VERSION ""

NS_ :

BS_:
BU_: MRR

BO_ 298 MRR_Detection_011: 64 MRR
   SG_ CAN_DET_CONFID_AZIMUTH_11_01 : 33|2@0+ (1,0) [0|3] "" IFV_VFP
   SG_ CAN_DET_SUPER_RES_TARGET_11_01 : 56|1@0+ (1,0) [0|1] "" IFV_VFP
   SG_ CAN_DET_NEW_SIGNAL_11_01 : 62|6@0+ (1,0) [0|64] "" IFV_VFP
   SG_ CAN_DET_ND_TARGET_11_01 : 48|1@0+ (1,0) [0|1] "" IFV_VFP
   SG_ CAN_DET_HOST_VEH_CLUTTER_11_01 : 49|1@0+ (1,0) [0|1] "" IFV_VFP
   SG_ CAN_DET_VALID_LEVEL_11_01 : 0|1@0+ (1,0) [0|1] "" IFV_VFP
   SG_ CAN_DET_AZIMUTH_11_01 : 47|14@0+ (0.0003834,-3.1416) [-3.1416|3.13964] "rad" IFV_VFP
   SG_ CAN_DET_RANGE_11_01 : 31|14@0+ (0.015625,0) [0|255.984] "m" IFV_VFP
   SG_ CAN_DET_RANGE_RATE_11_01 : 15|14@0+ (0.015625,-128) [-128|127.984] "m/s" IFV_VFP
   SG_ CAN_DET_AMPLITUDE_11_01 : 7|7@0+ (1,-64) [-64|63] "dBsm" IFV_VFP
   SG_ CAN_SCAN_INDEX_2LSB_11_01 : 17|2@0+ (1,0) [0|3] "" IFV_VFP
   SG_ CAN_DET_CONFID_AZIMUTH_11_02 : 105|2@0+ (1,0) [0|3] "" IFV_VFP
   SG_ CAN_DET_SUPER_RES_TARGET_11_02 : 128|1@0+ (1,0) [0|1] "" IFV_VFP
   SG_ CAN_DET_NEW_SIGNAL_11_02 : 134|6@0+ (1,0) [0|64] "" IFV_VFP
   SG_ CAN_DET_ND_TARGET_11_02 : 120|1@0+ (1,0) [0|1] "" IFV_VFP
   SG_ CAN_DET_HOST_VEH_CLUTTER_11_02 : 121|1@0+ (1,0) [0|1] "" IFV_VFP
   SG_ CAN_DET_VALID_LEVEL_11_02 : 72|1@0+ (1,0) [0|1] "" IFV_VFP
   SG_ CAN_DET_AZIMUTH_11_02 : 119|14@0+ (0.0003834,-3.1416) [-3.1416|3.13964] "rad" IFV_VFP
   SG_ CAN_DET_RANGE_11_02 : 103|14@0+ (0.015625,0) [0|255.984] "m" IFV_VFP
   SG_ CAN_DET_RANGE_RATE_11_02 : 87|14@0+ (0.015625,-128) [-128|127.984] "m/s" IFV_VFP
   SG_ CAN_DET_AMPLITUDE_11_02 : 79|7@0+ (1,-64) [-64|63] "dBsm" IFV_VFP
   SG_ CAN_SCAN_INDEX_2LSB_11_02 : 89|2@0+ (1,0) [0|3] "" IFV_VFP
   SG_ CAN_DET_CONFID_AZIMUTH_11_03 : 177|2@0+ (1,0) [0|3] "" IFV_VFP
   SG_ CAN_DET_SUPER_RES_TARGET_11_03 : 200|1@0+ (1,0) [0|1] "" IFV_VFP
   SG_ CAN_DET_NEW_SIGNAL_11_03 : 206|6@0+ (1,0) [0|64] "" IFV_VFP
   SG_ CAN_DET_ND_TARGET_11_03 : 192|1@0+ (1,0) [0|1] "" IFV_VFP
   SG_ CAN_DET_HOST_VEH_CLUTTER_11_03 : 193|1@0+ (1,0) [0|1] "" IFV_VFP
   SG_ CAN_DET_VALID_LEVEL_11_03 : 144|1@0+ (1,0) [0|1] "" IFV_VFP
   SG_ CAN_DET_AZIMUTH_11_03 : 191|14@0+ (0.0003834,-3.1416) [-3.1416|3.13964] "rad" IFV_VFP
   SG_ CAN_DET_RANGE_11_03 : 175|14@0+ (0.015625,0) [0|255.984] "m" IFV_VFP
   SG_ CAN_DET_RANGE_RATE_11_03 : 159|14@0+ (0.015625,-128) [-128|127.984] "m/s" IFV_VFP
   SG_ CAN_DET_AMPLITUDE_11_03 : 151|7@0+ (1,-64) [-64|63] "dBsm" IFV_VFP
   SG_ CAN_SCAN_INDEX_2LSB_11_03 : 161|2@0+ (1,0) [0|3] "" IFV_VFP
   SG_ CAN_DET_CONFID_AZIMUTH_11_04 : 249|2@0+ (1,0) [0|3] "" IFV_VFP
   SG_ CAN_DET_SUPER_RES_TARGET_11_04 : 272|1@0+ (1,0) [0|1] "" IFV_VFP
   SG_ CAN_DET_NEW_SIGNAL_11_04 : 278|6@0+ (1,0) [0|64] "" IFV_VFP
   SG_ CAN_DET_ND_TARGET_11_04 : 264|1@0+ (1,0) [0|1] "" IFV_VFP
   SG_ CAN_DET_HOST_VEH_CLUTTER_11_04 : 265|1@0+ (1,0) [0|1] "" IFV_VFP
   SG_ CAN_DET_VALID_LEVEL_11_04 : 216|1@0+ (1,0) [0|1] "" IFV_VFP
   SG_ CAN_DET_AZIMUTH_11_04 : 263|14@0+ (0.0003834,-3.1416) [-3.1416|3.13964] "rad" IFV_VFP
   SG_ CAN_DET_RANGE_11_04 : 247|14@0+ (0.015625,0) [0|255.984] "m" IFV_VFP
   SG_ CAN_DET_RANGE_RATE_11_04 : 231|14@0+ (0.015625,-128) [-128|127.984] "m/s" IFV_VFP
   SG_ CAN_DET_AMPLITUDE_11_04 : 223|7@0+ (1,-64) [-64|63] "dBsm" IFV_VFP
   SG_ CAN_SCAN_INDEX_2LSB_11_04 : 233|2@0+ (1,0) [0|3] "" IFV_VFP
   SG_ CAN_DET_CONFID_AZIMUTH_11_05 : 321|2@0+ (1,0) [0|3] "" IFV_VFP
   SG_ CAN_DET_SUPER_RES_TARGET_11_05 : 344|1@0+ (1,0) [0|1] "" IFV_VFP
   SG_ CAN_DET_NEW_SIGNAL_11_05 : 350|6@0+ (1,0) [0|64] "" IFV_VFP
   SG_ CAN_DET_ND_TARGET_11_05 : 336|1@0+ (1,0) [0|1] "" IFV_VFP
   SG_ CAN_DET_HOST_VEH_CLUTTER_11_05 : 337|1@0+ (1,0) [0|1] "" IFV_VFP
   SG_ CAN_DET_VALID_LEVEL_11_05 : 288|1@0+ (1,0) [0|1] "" IFV_VFP
   SG_ CAN_DET_AZIMUTH_11_05 : 335|14@0+ (0.0003834,-3.1416) [-3.1416|3.13964] "rad" IFV_VFP
   SG_ CAN_DET_RANGE_11_05 : 319|14@0+ (0.015625,0) [0|255.984] "m" IFV_VFP
   SG_ CAN_DET_RANGE_RATE_11_05 : 303|14@0+ (0.015625,-128) [-128|127.984] "m/s" IFV_VFP
   SG_ CAN_DET_AMPLITUDE_11_05 : 295|7@0+ (1,-64) [-64|63] "dBsm" IFV_VFP
   SG_ CAN_SCAN_INDEX_2LSB_11_05 : 305|2@0+ (1,0) [0|3] "" IFV_VFP
   SG_ CAN_DET_CONFID_AZIMUTH_11_06 : 393|2@0+ (1,0) [0|3] "" IFV_VFP
   SG_ CAN_DET_SUPER_RES_TARGET_11_06 : 416|1@0+ (1,0) [0|1] "" IFV_VFP
   SG_ CAN_DET_NEW_SIGNAL_11_06 : 422|6@0+ (1,0) [0|64] "" IFV_VFP
   SG_ CAN_DET_ND_TARGET_11_06 : 408|1@0+ (1,0) [0|1] "" IFV_VFP
   SG_ CAN_DET_HOST_VEH_CLUTTER_11_06 : 409|1@0+ (1,0) [0|1] "" IFV_VFP
   SG_ CAN_DET_VALID_LEVEL_11_06 : 360|1@0+ (1,0) [0|1] "" IFV_VFP
   SG_ CAN_DET_AZIMUTH_11_06 : 407|14@0+ (0.0003834,-3.1416) [-3.1416|3.13964] "rad" IFV_VFP
   SG_ CAN_DET_RANGE_11_06 : 391|14@0+ (0.015625,0) [0|255.984] "m" IFV_VFP
   SG_ CAN_DET_RANGE_RATE_11_06 : 375|14@0+ (0.015625,-128) [-128|127.984] "m/s" IFV_VFP
   SG_ CAN_DET_AMPLITUDE_11_06 : 367|7@0+ (1,-64) [-64|63] "dBsm" IFV_VFP
   SG_ CAN_SCAN_INDEX_2LSB_11_06 : 377|2@0+ (1,0) [0|3] "" IFV_VFP

BO_ 297 MRR_Detection_010: 64 MRR
   SG_ CAN_DET_CONFID_AZIMUTH_10_01 : 33|2@0+ (1,0) [0|3] "" IFV_VFP
   SG_ CAN_DET_SUPER_RES_TARGET_10_01 : 56|1@0+ (1,0) [0|1] "" IFV_VFP
   SG_ CAN_DET_NEW_SIGNAL_10_01 : 62|6@0+ (1,0) [0|64] "" IFV_VFP
   SG_ CAN_DET_ND_TARGET_10_01 : 48|1@0+ (1,0) [0|1] "" IFV_VFP
   SG_ CAN_DET_HOST_VEH_CLUTTER_10_01 : 49|1@0+ (1,0) [0|1] "" IFV_VFP
   SG_ CAN_DET_VALID_LEVEL_10_01 : 0|1@0+ (1,0) [0|1] "" IFV_VFP
   SG_ CAN_DET_AZIMUTH_10_01 : 47|14@0+ (0.0003834,-3.1416) [-3.1416|3.13964] "rad" IFV_VFP
   SG_ CAN_DET_RANGE_10_01 : 31|14@0+ (0.015625,0) [0|255.984] "m" IFV_VFP
   SG_ CAN_DET_RANGE_RATE_10_01 : 15|14@0+ (0.015625,-128) [-128|127.984] "m/s" IFV_VFP
   SG_ CAN_DET_AMPLITUDE_10_01 : 7|7@0+ (1,-64) [-64|63] "dBsm" IFV_VFP
   SG_ CAN_SCAN_INDEX_2LSB_10_01 : 17|2@0+ (1,0) [0|3] "" IFV_VFP
   SG_ CAN_DET_CONFID_AZIMUTH_10_02 : 105|2@0+ (1,0) [0|3] "" IFV_VFP
   SG_ CAN_DET_SUPER_RES_TARGET_10_02 : 128|1@0+ (1,0) [0|1] "" IFV_VFP
   SG_ CAN_DET_NEW_SIGNAL_10_02 : 134|6@0+ (1,0) [0|64] "" IFV_VFP
   SG_ CAN_DET_ND_TARGET_10_02 : 120|1@0+ (1,0) [0|1] "" IFV_VFP
   SG_ CAN_DET_HOST_VEH_CLUTTER_10_02 : 121|1@0+ (1,0) [0|1] "" IFV_VFP
   SG_ CAN_DET_VALID_LEVEL_10_02 : 72|1@0+ (1,0) [0|1] "" IFV_VFP
   SG_ CAN_DET_AZIMUTH_10_02 : 119|14@0+ (0.0003834,-3.1416) [-3.1416|3.13964] "rad" IFV_VFP
   SG_ CAN_DET_RANGE_10_02 : 103|14@0+ (0.015625,0) [0|255.984] "m" IFV_VFP
   SG_ CAN_DET_RANGE_RATE_10_02 : 87|14@0+ (0.015625,-128) [-128|127.984] "m/s" IFV_VFP
   SG_ CAN_DET_AMPLITUDE_10_02 : 79|7@0+ (1,-64) [-64|63] "dBsm" IFV_VFP
   SG_ CAN_SCAN_INDEX_2LSB_10_02 : 89|2@0+ (1,0) [0|3] "" IFV_VFP
   SG_ CAN_DET_CONFID_AZIMUTH_10_03 : 177|2@0+ (1,0) [0|3] "" IFV_VFP
   SG_ CAN_DET_SUPER_RES_TARGET_10_03 : 200|1@0+ (1,0) [0|1] "" IFV_VFP
   SG_ CAN_DET_NEW_SIGNAL_10_03 : 206|6@0+ (1,0) [0|64] "" IFV_VFP
   SG_ CAN_DET_ND_TARGET_10_03 : 192|1@0+ (1,0) [0|1] "" IFV_VFP
   SG_ CAN_DET_HOST_VEH_CLUTTER_10_03 : 193|1@0+ (1,0) [0|1] "" IFV_VFP
   SG_ CAN_DET_VALID_LEVEL_10_03 : 144|1@0+ (1,0) [0|1] "" IFV_VFP
   SG_ CAN_DET_AZIMUTH_10_03 : 191|14@0+ (0.0003834,-3.1416) [-3.1416|3.13964] "rad" IFV_VFP
   SG_ CAN_DET_RANGE_10_03 : 175|14@0+ (0.015625,0) [0|255.984] "m" IFV_VFP
   SG_ CAN_DET_RANGE_RATE_10_03 : 159|14@0+ (0.015625,-128) [-128|127.984] "m/s" IFV_VFP
   SG_ CAN_DET_AMPLITUDE_10_03 : 151|7@0+ (1,-64) [-64|63] "dBsm" IFV_VFP
   SG_ CAN_SCAN_INDEX_2LSB_10_03 : 161|2@0+ (1,0) [0|3] "" IFV_VFP
   SG_ CAN_DET_CONFID_AZIMUTH_10_04 : 249|2@0+ (1,0) [0|3] "" IFV_VFP
   SG_ CAN_DET_SUPER_RES_TARGET_10_04 : 272|1@0+ (1,0) [0|1] "" IFV_VFP
   SG_ CAN_DET_NEW_SIGNAL_10_04 : 278|6@0+ (1,0) [0|64] "" IFV_VFP
   SG_ CAN_DET_ND_TARGET_10_04 : 264|1@0+ (1,0) [0|1] "" IFV_VFP
   SG_ CAN_DET_HOST_VEH_CLUTTER_10_04 : 265|1@0+ (1,0) [0|1] "" IFV_VFP
   SG_ CAN_DET_VALID_LEVEL_10_04 : 216|1@0+ (1,0) [0|1] "" IFV_VFP
   SG_ CAN_DET_AZIMUTH_10_04 : 263|14@0+ (0.0003834,-3.1416) [-3.1416|3.13964] "rad" IFV_VFP
   SG_ CAN_DET_RANGE_10_04 : 247|14@0+ (0.015625,0) [0|255.984] "m" IFV_VFP
   SG_ CAN_DET_RANGE_RATE_10_04 : 231|14@0+ (0.015625,-128) [-128|127.984] "m/s" IFV_VFP
   SG_ CAN_DET_AMPLITUDE_10_04 : 223|7@0+ (1,-64) [-64|63] "dBsm" IFV_VFP
   SG_ CAN_SCAN_INDEX_2LSB_10_04 : 233|2@0+ (1,0) [0|3] "" IFV_VFP
   SG_ CAN_DET_CONFID_AZIMUTH_10_05 : 321|2@0+ (1,0) [0|3] "" IFV_VFP
   SG_ CAN_DET_SUPER_RES_TARGET_10_05 : 344|1@0+ (1,0) [0|1] "" IFV_VFP
   SG_ CAN_DET_NEW_SIGNAL_10_05 : 350|6@0+ (1,0) [0|64] "" IFV_VFP
   SG_ CAN_DET_ND_TARGET_10_05 : 336|1@0+ (1,0) [0|1] "" IFV_VFP
   SG_ CAN_DET_HOST_VEH_CLUTTER_10_05 : 337|1@0+ (1,0) [0|1] "" IFV_VFP
   SG_ CAN_DET_VALID_LEVEL_10_05 : 288|1@0+ (1,0) [0|1] "" IFV_VFP
   SG_ CAN_DET_AZIMUTH_10_05 : 335|14@0+ (0.0003834,-3.1416) [-3.1416|3.13964] "rad" IFV_VFP
   SG_ CAN_DET_RANGE_10_05 : 319|14@0+ (0.015625,0) [0|255.984] "m" IFV_VFP
   SG_ CAN_DET_RANGE_RATE_10_05 : 303|14@0+ (0.015625,-128) [-128|127.984] "m/s" IFV_VFP
   SG_ CAN_DET_AMPLITUDE_10_05 : 295|7@0+ (1,-64) [-64|63] "dBsm" IFV_VFP
   SG_ CAN_SCAN_INDEX_2LSB_10_05 : 305|2@0+ (1,0) [0|3] "" IFV_VFP
   SG_ CAN_DET_CONFID_AZIMUTH_10_06 : 393|2@0+ (1,0) [0|3] "" IFV_VFP
   SG_ CAN_DET_SUPER_RES_TARGET_10_06 : 416|1@0+ (1,0) [0|1] "" IFV_VFP
   SG_ CAN_DET_NEW_SIGNAL_10_06 : 422|6@0+ (1,0) [0|64] "" IFV_VFP
   SG_ CAN_DET_ND_TARGET_10_06 : 408|1@0+ (1,0) [0|1] "" IFV_VFP
   SG_ CAN_DET_HOST_VEH_CLUTTER_10_06 : 409|1@0+ (1,0) [0|1] "" IFV_VFP
   SG_ CAN_DET_VALID_LEVEL_10_06 : 360|1@0+ (1,0) [0|1] "" IFV_VFP
   SG_ CAN_DET_AZIMUTH_10_06 : 407|14@0+ (0.0003834,-3.1416) [-3.1416|3.13964] "rad" IFV_VFP
   SG_ CAN_DET_RANGE_10_06 : 391|14@0+ (0.015625,0) [0|255.984] "m" IFV_VFP
   SG_ CAN_DET_RANGE_RATE_10_06 : 375|14@0+ (0.015625,-128) [-128|127.984] "m/s" IFV_VFP
   SG_ CAN_DET_AMPLITUDE_10_06 : 367|7@0+ (1,-64) [-64|63] "dBsm" IFV_VFP
   SG_ CAN_SCAN_INDEX_2LSB_10_06 : 377|2@0+ (1,0) [0|3] "" IFV_VFP

BO_ 296 MRR_Detection_009: 64 MRR
   SG_ CAN_DET_CONFID_AZIMUTH_09_01 : 33|2@0+ (1,0) [0|3] "" IFV_VFP
   SG_ CAN_DET_SUPER_RES_TARGET_09_01 : 56|1@0+ (1,0) [0|1] "" IFV_VFP
   SG_ CAN_DET_NEW_SIGNAL_09_01 : 62|6@0+ (1,0) [0|64] "" IFV_VFP
   SG_ CAN_DET_ND_TARGET_09_01 : 48|1@0+ (1,0) [0|1] "" IFV_VFP
   SG_ CAN_DET_HOST_VEH_CLUTTER_09_01 : 49|1@0+ (1,0) [0|1] "" IFV_VFP
   SG_ CAN_DET_VALID_LEVEL_09_01 : 0|1@0+ (1,0) [0|1] "" IFV_VFP
   SG_ CAN_DET_AZIMUTH_09_01 : 47|14@0+ (0.0003834,-3.1416) [-3.1416|3.13964] "rad" IFV_VFP
   SG_ CAN_DET_RANGE_09_01 : 31|14@0+ (0.015625,0) [0|255.984] "m" IFV_VFP
   SG_ CAN_DET_RANGE_RATE_09_01 : 15|14@0+ (0.015625,-128) [-128|127.984] "m/s" IFV_VFP
   SG_ CAN_DET_AMPLITUDE_09_01 : 7|7@0+ (1,-64) [-64|63] "dBsm" IFV_VFP
   SG_ CAN_SCAN_INDEX_2LSB_09_01 : 17|2@0+ (1,0) [0|3] "" IFV_VFP
   SG_ CAN_DET_CONFID_AZIMUTH_09_02 : 105|2@0+ (1,0) [0|3] "" IFV_VFP
   SG_ CAN_DET_SUPER_RES_TARGET_09_02 : 128|1@0+ (1,0) [0|1] "" IFV_VFP
   SG_ CAN_DET_NEW_SIGNAL_09_02 : 134|6@0+ (1,0) [0|64] "" IFV_VFP
   SG_ CAN_DET_ND_TARGET_09_02 : 120|1@0+ (1,0) [0|1] "" IFV_VFP
   SG_ CAN_DET_HOST_VEH_CLUTTER_09_02 : 121|1@0+ (1,0) [0|1] "" IFV_VFP
   SG_ CAN_DET_VALID_LEVEL_09_02 : 72|1@0+ (1,0) [0|1] "" IFV_VFP
   SG_ CAN_DET_AZIMUTH_09_02 : 119|14@0+ (0.0003834,-3.1416) [-3.1416|3.13964] "rad" IFV_VFP
   SG_ CAN_DET_RANGE_09_02 : 103|14@0+ (0.015625,0) [0|255.984] "m" IFV_VFP
   SG_ CAN_DET_RANGE_RATE_09_02 : 87|14@0+ (0.015625,-128) [-128|127.984] "m/s" IFV_VFP
   SG_ CAN_DET_AMPLITUDE_09_02 : 79|7@0+ (1,-64) [-64|63] "dBsm" IFV_VFP
   SG_ CAN_SCAN_INDEX_2LSB_09_02 : 89|2@0+ (1,0) [0|3] "" IFV_VFP
   SG_ CAN_DET_CONFID_AZIMUTH_09_03 : 177|2@0+ (1,0) [0|3] "" IFV_VFP
   SG_ CAN_DET_SUPER_RES_TARGET_09_03 : 200|1@0+ (1,0) [0|1] "" IFV_VFP
   SG_ CAN_DET_NEW_SIGNAL_09_03 : 206|6@0+ (1,0) [0|64] "" IFV_VFP
   SG_ CAN_DET_ND_TARGET_09_03 : 192|1@0+ (1,0) [0|1] "" IFV_VFP
   SG_ CAN_DET_HOST_VEH_CLUTTER_09_03 : 193|1@0+ (1,0) [0|1] "" IFV_VFP
   SG_ CAN_DET_VALID_LEVEL_09_03 : 144|1@0+ (1,0) [0|1] "" IFV_VFP
   SG_ CAN_DET_AZIMUTH_09_03 : 191|14@0+ (0.0003834,-3.1416) [-3.1416|3.13964] "rad" IFV_VFP
   SG_ CAN_DET_RANGE_09_03 : 175|14@0+ (0.015625,0) [0|255.984] "m" IFV_VFP
   SG_ CAN_DET_RANGE_RATE_09_03 : 159|14@0+ (0.015625,-128) [-128|127.984] "m/s" IFV_VFP
   SG_ CAN_DET_AMPLITUDE_09_03 : 151|7@0+ (1,-64) [-64|63] "dBsm" IFV_VFP
   SG_ CAN_SCAN_INDEX_2LSB_09_03 : 161|2@0+ (1,0) [0|3] "" IFV_VFP
   SG_ CAN_DET_CONFID_AZIMUTH_09_04 : 249|2@0+ (1,0) [0|3] "" IFV_VFP
   SG_ CAN_DET_SUPER_RES_TARGET_09_04 : 272|1@0+ (1,0) [0|1] "" IFV_VFP
   SG_ CAN_DET_NEW_SIGNAL_09_04 : 278|6@0+ (1,0) [0|64] "" IFV_VFP
   SG_ CAN_DET_ND_TARGET_09_04 : 264|1@0+ (1,0) [0|1] "" IFV_VFP
   SG_ CAN_DET_HOST_VEH_CLUTTER_09_04 : 265|1@0+ (1,0) [0|1] "" IFV_VFP
   SG_ CAN_DET_VALID_LEVEL_09_04 : 216|1@0+ (1,0) [0|1] "" IFV_VFP
   SG_ CAN_DET_AZIMUTH_09_04 : 263|14@0+ (0.0003834,-3.1416) [-3.1416|3.13964] "rad" IFV_VFP
   SG_ CAN_DET_RANGE_09_04 : 247|14@0+ (0.015625,0) [0|255.984] "m" IFV_VFP
   SG_ CAN_DET_RANGE_RATE_09_04 : 231|14@0+ (0.015625,-128) [-128|127.984] "m/s" IFV_VFP
   SG_ CAN_DET_AMPLITUDE_09_04 : 223|7@0+ (1,-64) [-64|63] "dBsm" IFV_VFP
   SG_ CAN_SCAN_INDEX_2LSB_09_04 : 233|2@0+ (1,0) [0|3] "" IFV_VFP
   SG_ CAN_DET_CONFID_AZIMUTH_09_05 : 321|2@0+ (1,0) [0|3] "" IFV_VFP
   SG_ CAN_DET_SUPER_RES_TARGET_09_05 : 344|1@0+ (1,0) [0|1] "" IFV_VFP
   SG_ CAN_DET_NEW_SIGNAL_09_05 : 350|6@0+ (1,0) [0|64] "" IFV_VFP
   SG_ CAN_DET_ND_TARGET_09_05 : 336|1@0+ (1,0) [0|1] "" IFV_VFP
   SG_ CAN_DET_HOST_VEH_CLUTTER_09_05 : 337|1@0+ (1,0) [0|1] "" IFV_VFP
   SG_ CAN_DET_VALID_LEVEL_09_05 : 288|1@0+ (1,0) [0|1] "" IFV_VFP
   SG_ CAN_DET_AZIMUTH_09_05 : 335|14@0+ (0.0003834,-3.1416) [-3.1416|3.13964] "rad" IFV_VFP
   SG_ CAN_DET_RANGE_09_05 : 319|14@0+ (0.015625,0) [0|255.984] "m" IFV_VFP
   SG_ CAN_DET_RANGE_RATE_09_05 : 303|14@0+ (0.015625,-128) [-128|127.984] "m/s" IFV_VFP
   SG_ CAN_DET_AMPLITUDE_09_05 : 295|7@0+ (1,-64) [-64|63] "dBsm" IFV_VFP
   SG_ CAN_SCAN_INDEX_2LSB_09_05 : 305|2@0+ (1,0) [0|3] "" IFV_VFP
   SG_ CAN_DET_CONFID_AZIMUTH_09_06 : 393|2@0+ (1,0) [0|3] "" IFV_VFP
   SG_ CAN_DET_SUPER_RES_TARGET_09_06 : 416|1@0+ (1,0) [0|1] "" IFV_VFP
   SG_ CAN_DET_NEW_SIGNAL_09_06 : 422|6@0+ (1,0) [0|64] "" IFV_VFP
   SG_ CAN_DET_ND_TARGET_09_06 : 408|1@0+ (1,0) [0|1] "" IFV_VFP
   SG_ CAN_DET_HOST_VEH_CLUTTER_09_06 : 409|1@0+ (1,0) [0|1] "" IFV_VFP
   SG_ CAN_DET_VALID_LEVEL_09_06 : 360|1@0+ (1,0) [0|1] "" IFV_VFP
   SG_ CAN_DET_AZIMUTH_09_06 : 407|14@0+ (0.0003834,-3.1416) [-3.1416|3.13964] "rad" IFV_VFP
   SG_ CAN_DET_RANGE_09_06 : 391|14@0+ (0.015625,0) [0|255.984] "m" IFV_VFP
   SG_ CAN_DET_RANGE_RATE_09_06 : 375|14@0+ (0.015625,-128) [-128|127.984] "m/s" IFV_VFP
   SG_ CAN_DET_AMPLITUDE_09_06 : 367|7@0+ (1,-64) [-64|63] "dBsm" IFV_VFP
   SG_ CAN_SCAN_INDEX_2LSB_09_06 : 377|2@0+ (1,0) [0|3] "" IFV_VFP

BO_ 295 MRR_Detection_008: 64 MRR
   SG_ CAN_DET_CONFID_AZIMUTH_08_01 : 33|2@0+ (1,0) [0|3] "" IFV_VFP
   SG_ CAN_DET_SUPER_RES_TARGET_08_01 : 56|1@0+ (1,0) [0|1] "" IFV_VFP
   SG_ CAN_DET_NEW_SIGNAL_08_01 : 62|6@0+ (1,0) [0|64] "" IFV_VFP
   SG_ CAN_DET_ND_TARGET_08_01 : 48|1@0+ (1,0) [0|1] "" IFV_VFP
   SG_ CAN_DET_HOST_VEH_CLUTTER_08_01 : 49|1@0+ (1,0) [0|1] "" IFV_VFP
   SG_ CAN_DET_VALID_LEVEL_08_01 : 0|1@0+ (1,0) [0|1] "" IFV_VFP
   SG_ CAN_DET_AZIMUTH_08_01 : 47|14@0+ (0.0003834,-3.1416) [-3.1416|3.13964] "rad" IFV_VFP
   SG_ CAN_DET_RANGE_08_01 : 31|14@0+ (0.015625,0) [0|255.984] "m" IFV_VFP
   SG_ CAN_DET_RANGE_RATE_08_01 : 15|14@0+ (0.015625,-128) [-128|127.984] "m/s" IFV_VFP
   SG_ CAN_DET_AMPLITUDE_08_01 : 7|7@0+ (1,-64) [-64|63] "dBsm" IFV_VFP
   SG_ CAN_SCAN_INDEX_2LSB_08_01 : 17|2@0+ (1,0) [0|3] "" IFV_VFP
   SG_ CAN_DET_CONFID_AZIMUTH_08_02 : 105|2@0+ (1,0) [0|3] "" IFV_VFP
   SG_ CAN_DET_SUPER_RES_TARGET_08_02 : 128|1@0+ (1,0) [0|1] "" IFV_VFP
   SG_ CAN_DET_NEW_SIGNAL_08_02 : 134|6@0+ (1,0) [0|64] "" IFV_VFP
   SG_ CAN_DET_ND_TARGET_08_02 : 120|1@0+ (1,0) [0|1] "" IFV_VFP
   SG_ CAN_DET_HOST_VEH_CLUTTER_08_02 : 121|1@0+ (1,0) [0|1] "" IFV_VFP
   SG_ CAN_DET_VALID_LEVEL_08_02 : 72|1@0+ (1,0) [0|1] "" IFV_VFP
   SG_ CAN_DET_AZIMUTH_08_02 : 119|14@0+ (0.0003834,-3.1416) [-3.1416|3.13964] "rad" IFV_VFP
   SG_ CAN_DET_RANGE_08_02 : 103|14@0+ (0.015625,0) [0|255.984] "m" IFV_VFP
   SG_ CAN_DET_RANGE_RATE_08_02 : 87|14@0+ (0.015625,-128) [-128|127.984] "m/s" IFV_VFP
   SG_ CAN_DET_AMPLITUDE_08_02 : 79|7@0+ (1,-64) [-64|63] "dBsm" IFV_VFP
   SG_ CAN_SCAN_INDEX_2LSB_08_02 : 89|2@0+ (1,0) [0|3] "" IFV_VFP
   SG_ CAN_DET_CONFID_AZIMUTH_08_03 : 177|2@0+ (1,0) [0|3] "" IFV_VFP
   SG_ CAN_DET_SUPER_RES_TARGET_08_03 : 200|1@0+ (1,0) [0|1] "" IFV_VFP
   SG_ CAN_DET_NEW_SIGNAL_08_03 : 206|6@0+ (1,0) [0|64] "" IFV_VFP
   SG_ CAN_DET_ND_TARGET_08_03 : 192|1@0+ (1,0) [0|1] "" IFV_VFP
   SG_ CAN_DET_HOST_VEH_CLUTTER_08_03 : 193|1@0+ (1,0) [0|1] "" IFV_VFP
   SG_ CAN_DET_VALID_LEVEL_08_03 : 144|1@0+ (1,0) [0|1] "" IFV_VFP
   SG_ CAN_DET_AZIMUTH_08_03 : 191|14@0+ (0.0003834,-3.1416) [-3.1416|3.13964] "rad" IFV_VFP
   SG_ CAN_DET_RANGE_08_03 : 175|14@0+ (0.015625,0) [0|255.984] "m" IFV_VFP
   SG_ CAN_DET_RANGE_RATE_08_03 : 159|14@0+ (0.015625,-128) [-128|127.984] "m/s" IFV_VFP
   SG_ CAN_DET_AMPLITUDE_08_03 : 151|7@0+ (1,-64) [-64|63] "dBsm" IFV_VFP
   SG_ CAN_SCAN_INDEX_2LSB_08_03 : 161|2@0+ (1,0) [0|3] "" IFV_VFP
   SG_ CAN_DET_CONFID_AZIMUTH_08_04 : 249|2@0+ (1,0) [0|3] "" IFV_VFP
   SG_ CAN_DET_SUPER_RES_TARGET_08_04 : 272|1@0+ (1,0) [0|1] "" IFV_VFP
   SG_ CAN_DET_NEW_SIGNAL_08_04 : 278|6@0+ (1,0) [0|64] "" IFV_VFP
   SG_ CAN_DET_ND_TARGET_08_04 : 264|1@0+ (1,0) [0|1] "" IFV_VFP
   SG_ CAN_DET_HOST_VEH_CLUTTER_08_04 : 265|1@0+ (1,0) [0|1] "" IFV_VFP
   SG_ CAN_DET_VALID_LEVEL_08_04 : 216|1@0+ (1,0) [0|1] "" IFV_VFP
   SG_ CAN_DET_AZIMUTH_08_04 : 263|14@0+ (0.0003834,-3.1416) [-3.1416|3.13964] "rad" IFV_VFP
   SG_ CAN_DET_RANGE_08_04 : 247|14@0+ (0.015625,0) [0|255.984] "m" IFV_VFP
   SG_ CAN_DET_RANGE_RATE_08_04 : 231|14@0+ (0.015625,-128) [-128|127.984] "m/s" IFV_VFP
   SG_ CAN_DET_AMPLITUDE_08_04 : 223|7@0+ (1,-64) [-64|63] "dBsm" IFV_VFP
   SG_ CAN_SCAN_INDEX_2LSB_08_04 : 233|2@0+ (1,0) [0|3] "" IFV_VFP
   SG_ CAN_DET_CONFID_AZIMUTH_08_05 : 321|2@0+ (1,0) [0|3] "" IFV_VFP
   SG_ CAN_DET_SUPER_RES_TARGET_08_05 : 344|1@0+ (1,0) [0|1] "" IFV_VFP
   SG_ CAN_DET_NEW_SIGNAL_08_05 : 350|6@0+ (1,0) [0|64] "" IFV_VFP
   SG_ CAN_DET_ND_TARGET_08_05 : 336|1@0+ (1,0) [0|1] "" IFV_VFP
   SG_ CAN_DET_HOST_VEH_CLUTTER_08_05 : 337|1@0+ (1,0) [0|1] "" IFV_VFP
   SG_ CAN_DET_VALID_LEVEL_08_05 : 288|1@0+ (1,0) [0|1] "" IFV_VFP
   SG_ CAN_DET_AZIMUTH_08_05 : 335|14@0+ (0.0003834,-3.1416) [-3.1416|3.13964] "rad" IFV_VFP
   SG_ CAN_DET_RANGE_08_05 : 319|14@0+ (0.015625,0) [0|255.984] "m" IFV_VFP
   SG_ CAN_DET_RANGE_RATE_08_05 : 303|14@0+ (0.015625,-128) [-128|127.984] "m/s" IFV_VFP
   SG_ CAN_DET_AMPLITUDE_08_05 : 295|7@0+ (1,-64) [-64|63] "dBsm" IFV_VFP
   SG_ CAN_SCAN_INDEX_2LSB_08_05 : 305|2@0+ (1,0) [0|3] "" IFV_VFP
   SG_ CAN_DET_CONFID_AZIMUTH_08_06 : 393|2@0+ (1,0) [0|3] "" IFV_VFP
   SG_ CAN_DET_SUPER_RES_TARGET_08_06 : 416|1@0+ (1,0) [0|1] "" IFV_VFP
   SG_ CAN_DET_NEW_SIGNAL_08_06 : 422|6@0+ (1,0) [0|64] "" IFV_VFP
   SG_ CAN_DET_ND_TARGET_08_06 : 408|1@0+ (1,0) [0|1] "" IFV_VFP
   SG_ CAN_DET_HOST_VEH_CLUTTER_08_06 : 409|1@0+ (1,0) [0|1] "" IFV_VFP
   SG_ CAN_DET_VALID_LEVEL_08_06 : 360|1@0+ (1,0) [0|1] "" IFV_VFP
   SG_ CAN_DET_AZIMUTH_08_06 : 407|14@0+ (0.0003834,-3.1416) [-3.1416|3.13964] "rad" IFV_VFP
   SG_ CAN_DET_RANGE_08_06 : 391|14@0+ (0.015625,0) [0|255.984] "m" IFV_VFP
   SG_ CAN_DET_RANGE_RATE_08_06 : 375|14@0+ (0.015625,-128) [-128|127.984] "m/s" IFV_VFP
   SG_ CAN_DET_AMPLITUDE_08_06 : 367|7@0+ (1,-64) [-64|63] "dBsm" IFV_VFP
   SG_ CAN_SCAN_INDEX_2LSB_08_06 : 377|2@0+ (1,0) [0|3] "" IFV_VFP

BO_ 294 MRR_Detection_007: 64 MRR
   SG_ CAN_DET_CONFID_AZIMUTH_07_01 : 33|2@0+ (1,0) [0|3] "" IFV_VFP
   SG_ CAN_DET_SUPER_RES_TARGET_07_01 : 56|1@0+ (1,0) [0|1] "" IFV_VFP
   SG_ CAN_DET_NEW_SIGNAL_07_01 : 62|6@0+ (1,0) [0|64] "" IFV_VFP
   SG_ CAN_DET_ND_TARGET_07_01 : 48|1@0+ (1,0) [0|1] "" IFV_VFP
   SG_ CAN_DET_HOST_VEH_CLUTTER_07_01 : 49|1@0+ (1,0) [0|1] "" IFV_VFP
   SG_ CAN_DET_VALID_LEVEL_07_01 : 0|1@0+ (1,0) [0|1] "" IFV_VFP
   SG_ CAN_DET_AZIMUTH_07_01 : 47|14@0+ (0.0003834,-3.1416) [-3.1416|3.13964] "rad" IFV_VFP
   SG_ CAN_DET_RANGE_07_01 : 31|14@0+ (0.015625,0) [0|255.984] "m" IFV_VFP
   SG_ CAN_DET_RANGE_RATE_07_01 : 15|14@0+ (0.015625,-128) [-128|127.984] "m/s" IFV_VFP
   SG_ CAN_DET_AMPLITUDE_07_01 : 7|7@0+ (1,-64) [-64|63] "dBsm" IFV_VFP
   SG_ CAN_SCAN_INDEX_2LSB_07_01 : 17|2@0+ (1,0) [0|3] "" IFV_VFP
   SG_ CAN_DET_CONFID_AZIMUTH_07_02 : 105|2@0+ (1,0) [0|3] "" IFV_VFP
   SG_ CAN_DET_SUPER_RES_TARGET_07_02 : 128|1@0+ (1,0) [0|1] "" IFV_VFP
   SG_ CAN_DET_NEW_SIGNAL_07_02 : 134|6@0+ (1,0) [0|64] "" IFV_VFP
   SG_ CAN_DET_ND_TARGET_07_02 : 120|1@0+ (1,0) [0|1] "" IFV_VFP
   SG_ CAN_DET_HOST_VEH_CLUTTER_07_02 : 121|1@0+ (1,0) [0|1] "" IFV_VFP
   SG_ CAN_DET_VALID_LEVEL_07_02 : 72|1@0+ (1,0) [0|1] "" IFV_VFP
   SG_ CAN_DET_AZIMUTH_07_02 : 119|14@0+ (0.0003834,-3.1416) [-3.1416|3.13964] "rad" IFV_VFP
   SG_ CAN_DET_RANGE_07_02 : 103|14@0+ (0.015625,0) [0|255.984] "m" IFV_VFP
   SG_ CAN_DET_RANGE_RATE_07_02 : 87|14@0+ (0.015625,-128) [-128|127.984] "m/s" IFV_VFP
   SG_ CAN_DET_AMPLITUDE_07_02 : 79|7@0+ (1,-64) [-64|63] "dBsm" IFV_VFP
   SG_ CAN_SCAN_INDEX_2LSB_07_02 : 89|2@0+ (1,0) [0|3] "" IFV_VFP
   SG_ CAN_DET_CONFID_AZIMUTH_07_03 : 177|2@0+ (1,0) [0|3] "" IFV_VFP
   SG_ CAN_DET_SUPER_RES_TARGET_07_03 : 200|1@0+ (1,0) [0|1] "" IFV_VFP
   SG_ CAN_DET_NEW_SIGNAL_07_03 : 206|6@0+ (1,0) [0|64] "" IFV_VFP
   SG_ CAN_DET_ND_TARGET_07_03 : 192|1@0+ (1,0) [0|1] "" IFV_VFP
   SG_ CAN_DET_HOST_VEH_CLUTTER_07_03 : 193|1@0+ (1,0) [0|1] "" IFV_VFP
   SG_ CAN_DET_VALID_LEVEL_07_03 : 144|1@0+ (1,0) [0|1] "" IFV_VFP
   SG_ CAN_DET_AZIMUTH_07_03 : 191|14@0+ (0.0003834,-3.1416) [-3.1416|3.13964] "rad" IFV_VFP
   SG_ CAN_DET_RANGE_07_03 : 175|14@0+ (0.015625,0) [0|255.984] "m" IFV_VFP
   SG_ CAN_DET_RANGE_RATE_07_03 : 159|14@0+ (0.015625,-128) [-128|127.984] "m/s" IFV_VFP
   SG_ CAN_DET_AMPLITUDE_07_03 : 151|7@0+ (1,-64) [-64|63] "dBsm" IFV_VFP
   SG_ CAN_SCAN_INDEX_2LSB_07_03 : 161|2@0+ (1,0) [0|3] "" IFV_VFP
   SG_ CAN_DET_CONFID_AZIMUTH_07_04 : 249|2@0+ (1,0) [0|3] "" IFV_VFP
   SG_ CAN_DET_SUPER_RES_TARGET_07_04 : 272|1@0+ (1,0) [0|1] "" IFV_VFP
   SG_ CAN_DET_NEW_SIGNAL_07_04 : 278|6@0+ (1,0) [0|64] "" IFV_VFP
   SG_ CAN_DET_ND_TARGET_07_04 : 264|1@0+ (1,0) [0|1] "" IFV_VFP
   SG_ CAN_DET_HOST_VEH_CLUTTER_07_04 : 265|1@0+ (1,0) [0|1] "" IFV_VFP
   SG_ CAN_DET_VALID_LEVEL_07_04 : 216|1@0+ (1,0) [0|1] "" IFV_VFP
   SG_ CAN_DET_AZIMUTH_07_04 : 263|14@0+ (0.0003834,-3.1416) [-3.1416|3.13964] "rad" IFV_VFP
   SG_ CAN_DET_RANGE_07_04 : 247|14@0+ (0.015625,0) [0|255.984] "m" IFV_VFP
   SG_ CAN_DET_RANGE_RATE_07_04 : 231|14@0+ (0.015625,-128) [-128|127.984] "m/s" IFV_VFP
   SG_ CAN_DET_AMPLITUDE_07_04 : 223|7@0+ (1,-64) [-64|63] "dBsm" IFV_VFP
   SG_ CAN_SCAN_INDEX_2LSB_07_04 : 233|2@0+ (1,0) [0|3] "" IFV_VFP
   SG_ CAN_DET_CONFID_AZIMUTH_07_05 : 321|2@0+ (1,0) [0|3] "" IFV_VFP
   SG_ CAN_DET_SUPER_RES_TARGET_07_05 : 344|1@0+ (1,0) [0|1] "" IFV_VFP
   SG_ CAN_DET_NEW_SIGNAL_07_05 : 350|6@0+ (1,0) [0|64] "" IFV_VFP
   SG_ CAN_DET_ND_TARGET_07_05 : 336|1@0+ (1,0) [0|1] "" IFV_VFP
   SG_ CAN_DET_HOST_VEH_CLUTTER_07_05 : 337|1@0+ (1,0) [0|1] "" IFV_VFP
   SG_ CAN_DET_VALID_LEVEL_07_05 : 288|1@0+ (1,0) [0|1] "" IFV_VFP
   SG_ CAN_DET_AZIMUTH_07_05 : 335|14@0+ (0.0003834,-3.1416) [-3.1416|3.13964] "rad" IFV_VFP
   SG_ CAN_DET_RANGE_07_05 : 319|14@0+ (0.015625,0) [0|255.984] "m" IFV_VFP
   SG_ CAN_DET_RANGE_RATE_07_05 : 303|14@0+ (0.015625,-128) [-128|127.984] "m/s" IFV_VFP
   SG_ CAN_DET_AMPLITUDE_07_05 : 295|7@0+ (1,-64) [-64|63] "dBsm" IFV_VFP
   SG_ CAN_SCAN_INDEX_2LSB_07_05 : 305|2@0+ (1,0) [0|3] "" IFV_VFP
   SG_ CAN_DET_CONFID_AZIMUTH_07_06 : 393|2@0+ (1,0) [0|3] "" IFV_VFP
   SG_ CAN_DET_SUPER_RES_TARGET_07_06 : 416|1@0+ (1,0) [0|1] "" IFV_VFP
   SG_ CAN_DET_NEW_SIGNAL_07_06 : 422|6@0+ (1,0) [0|64] "" IFV_VFP
   SG_ CAN_DET_ND_TARGET_07_06 : 408|1@0+ (1,0) [0|1] "" IFV_VFP
   SG_ CAN_DET_HOST_VEH_CLUTTER_07_06 : 409|1@0+ (1,0) [0|1] "" IFV_VFP
   SG_ CAN_DET_VALID_LEVEL_07_06 : 360|1@0+ (1,0) [0|1] "" IFV_VFP
   SG_ CAN_DET_AZIMUTH_07_06 : 407|14@0+ (0.0003834,-3.1416) [-3.1416|3.13964] "rad" IFV_VFP
   SG_ CAN_DET_RANGE_07_06 : 391|14@0+ (0.015625,0) [0|255.984] "m" IFV_VFP
   SG_ CAN_DET_RANGE_RATE_07_06 : 375|14@0+ (0.015625,-128) [-128|127.984] "m/s" IFV_VFP
   SG_ CAN_DET_AMPLITUDE_07_06 : 367|7@0+ (1,-64) [-64|63] "dBsm" IFV_VFP
   SG_ CAN_SCAN_INDEX_2LSB_07_06 : 377|2@0+ (1,0) [0|3] "" IFV_VFP

BO_ 293 MRR_Detection_006: 64 MRR
   SG_ CAN_DET_CONFID_AZIMUTH_06_01 : 33|2@0+ (1,0) [0|3] "" IFV_VFP
   SG_ CAN_DET_SUPER_RES_TARGET_06_01 : 56|1@0+ (1,0) [0|1] "" IFV_VFP
   SG_ CAN_DET_NEW_SIGNAL_06_01 : 62|6@0+ (1,0) [0|64] "" IFV_VFP
   SG_ CAN_DET_ND_TARGET_06_01 : 48|1@0+ (1,0) [0|1] "" IFV_VFP
   SG_ CAN_DET_HOST_VEH_CLUTTER_06_01 : 49|1@0+ (1,0) [0|1] "" IFV_VFP
   SG_ CAN_DET_VALID_LEVEL_06_01 : 0|1@0+ (1,0) [0|1] "" IFV_VFP
   SG_ CAN_DET_AZIMUTH_06_01 : 47|14@0+ (0.0003834,-3.1416) [-3.1416|3.13964] "rad" IFV_VFP
   SG_ CAN_DET_RANGE_06_01 : 31|14@0+ (0.015625,0) [0|255.984] "m" IFV_VFP
   SG_ CAN_DET_RANGE_RATE_06_01 : 15|14@0+ (0.015625,-128) [-128|127.984] "m/s" IFV_VFP
   SG_ CAN_DET_AMPLITUDE_06_01 : 7|7@0+ (1,-64) [-64|63] "dBsm" IFV_VFP
   SG_ CAN_SCAN_INDEX_2LSB_06_01 : 17|2@0+ (1,0) [0|3] "" IFV_VFP
   SG_ CAN_DET_CONFID_AZIMUTH_06_02 : 105|2@0+ (1,0) [0|3] "" IFV_VFP
   SG_ CAN_DET_SUPER_RES_TARGET_06_02 : 128|1@0+ (1,0) [0|1] "" IFV_VFP
   SG_ CAN_DET_NEW_SIGNAL_06_02 : 134|6@0+ (1,0) [0|64] "" IFV_VFP
   SG_ CAN_DET_ND_TARGET_06_02 : 120|1@0+ (1,0) [0|1] "" IFV_VFP
   SG_ CAN_DET_HOST_VEH_CLUTTER_06_02 : 121|1@0+ (1,0) [0|1] "" IFV_VFP
   SG_ CAN_DET_VALID_LEVEL_06_02 : 72|1@0+ (1,0) [0|1] "" IFV_VFP
   SG_ CAN_DET_AZIMUTH_06_02 : 119|14@0+ (0.0003834,-3.1416) [-3.1416|3.13964] "rad" IFV_VFP
   SG_ CAN_DET_RANGE_06_02 : 103|14@0+ (0.015625,0) [0|255.984] "m" IFV_VFP
   SG_ CAN_DET_RANGE_RATE_06_02 : 87|14@0+ (0.015625,-128) [-128|127.984] "m/s" IFV_VFP
   SG_ CAN_DET_AMPLITUDE_06_02 : 79|7@0+ (1,-64) [-64|63] "dBsm" IFV_VFP
   SG_ CAN_SCAN_INDEX_2LSB_06_02 : 89|2@0+ (1,0) [0|3] "" IFV_VFP
   SG_ CAN_DET_CONFID_AZIMUTH_06_03 : 177|2@0+ (1,0) [0|3] "" IFV_VFP
   SG_ CAN_DET_SUPER_RES_TARGET_06_03 : 200|1@0+ (1,0) [0|1] "" IFV_VFP
   SG_ CAN_DET_NEW_SIGNAL_06_03 : 206|6@0+ (1,0) [0|64] "" IFV_VFP
   SG_ CAN_DET_ND_TARGET_06_03 : 192|1@0+ (1,0) [0|1] "" IFV_VFP
   SG_ CAN_DET_HOST_VEH_CLUTTER_06_03 : 193|1@0+ (1,0) [0|1] "" IFV_VFP
   SG_ CAN_DET_VALID_LEVEL_06_03 : 144|1@0+ (1,0) [0|1] "" IFV_VFP
   SG_ CAN_DET_AZIMUTH_06_03 : 191|14@0+ (0.0003834,-3.1416) [-3.1416|3.13964] "rad" IFV_VFP
   SG_ CAN_DET_RANGE_06_03 : 175|14@0+ (0.015625,0) [0|255.984] "m" IFV_VFP
   SG_ CAN_DET_RANGE_RATE_06_03 : 159|14@0+ (0.015625,-128) [-128|127.984] "m/s" IFV_VFP
   SG_ CAN_DET_AMPLITUDE_06_03 : 151|7@0+ (1,-64) [-64|63] "dBsm" IFV_VFP
   SG_ CAN_SCAN_INDEX_2LSB_06_03 : 161|2@0+ (1,0) [0|3] "" IFV_VFP
   SG_ CAN_DET_CONFID_AZIMUTH_06_04 : 249|2@0+ (1,0) [0|3] "" IFV_VFP
   SG_ CAN_DET_SUPER_RES_TARGET_06_04 : 272|1@0+ (1,0) [0|1] "" IFV_VFP
   SG_ CAN_DET_NEW_SIGNAL_06_04 : 278|6@0+ (1,0) [0|64] "" IFV_VFP
   SG_ CAN_DET_ND_TARGET_06_04 : 264|1@0+ (1,0) [0|1] "" IFV_VFP
   SG_ CAN_DET_HOST_VEH_CLUTTER_06_04 : 265|1@0+ (1,0) [0|1] "" IFV_VFP
   SG_ CAN_DET_VALID_LEVEL_06_04 : 216|1@0+ (1,0) [0|1] "" IFV_VFP
   SG_ CAN_DET_AZIMUTH_06_04 : 263|14@0+ (0.0003834,-3.1416) [-3.1416|3.13964] "rad" IFV_VFP
   SG_ CAN_DET_RANGE_06_04 : 247|14@0+ (0.015625,0) [0|255.984] "m" IFV_VFP
   SG_ CAN_DET_RANGE_RATE_06_04 : 231|14@0+ (0.015625,-128) [-128|127.984] "m/s" IFV_VFP
   SG_ CAN_DET_AMPLITUDE_06_04 : 223|7@0+ (1,-64) [-64|63] "dBsm" IFV_VFP
   SG_ CAN_SCAN_INDEX_2LSB_06_04 : 233|2@0+ (1,0) [0|3] "" IFV_VFP
   SG_ CAN_DET_CONFID_AZIMUTH_06_05 : 321|2@0+ (1,0) [0|3] "" IFV_VFP
   SG_ CAN_DET_SUPER_RES_TARGET_06_05 : 344|1@0+ (1,0) [0|1] "" IFV_VFP
   SG_ CAN_DET_NEW_SIGNAL_06_05 : 350|6@0+ (1,0) [0|64] "" IFV_VFP
   SG_ CAN_DET_ND_TARGET_06_05 : 336|1@0+ (1,0) [0|1] "" IFV_VFP
   SG_ CAN_DET_HOST_VEH_CLUTTER_06_05 : 337|1@0+ (1,0) [0|1] "" IFV_VFP
   SG_ CAN_DET_VALID_LEVEL_06_05 : 288|1@0+ (1,0) [0|1] "" IFV_VFP
   SG_ CAN_DET_AZIMUTH_06_05 : 335|14@0+ (0.0003834,-3.1416) [-3.1416|3.13964] "rad" IFV_VFP
   SG_ CAN_DET_RANGE_06_05 : 319|14@0+ (0.015625,0) [0|255.984] "m" IFV_VFP
   SG_ CAN_DET_RANGE_RATE_06_05 : 303|14@0+ (0.015625,-128) [-128|127.984] "m/s" IFV_VFP
   SG_ CAN_DET_AMPLITUDE_06_05 : 295|7@0+ (1,-64) [-64|63] "dBsm" IFV_VFP
   SG_ CAN_SCAN_INDEX_2LSB_06_05 : 305|2@0+ (1,0) [0|3] "" IFV_VFP
   SG_ CAN_DET_CONFID_AZIMUTH_06_06 : 393|2@0+ (1,0) [0|3] "" IFV_VFP
   SG_ CAN_DET_SUPER_RES_TARGET_06_06 : 416|1@0+ (1,0) [0|1] "" IFV_VFP
   SG_ CAN_DET_NEW_SIGNAL_06_06 : 422|6@0+ (1,0) [0|64] "" IFV_VFP
   SG_ CAN_DET_ND_TARGET_06_06 : 408|1@0+ (1,0) [0|1] "" IFV_VFP
   SG_ CAN_DET_HOST_VEH_CLUTTER_06_06 : 409|1@0+ (1,0) [0|1] "" IFV_VFP
   SG_ CAN_DET_VALID_LEVEL_06_06 : 360|1@0+ (1,0) [0|1] "" IFV_VFP
   SG_ CAN_DET_AZIMUTH_06_06 : 407|14@0+ (0.0003834,-3.1416) [-3.1416|3.13964] "rad" IFV_VFP
   SG_ CAN_DET_RANGE_06_06 : 391|14@0+ (0.015625,0) [0|255.984] "m" IFV_VFP
   SG_ CAN_DET_RANGE_RATE_06_06 : 375|14@0+ (0.015625,-128) [-128|127.984] "m/s" IFV_VFP
   SG_ CAN_DET_AMPLITUDE_06_06 : 367|7@0+ (1,-64) [-64|63] "dBsm" IFV_VFP
   SG_ CAN_SCAN_INDEX_2LSB_06_06 : 377|2@0+ (1,0) [0|3] "" IFV_VFP

BO_ 292 MRR_Detection_005: 64 MRR
   SG_ CAN_DET_CONFID_AZIMUTH_05_01 : 33|2@0+ (1,0) [0|3] "" IFV_VFP
   SG_ CAN_DET_SUPER_RES_TARGET_05_01 : 56|1@0+ (1,0) [0|1] "" IFV_VFP
   SG_ CAN_DET_NEW_SIGNAL_05_01 : 62|6@0+ (1,0) [0|64] "" IFV_VFP
   SG_ CAN_DET_ND_TARGET_05_01 : 48|1@0+ (1,0) [0|1] "" IFV_VFP
   SG_ CAN_DET_HOST_VEH_CLUTTER_05_01 : 49|1@0+ (1,0) [0|1] "" IFV_VFP
   SG_ CAN_DET_VALID_LEVEL_05_01 : 0|1@0+ (1,0) [0|1] "" IFV_VFP
   SG_ CAN_DET_AZIMUTH_05_01 : 47|14@0+ (0.0003834,-3.1416) [-3.1416|3.13964] "rad" IFV_VFP
   SG_ CAN_DET_RANGE_05_01 : 31|14@0+ (0.015625,0) [0|255.984] "m" IFV_VFP
   SG_ CAN_DET_RANGE_RATE_05_01 : 15|14@0+ (0.015625,-128) [-128|127.984] "m/s" IFV_VFP
   SG_ CAN_DET_AMPLITUDE_05_01 : 7|7@0+ (1,-64) [-64|63] "dBsm" IFV_VFP
   SG_ CAN_SCAN_INDEX_2LSB_05_01 : 17|2@0+ (1,0) [0|3] "" IFV_VFP
   SG_ CAN_DET_CONFID_AZIMUTH_05_02 : 105|2@0+ (1,0) [0|3] "" IFV_VFP
   SG_ CAN_DET_SUPER_RES_TARGET_05_02 : 128|1@0+ (1,0) [0|1] "" IFV_VFP
   SG_ CAN_DET_NEW_SIGNAL_05_02 : 134|6@0+ (1,0) [0|64] "" IFV_VFP
   SG_ CAN_DET_ND_TARGET_05_02 : 120|1@0+ (1,0) [0|1] "" IFV_VFP
   SG_ CAN_DET_HOST_VEH_CLUTTER_05_02 : 121|1@0+ (1,0) [0|1] "" IFV_VFP
   SG_ CAN_DET_VALID_LEVEL_05_02 : 72|1@0+ (1,0) [0|1] "" IFV_VFP
   SG_ CAN_DET_AZIMUTH_05_02 : 119|14@0+ (0.0003834,-3.1416) [-3.1416|3.13964] "rad" IFV_VFP
   SG_ CAN_DET_RANGE_05_02 : 103|14@0+ (0.015625,0) [0|255.984] "m" IFV_VFP
   SG_ CAN_DET_RANGE_RATE_05_02 : 87|14@0+ (0.015625,-128) [-128|127.984] "m/s" IFV_VFP
   SG_ CAN_DET_AMPLITUDE_05_02 : 79|7@0+ (1,-64) [-64|63] "dBsm" IFV_VFP
   SG_ CAN_SCAN_INDEX_2LSB_05_02 : 89|2@0+ (1,0) [0|3] "" IFV_VFP
   SG_ CAN_DET_CONFID_AZIMUTH_05_03 : 177|2@0+ (1,0) [0|3] "" IFV_VFP
   SG_ CAN_DET_SUPER_RES_TARGET_05_03 : 200|1@0+ (1,0) [0|1] "" IFV_VFP
   SG_ CAN_DET_NEW_SIGNAL_05_03 : 206|6@0+ (1,0) [0|64] "" IFV_VFP
   SG_ CAN_DET_ND_TARGET_05_03 : 192|1@0+ (1,0) [0|1] "" IFV_VFP
   SG_ CAN_DET_HOST_VEH_CLUTTER_05_03 : 193|1@0+ (1,0) [0|1] "" IFV_VFP
   SG_ CAN_DET_VALID_LEVEL_05_03 : 144|1@0+ (1,0) [0|1] "" IFV_VFP
   SG_ CAN_DET_AZIMUTH_05_03 : 191|14@0+ (0.0003834,-3.1416) [-3.1416|3.13964] "rad" IFV_VFP
   SG_ CAN_DET_RANGE_05_03 : 175|14@0+ (0.015625,0) [0|255.984] "m" IFV_VFP
   SG_ CAN_DET_RANGE_RATE_05_03 : 159|14@0+ (0.015625,-128) [-128|127.984] "m/s" IFV_VFP
   SG_ CAN_DET_AMPLITUDE_05_03 : 151|7@0+ (1,-64) [-64|63] "dBsm" IFV_VFP
   SG_ CAN_SCAN_INDEX_2LSB_05_03 : 161|2@0+ (1,0) [0|3] "" IFV_VFP
   SG_ CAN_DET_CONFID_AZIMUTH_05_04 : 249|2@0+ (1,0) [0|3] "" IFV_VFP
   SG_ CAN_DET_SUPER_RES_TARGET_05_04 : 272|1@0+ (1,0) [0|1] "" IFV_VFP
   SG_ CAN_DET_NEW_SIGNAL_05_04 : 278|6@0+ (1,0) [0|64] "" IFV_VFP
   SG_ CAN_DET_ND_TARGET_05_04 : 264|1@0+ (1,0) [0|1] "" IFV_VFP
   SG_ CAN_DET_HOST_VEH_CLUTTER_05_04 : 265|1@0+ (1,0) [0|1] "" IFV_VFP
   SG_ CAN_DET_VALID_LEVEL_05_04 : 216|1@0+ (1,0) [0|1] "" IFV_VFP
   SG_ CAN_DET_AZIMUTH_05_04 : 263|14@0+ (0.0003834,-3.1416) [-3.1416|3.13964] "rad" IFV_VFP
   SG_ CAN_DET_RANGE_05_04 : 247|14@0+ (0.015625,0) [0|255.984] "m" IFV_VFP
   SG_ CAN_DET_RANGE_RATE_05_04 : 231|14@0+ (0.015625,-128) [-128|127.984] "m/s" IFV_VFP
   SG_ CAN_DET_AMPLITUDE_05_04 : 223|7@0+ (1,-64) [-64|63] "dBsm" IFV_VFP
   SG_ CAN_SCAN_INDEX_2LSB_05_04 : 233|2@0+ (1,0) [0|3] "" IFV_VFP
   SG_ CAN_DET_CONFID_AZIMUTH_05_05 : 321|2@0+ (1,0) [0|3] "" IFV_VFP
   SG_ CAN_DET_SUPER_RES_TARGET_05_05 : 344|1@0+ (1,0) [0|1] "" IFV_VFP
   SG_ CAN_DET_NEW_SIGNAL_05_05 : 350|6@0+ (1,0) [0|64] "" IFV_VFP
   SG_ CAN_DET_ND_TARGET_05_05 : 336|1@0+ (1,0) [0|1] "" IFV_VFP
   SG_ CAN_DET_HOST_VEH_CLUTTER_05_05 : 337|1@0+ (1,0) [0|1] "" IFV_VFP
   SG_ CAN_DET_VALID_LEVEL_05_05 : 288|1@0+ (1,0) [0|1] "" IFV_VFP
   SG_ CAN_DET_AZIMUTH_05_05 : 335|14@0+ (0.0003834,-3.1416) [-3.1416|3.13964] "rad" IFV_VFP
   SG_ CAN_DET_RANGE_05_05 : 319|14@0+ (0.015625,0) [0|255.984] "m" IFV_VFP
   SG_ CAN_DET_RANGE_RATE_05_05 : 303|14@0+ (0.015625,-128) [-128|127.984] "m/s" IFV_VFP
   SG_ CAN_DET_AMPLITUDE_05_05 : 295|7@0+ (1,-64) [-64|63] "dBsm" IFV_VFP
   SG_ CAN_SCAN_INDEX_2LSB_05_05 : 305|2@0+ (1,0) [0|3] "" IFV_VFP
   SG_ CAN_DET_CONFID_AZIMUTH_05_06 : 393|2@0+ (1,0) [0|3] "" IFV_VFP
   SG_ CAN_DET_SUPER_RES_TARGET_05_06 : 416|1@0+ (1,0) [0|1] "" IFV_VFP
   SG_ CAN_DET_NEW_SIGNAL_05_06 : 422|6@0+ (1,0) [0|64] "" IFV_VFP
   SG_ CAN_DET_ND_TARGET_05_06 : 408|1@0+ (1,0) [0|1] "" IFV_VFP
   SG_ CAN_DET_HOST_VEH_CLUTTER_05_06 : 409|1@0+ (1,0) [0|1] "" IFV_VFP
   SG_ CAN_DET_VALID_LEVEL_05_06 : 360|1@0+ (1,0) [0|1] "" IFV_VFP
   SG_ CAN_DET_AZIMUTH_05_06 : 407|14@0+ (0.0003834,-3.1416) [-3.1416|3.13964] "rad" IFV_VFP
   SG_ CAN_DET_RANGE_05_06 : 391|14@0+ (0.015625,0) [0|255.984] "m" IFV_VFP
   SG_ CAN_DET_RANGE_RATE_05_06 : 375|14@0+ (0.015625,-128) [-128|127.984] "m/s" IFV_VFP
   SG_ CAN_DET_AMPLITUDE_05_06 : 367|7@0+ (1,-64) [-64|63] "dBsm" IFV_VFP
   SG_ CAN_SCAN_INDEX_2LSB_05_06 : 377|2@0+ (1,0) [0|3] "" IFV_VFP

BO_ 290 MRR_Detection_003: 64 MRR
   SG_ CAN_DET_CONFID_AZIMUTH_03_01 : 33|2@0+ (1,0) [0|3] "" IFV_VFP
   SG_ CAN_DET_SUPER_RES_TARGET_03_01 : 56|1@0+ (1,0) [0|1] "" IFV_VFP
   SG_ CAN_DET_NEW_SIGNAL_03_01 : 62|6@0+ (1,0) [0|64] "" IFV_VFP
   SG_ CAN_DET_ND_TARGET_03_01 : 48|1@0+ (1,0) [0|1] "" IFV_VFP
   SG_ CAN_DET_HOST_VEH_CLUTTER_03_01 : 49|1@0+ (1,0) [0|1] "" IFV_VFP
   SG_ CAN_DET_VALID_LEVEL_03_01 : 0|1@0+ (1,0) [0|1] "" IFV_VFP
   SG_ CAN_DET_AZIMUTH_03_01 : 47|14@0+ (0.0003834,-3.1416) [-3.1416|3.13964] "rad" IFV_VFP
   SG_ CAN_DET_RANGE_03_01 : 31|14@0+ (0.015625,0) [0|255.984] "m" IFV_VFP
   SG_ CAN_DET_RANGE_RATE_03_01 : 15|14@0+ (0.015625,-128) [-128|127.984] "m/s" IFV_VFP
   SG_ CAN_DET_AMPLITUDE_03_01 : 7|7@0+ (1,-64) [-64|63] "dBsm" IFV_VFP
   SG_ CAN_SCAN_INDEX_2LSB_03_01 : 17|2@0+ (1,0) [0|3] "" IFV_VFP
   SG_ CAN_DET_CONFID_AZIMUTH_03_02 : 105|2@0+ (1,0) [0|3] "" IFV_VFP
   SG_ CAN_DET_SUPER_RES_TARGET_03_02 : 128|1@0+ (1,0) [0|1] "" IFV_VFP
   SG_ CAN_DET_NEW_SIGNAL_03_02 : 134|6@0+ (1,0) [0|64] "" IFV_VFP
   SG_ CAN_DET_ND_TARGET_03_02 : 120|1@0+ (1,0) [0|1] "" IFV_VFP
   SG_ CAN_DET_HOST_VEH_CLUTTER_03_02 : 121|1@0+ (1,0) [0|1] "" IFV_VFP
   SG_ CAN_DET_VALID_LEVEL_03_02 : 72|1@0+ (1,0) [0|1] "" IFV_VFP
   SG_ CAN_DET_AZIMUTH_03_02 : 119|14@0+ (0.0003834,-3.1416) [-3.1416|3.13964] "rad" IFV_VFP
   SG_ CAN_DET_RANGE_03_02 : 103|14@0+ (0.015625,0) [0|255.984] "m" IFV_VFP
   SG_ CAN_DET_RANGE_RATE_03_02 : 87|14@0+ (0.015625,-128) [-128|127.984] "m/s" IFV_VFP
   SG_ CAN_DET_AMPLITUDE_03_02 : 79|7@0+ (1,-64) [-64|63] "dBsm" IFV_VFP
   SG_ CAN_SCAN_INDEX_2LSB_03_02 : 89|2@0+ (1,0) [0|3] "" IFV_VFP
   SG_ CAN_DET_CONFID_AZIMUTH_03_03 : 177|2@0+ (1,0) [0|3] "" IFV_VFP
   SG_ CAN_DET_SUPER_RES_TARGET_03_03 : 200|1@0+ (1,0) [0|1] "" IFV_VFP
   SG_ CAN_DET_NEW_SIGNAL_03_03 : 206|6@0+ (1,0) [0|64] "" IFV_VFP
   SG_ CAN_DET_ND_TARGET_03_03 : 192|1@0+ (1,0) [0|1] "" IFV_VFP
   SG_ CAN_DET_HOST_VEH_CLUTTER_03_03 : 193|1@0+ (1,0) [0|1] "" IFV_VFP
   SG_ CAN_DET_VALID_LEVEL_03_03 : 144|1@0+ (1,0) [0|1] "" IFV_VFP
   SG_ CAN_DET_AZIMUTH_03_03 : 191|14@0+ (0.0003834,-3.1416) [-3.1416|3.13964] "rad" IFV_VFP
   SG_ CAN_DET_RANGE_03_03 : 175|14@0+ (0.015625,0) [0|255.984] "m" IFV_VFP
   SG_ CAN_DET_RANGE_RATE_03_03 : 159|14@0+ (0.015625,-128) [-128|127.984] "m/s" IFV_VFP
   SG_ CAN_DET_AMPLITUDE_03_03 : 151|7@0+ (1,-64) [-64|63] "dBsm" IFV_VFP
   SG_ CAN_SCAN_INDEX_2LSB_03_03 : 161|2@0+ (1,0) [0|3] "" IFV_VFP
   SG_ CAN_DET_CONFID_AZIMUTH_03_04 : 249|2@0+ (1,0) [0|3] "" IFV_VFP
   SG_ CAN_DET_SUPER_RES_TARGET_03_04 : 272|1@0+ (1,0) [0|1] "" IFV_VFP
   SG_ CAN_DET_NEW_SIGNAL_03_04 : 278|6@0+ (1,0) [0|64] "" IFV_VFP
   SG_ CAN_DET_ND_TARGET_03_04 : 264|1@0+ (1,0) [0|1] "" IFV_VFP
   SG_ CAN_DET_HOST_VEH_CLUTTER_03_04 : 265|1@0+ (1,0) [0|1] "" IFV_VFP
   SG_ CAN_DET_VALID_LEVEL_03_04 : 216|1@0+ (1,0) [0|1] "" IFV_VFP
   SG_ CAN_DET_AZIMUTH_03_04 : 263|14@0+ (0.0003834,-3.1416) [-3.1416|3.13964] "rad" IFV_VFP
   SG_ CAN_DET_RANGE_03_04 : 247|14@0+ (0.015625,0) [0|255.984] "m" IFV_VFP
   SG_ CAN_DET_RANGE_RATE_03_04 : 231|14@0+ (0.015625,-128) [-128|127.984] "m/s" IFV_VFP
   SG_ CAN_DET_AMPLITUDE_03_04 : 223|7@0+ (1,-64) [-64|63] "dBsm" IFV_VFP
   SG_ CAN_SCAN_INDEX_2LSB_03_04 : 233|2@0+ (1,0) [0|3] "" IFV_VFP
   SG_ CAN_DET_CONFID_AZIMUTH_03_05 : 321|2@0+ (1,0) [0|3] "" IFV_VFP
   SG_ CAN_DET_SUPER_RES_TARGET_03_05 : 344|1@0+ (1,0) [0|1] "" IFV_VFP
   SG_ CAN_DET_NEW_SIGNAL_03_05 : 350|6@0+ (1,0) [0|64] "" IFV_VFP
   SG_ CAN_DET_ND_TARGET_03_05 : 336|1@0+ (1,0) [0|1] "" IFV_VFP
   SG_ CAN_DET_HOST_VEH_CLUTTER_03_05 : 337|1@0+ (1,0) [0|1] "" IFV_VFP
   SG_ CAN_DET_VALID_LEVEL_03_05 : 288|1@0+ (1,0) [0|1] "" IFV_VFP
   SG_ CAN_DET_AZIMUTH_03_05 : 335|14@0+ (0.0003834,-3.1416) [-3.1416|3.13964] "rad" IFV_VFP
   SG_ CAN_DET_RANGE_03_05 : 319|14@0+ (0.015625,0) [0|255.984] "m" IFV_VFP
   SG_ CAN_DET_RANGE_RATE_03_05 : 303|14@0+ (0.015625,-128) [-128|127.984] "m/s" IFV_VFP
   SG_ CAN_DET_AMPLITUDE_03_05 : 295|7@0+ (1,-64) [-64|63] "dBsm" IFV_VFP
   SG_ CAN_SCAN_INDEX_2LSB_03_05 : 305|2@0+ (1,0) [0|3] "" IFV_VFP
   SG_ CAN_DET_CONFID_AZIMUTH_03_06 : 393|2@0+ (1,0) [0|3] "" IFV_VFP
   SG_ CAN_DET_SUPER_RES_TARGET_03_06 : 416|1@0+ (1,0) [0|1] "" IFV_VFP
   SG_ CAN_DET_NEW_SIGNAL_03_06 : 422|6@0+ (1,0) [0|64] "" IFV_VFP
   SG_ CAN_DET_ND_TARGET_03_06 : 408|1@0+ (1,0) [0|1] "" IFV_VFP
   SG_ CAN_DET_HOST_VEH_CLUTTER_03_06 : 409|1@0+ (1,0) [0|1] "" IFV_VFP
   SG_ CAN_DET_VALID_LEVEL_03_06 : 360|1@0+ (1,0) [0|1] "" IFV_VFP
   SG_ CAN_DET_AZIMUTH_03_06 : 407|14@0+ (0.0003834,-3.1416) [-3.1416|3.13964] "rad" IFV_VFP
   SG_ CAN_DET_RANGE_03_06 : 391|14@0+ (0.015625,0) [0|255.984] "m" IFV_VFP
   SG_ CAN_DET_RANGE_RATE_03_06 : 375|14@0+ (0.015625,-128) [-128|127.984] "m/s" IFV_VFP
   SG_ CAN_DET_AMPLITUDE_03_06 : 367|7@0+ (1,-64) [-64|63] "dBsm" IFV_VFP
   SG_ CAN_SCAN_INDEX_2LSB_03_06 : 377|2@0+ (1,0) [0|3] "" IFV_VFP

BO_ 289 MRR_Detection_002: 64 MRR
   SG_ CAN_DET_CONFID_AZIMUTH_02_01 : 33|2@0+ (1,0) [0|3] "" IFV_VFP
   SG_ CAN_DET_SUPER_RES_TARGET_02_01 : 56|1@0+ (1,0) [0|1] "" IFV_VFP
   SG_ CAN_DET_NEW_SIGNAL_02_01 : 62|6@0+ (1,0) [0|64] "" IFV_VFP
   SG_ CAN_DET_ND_TARGET_02_01 : 48|1@0+ (1,0) [0|1] "" IFV_VFP
   SG_ CAN_DET_HOST_VEH_CLUTTER_02_01 : 49|1@0+ (1,0) [0|1] "" IFV_VFP
   SG_ CAN_DET_VALID_LEVEL_02_01 : 0|1@0+ (1,0) [0|1] "" IFV_VFP
   SG_ CAN_DET_AZIMUTH_02_01 : 47|14@0+ (0.0003834,-3.1416) [-3.1416|3.13964] "rad" IFV_VFP
   SG_ CAN_DET_RANGE_02_01 : 31|14@0+ (0.015625,0) [0|255.984] "m" IFV_VFP
   SG_ CAN_DET_RANGE_RATE_02_01 : 15|14@0+ (0.015625,-128) [-128|127.984] "m/s" IFV_VFP
   SG_ CAN_DET_AMPLITUDE_02_01 : 7|7@0+ (1,-64) [-64|63] "dBsm" IFV_VFP
   SG_ CAN_SCAN_INDEX_2LSB_02_01 : 17|2@0+ (1,0) [0|3] "" IFV_VFP
   SG_ CAN_DET_CONFID_AZIMUTH_02_02 : 105|2@0+ (1,0) [0|3] "" IFV_VFP
   SG_ CAN_DET_SUPER_RES_TARGET_02_02 : 128|1@0+ (1,0) [0|1] "" IFV_VFP
   SG_ CAN_DET_NEW_SIGNAL_02_02 : 134|6@0+ (1,0) [0|64] "" IFV_VFP
   SG_ CAN_DET_ND_TARGET_02_02 : 120|1@0+ (1,0) [0|1] "" IFV_VFP
   SG_ CAN_DET_HOST_VEH_CLUTTER_02_02 : 121|1@0+ (1,0) [0|1] "" IFV_VFP
   SG_ CAN_DET_VALID_LEVEL_02_02 : 72|1@0+ (1,0) [0|1] "" IFV_VFP
   SG_ CAN_DET_AZIMUTH_02_02 : 119|14@0+ (0.0003834,-3.1416) [-3.1416|3.13964] "rad" IFV_VFP
   SG_ CAN_DET_RANGE_02_02 : 103|14@0+ (0.015625,0) [0|255.984] "m" IFV_VFP
   SG_ CAN_DET_RANGE_RATE_02_02 : 87|14@0+ (0.015625,-128) [-128|127.984] "m/s" IFV_VFP
   SG_ CAN_DET_AMPLITUDE_02_02 : 79|7@0+ (1,-64) [-64|63] "dBsm" IFV_VFP
   SG_ CAN_SCAN_INDEX_2LSB_02_02 : 89|2@0+ (1,0) [0|3] "" IFV_VFP
   SG_ CAN_DET_CONFID_AZIMUTH_02_03 : 177|2@0+ (1,0) [0|3] "" IFV_VFP
   SG_ CAN_DET_SUPER_RES_TARGET_02_03 : 200|1@0+ (1,0) [0|1] "" IFV_VFP
   SG_ CAN_DET_NEW_SIGNAL_02_03 : 206|6@0+ (1,0) [0|64] "" IFV_VFP
   SG_ CAN_DET_ND_TARGET_02_03 : 192|1@0+ (1,0) [0|1] "" IFV_VFP
   SG_ CAN_DET_HOST_VEH_CLUTTER_02_03 : 193|1@0+ (1,0) [0|1] "" IFV_VFP
   SG_ CAN_DET_VALID_LEVEL_02_03 : 144|1@0+ (1,0) [0|1] "" IFV_VFP
   SG_ CAN_DET_AZIMUTH_02_03 : 191|14@0+ (0.0003834,-3.1416) [-3.1416|3.13964] "rad" IFV_VFP
   SG_ CAN_DET_RANGE_02_03 : 175|14@0+ (0.015625,0) [0|255.984] "m" IFV_VFP
   SG_ CAN_DET_RANGE_RATE_02_03 : 159|14@0+ (0.015625,-128) [-128|127.984] "m/s" IFV_VFP
   SG_ CAN_DET_AMPLITUDE_02_03 : 151|7@0+ (1,-64) [-64|63] "dBsm" IFV_VFP
   SG_ CAN_SCAN_INDEX_2LSB_02_03 : 161|2@0+ (1,0) [0|3] "" IFV_VFP
   SG_ CAN_DET_CONFID_AZIMUTH_02_04 : 249|2@0+ (1,0) [0|3] "" IFV_VFP
   SG_ CAN_DET_SUPER_RES_TARGET_02_04 : 272|1@0+ (1,0) [0|1] "" IFV_VFP
   SG_ CAN_DET_NEW_SIGNAL_02_04 : 278|6@0+ (1,0) [0|64] "" IFV_VFP
   SG_ CAN_DET_ND_TARGET_02_04 : 264|1@0+ (1,0) [0|1] "" IFV_VFP
   SG_ CAN_DET_HOST_VEH_CLUTTER_02_04 : 265|1@0+ (1,0) [0|1] "" IFV_VFP
   SG_ CAN_DET_VALID_LEVEL_02_04 : 216|1@0+ (1,0) [0|1] "" IFV_VFP
   SG_ CAN_DET_AZIMUTH_02_04 : 263|14@0+ (0.0003834,-3.1416) [-3.1416|3.13964] "rad" IFV_VFP
   SG_ CAN_DET_RANGE_02_04 : 247|14@0+ (0.015625,0) [0|255.984] "m" IFV_VFP
   SG_ CAN_DET_RANGE_RATE_02_04 : 231|14@0+ (0.015625,-128) [-128|127.984] "m/s" IFV_VFP
   SG_ CAN_DET_AMPLITUDE_02_04 : 223|7@0+ (1,-64) [-64|63] "dBsm" IFV_VFP
   SG_ CAN_SCAN_INDEX_2LSB_02_04 : 233|2@0+ (1,0) [0|3] "" IFV_VFP
   SG_ CAN_DET_CONFID_AZIMUTH_02_05 : 321|2@0+ (1,0) [0|3] "" IFV_VFP
   SG_ CAN_DET_SUPER_RES_TARGET_02_05 : 344|1@0+ (1,0) [0|1] "" IFV_VFP
   SG_ CAN_DET_NEW_SIGNAL_02_05 : 350|6@0+ (1,0) [0|64] "" IFV_VFP
   SG_ CAN_DET_ND_TARGET_02_05 : 336|1@0+ (1,0) [0|1] "" IFV_VFP
   SG_ CAN_DET_HOST_VEH_CLUTTER_02_05 : 337|1@0+ (1,0) [0|1] "" IFV_VFP
   SG_ CAN_DET_VALID_LEVEL_02_05 : 288|1@0+ (1,0) [0|1] "" IFV_VFP
   SG_ CAN_DET_AZIMUTH_02_05 : 335|14@0+ (0.0003834,-3.1416) [-3.1416|3.13964] "rad" IFV_VFP
   SG_ CAN_DET_RANGE_02_05 : 319|14@0+ (0.015625,0) [0|255.984] "m" IFV_VFP
   SG_ CAN_DET_RANGE_RATE_02_05 : 303|14@0+ (0.015625,-128) [-128|127.984] "m/s" IFV_VFP
   SG_ CAN_DET_AMPLITUDE_02_05 : 295|7@0+ (1,-64) [-64|63] "dBsm" IFV_VFP
   SG_ CAN_SCAN_INDEX_2LSB_02_05 : 305|2@0+ (1,0) [0|3] "" IFV_VFP
   SG_ CAN_DET_CONFID_AZIMUTH_02_06 : 393|2@0+ (1,0) [0|3] "" IFV_VFP
   SG_ CAN_DET_SUPER_RES_TARGET_02_06 : 416|1@0+ (1,0) [0|1] "" IFV_VFP
   SG_ CAN_DET_NEW_SIGNAL_02_06 : 422|6@0+ (1,0) [0|64] "" IFV_VFP
   SG_ CAN_DET_ND_TARGET_02_06 : 408|1@0+ (1,0) [0|1] "" IFV_VFP
   SG_ CAN_DET_HOST_VEH_CLUTTER_02_06 : 409|1@0+ (1,0) [0|1] "" IFV_VFP
   SG_ CAN_DET_VALID_LEVEL_02_06 : 360|1@0+ (1,0) [0|1] "" IFV_VFP
   SG_ CAN_DET_AZIMUTH_02_06 : 407|14@0+ (0.0003834,-3.1416) [-3.1416|3.13964] "rad" IFV_VFP
   SG_ CAN_DET_RANGE_02_06 : 391|14@0+ (0.015625,0) [0|255.984] "m" IFV_VFP
   SG_ CAN_DET_RANGE_RATE_02_06 : 375|14@0+ (0.015625,-128) [-128|127.984] "m/s" IFV_VFP
   SG_ CAN_DET_AMPLITUDE_02_06 : 367|7@0+ (1,-64) [-64|63] "dBsm" IFV_VFP
   SG_ CAN_SCAN_INDEX_2LSB_02_06 : 377|2@0+ (1,0) [0|3] "" IFV_VFP

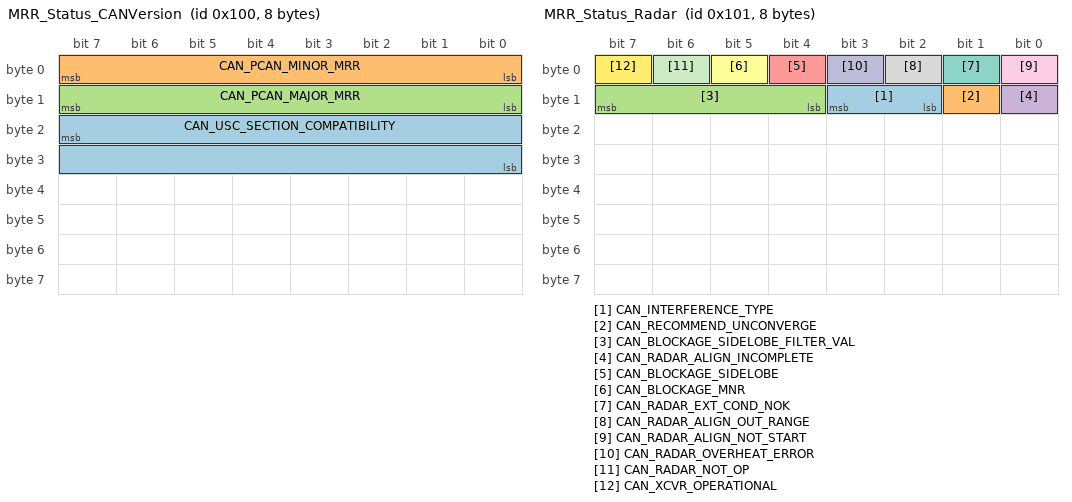
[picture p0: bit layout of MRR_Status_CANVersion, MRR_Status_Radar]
BO_ 256 MRR_Status_CANVersion: 8 MRR
   SG_ CAN_USC_SECTION_COMPATIBILITY : 23|16@0+ (1,0) [0|65535] "" External_Tool
   SG_ CAN_PCAN_MINOR_MRR : 7|8@0+ (1,0) [0|255] "" IFV_VFP
   SG_ CAN_PCAN_MAJOR_MRR : 15|8@0+ (1,0) [0|255] "" IFV_VFP

BO_ 257 MRR_Status_Radar: 8 MRR
   SG_ CAN_INTERFERENCE_TYPE : 11|2@0+ (1,0) [0|3] "" IFV_Host
   SG_ CAN_RECOMMEND_UNCONVERGE : 9|1@0+ (1,0) [0|1] "" IFV_Host
   SG_ CAN_BLOCKAGE_SIDELOBE_FILTER_VAL : 15|4@0+ (1,0) [0|15] "" IFV_Host
   SG_ CAN_RADAR_ALIGN_INCOMPLETE : 8|1@0+ (1,0) [0|1] "" IFV_VFP
   SG_ CAN_BLOCKAGE_SIDELOBE : 4|1@0+ (1,0) [0|1] "" IFV_VFP
   SG_ CAN_BLOCKAGE_MNR : 5|1@0+ (1,0) [0|1] "" IFV_VFP
   SG_ CAN_RADAR_EXT_COND_NOK : 1|1@0+ (1,0) [0|1] "" IFV_VFP
   SG_ CAN_RADAR_ALIGN_OUT_RANGE : 2|1@0+ (1,0) [0|1] "" IFV_VFP
   SG_ CAN_RADAR_ALIGN_NOT_START : 0|1@0+ (1,0) [0|1] "" IFV_VFP
   SG_ CAN_RADAR_OVERHEAT_ERROR : 3|1@0+ (1,0) [0|1] "" IFV_VFP
   SG_ CAN_RADAR_NOT_OP : 6|1@0+ (1,0) [0|1] "" IFV_VFP
   SG_ CAN_XCVR_OPERATIONAL : 7|1@0+ (1,0) [0|1] "" IFV_VFP

BO_ 288 MRR_Detection_001: 64 MRR
   SG_ CAN_DET_CONFID_AZIMUTH_01_01 : 33|2@0+ (1,0) [0|3] "" IFV_VFP
   SG_ CAN_DET_SUPER_RES_TARGET_01_01 : 56|1@0+ (1,0) [0|1] "" IFV_VFP
   SG_ CAN_DET_NEW_SIGNAL_01_01 : 62|6@0+ (1,0) [0|64] "" IFV_VFP
   SG_ CAN_DET_ND_TARGET_01_01 : 48|1@0+ (1,0) [0|1] "" IFV_VFP
   SG_ CAN_DET_HOST_VEH_CLUTTER_01_01 : 49|1@0+ (1,0) [0|1] "" IFV_VFP
   SG_ CAN_DET_VALID_LEVEL_01_01 : 0|1@0+ (1,0) [0|1] "" IFV_VFP
   SG_ CAN_DET_AZIMUTH_01_01 : 47|14@0+ (0.0003834,-3.1416) [-3.1416|3.13964] "rad" IFV_VFP
   SG_ CAN_DET_RANGE_01_01 : 31|14@0+ (0.015625,0) [0|255.984] "m" IFV_VFP
   SG_ CAN_DET_RANGE_RATE_01_01 : 15|14@0+ (0.015625,-128) [-128|127.984] "m/s" IFV_VFP
   SG_ CAN_DET_AMPLITUDE_01_01 : 7|7@0+ (1,-64) [-64|63] "dBsm" IFV_VFP
   SG_ CAN_SCAN_INDEX_2LSB_01_01 : 17|2@0+ (1,0) [0|3] "" IFV_VFP
   SG_ CAN_DET_CONFID_AZIMUTH_01_02 : 105|2@0+ (1,0) [0|3] "" IFV_VFP
   SG_ CAN_DET_SUPER_RES_TARGET_01_02 : 128|1@0+ (1,0) [0|1] "" IFV_VFP
   SG_ CAN_DET_NEW_SIGNAL_01_02 : 134|6@0+ (1,0) [0|64] "" IFV_VFP
   SG_ CAN_DET_ND_TARGET_01_02 : 120|1@0+ (1,0) [0|1] "" IFV_VFP
   SG_ CAN_DET_HOST_VEH_CLUTTER_01_02 : 121|1@0+ (1,0) [0|1] "" IFV_VFP
   SG_ CAN_DET_VALID_LEVEL_01_02 : 72|1@0+ (1,0) [0|1] "" IFV_VFP
   SG_ CAN_DET_AZIMUTH_01_02 : 119|14@0+ (0.0003834,-3.1416) [-3.1416|3.13964] "rad" IFV_VFP
   SG_ CAN_DET_RANGE_01_02 : 103|14@0+ (0.015625,0) [0|255.984] "m" IFV_VFP
   SG_ CAN_DET_RANGE_RATE_01_02 : 87|14@0+ (0.015625,-128) [-128|127.984] "m/s" IFV_VFP
   SG_ CAN_DET_AMPLITUDE_01_02 : 79|7@0+ (1,-64) [-64|63] "dBsm" IFV_VFP
   SG_ CAN_SCAN_INDEX_2LSB_01_02 : 89|2@0+ (1,0) [0|3] "" IFV_VFP
   SG_ CAN_DET_CONFID_AZIMUTH_01_03 : 177|2@0+ (1,0) [0|3] "" IFV_VFP
   SG_ CAN_DET_SUPER_RES_TARGET_01_03 : 200|1@0+ (1,0) [0|1] "" IFV_VFP
   SG_ CAN_DET_NEW_SIGNAL_01_03 : 206|6@0+ (1,0) [0|64] "" IFV_VFP
   SG_ CAN_DET_ND_TARGET_01_03 : 192|1@0+ (1,0) [0|1] "" IFV_VFP
   SG_ CAN_DET_HOST_VEH_CLUTTER_01_03 : 193|1@0+ (1,0) [0|1] "" IFV_VFP
   SG_ CAN_DET_VALID_LEVEL_01_03 : 144|1@0+ (1,0) [0|1] "" IFV_VFP
   SG_ CAN_DET_AZIMUTH_01_03 : 191|14@0+ (0.0003834,-3.1416) [-3.1416|3.13964] "rad" IFV_VFP
   SG_ CAN_DET_RANGE_01_03 : 175|14@0+ (0.015625,0) [0|255.984] "m" IFV_VFP
   SG_ CAN_DET_RANGE_RATE_01_03 : 159|14@0+ (0.015625,-128) [-128|127.984] "m/s" IFV_VFP
   SG_ CAN_DET_AMPLITUDE_01_03 : 151|7@0+ (1,-64) [-64|63] "dBsm" IFV_VFP
   SG_ CAN_SCAN_INDEX_2LSB_01_03 : 161|2@0+ (1,0) [0|3] "" IFV_VFP
   SG_ CAN_DET_CONFID_AZIMUTH_01_04 : 249|2@0+ (1,0) [0|3] "" IFV_VFP
   SG_ CAN_DET_SUPER_RES_TARGET_01_04 : 272|1@0+ (1,0) [0|1] "" IFV_VFP
   SG_ CAN_DET_NEW_SIGNAL_01_04 : 278|6@0+ (1,0) [0|64] "" IFV_VFP
   SG_ CAN_DET_ND_TARGET_01_04 : 264|1@0+ (1,0) [0|1] "" IFV_VFP
   SG_ CAN_DET_HOST_VEH_CLUTTER_01_04 : 265|1@0+ (1,0) [0|1] "" IFV_VFP
   SG_ CAN_DET_VALID_LEVEL_01_04 : 216|1@0+ (1,0) [0|1] "" IFV_VFP
   SG_ CAN_DET_AZIMUTH_01_04 : 263|14@0+ (0.0003834,-3.1416) [-3.1416|3.13964] "rad" IFV_VFP
   SG_ CAN_DET_RANGE_01_04 : 247|14@0+ (0.015625,0) [0|255.984] "m" IFV_VFP
   SG_ CAN_DET_RANGE_RATE_01_04 : 231|14@0+ (0.015625,-128) [-128|127.984] "m/s" IFV_VFP
   SG_ CAN_DET_AMPLITUDE_01_04 : 223|7@0+ (1,-64) [-64|63] "dBsm" IFV_VFP
   SG_ CAN_SCAN_INDEX_2LSB_01_04 : 233|2@0+ (1,0) [0|3] "" IFV_VFP
   SG_ CAN_DET_CONFID_AZIMUTH_01_05 : 321|2@0+ (1,0) [0|3] "" IFV_VFP
   SG_ CAN_DET_SUPER_RES_TARGET_01_05 : 344|1@0+ (1,0) [0|1] "" IFV_VFP
   SG_ CAN_DET_NEW_SIGNAL_01_05 : 350|6@0+ (1,0) [0|64] "" IFV_VFP
   SG_ CAN_DET_ND_TARGET_01_05 : 336|1@0+ (1,0) [0|1] "" IFV_VFP
   SG_ CAN_DET_HOST_VEH_CLUTTER_01_05 : 337|1@0+ (1,0) [0|1] "" IFV_VFP
   SG_ CAN_DET_VALID_LEVEL_01_05 : 288|1@0+ (1,0) [0|1] "" IFV_VFP
   SG_ CAN_DET_AZIMUTH_01_05 : 335|14@0+ (0.0003834,-3.1416) [-3.1416|3.13964] "rad" IFV_VFP
   SG_ CAN_DET_RANGE_01_05 : 319|14@0+ (0.015625,0) [0|255.984] "m" IFV_VFP
   SG_ CAN_DET_RANGE_RATE_01_05 : 303|14@0+ (0.015625,-128) [-128|127.984] "m/s" IFV_VFP
   SG_ CAN_DET_AMPLITUDE_01_05 : 295|7@0+ (1,-64) [-64|63] "dBsm" IFV_VFP
   SG_ CAN_SCAN_INDEX_2LSB_01_05 : 305|2@0+ (1,0) [0|3] "" IFV_VFP
   SG_ CAN_DET_CONFID_AZIMUTH_01_06 : 393|2@0+ (1,0) [0|3] "" IFV_VFP
   SG_ CAN_DET_SUPER_RES_TARGET_01_06 : 416|1@0+ (1,0) [0|1] "" IFV_VFP
   SG_ CAN_DET_NEW_SIGNAL_01_06 : 422|6@0+ (1,0) [0|64] "" IFV_VFP
   SG_ CAN_DET_ND_TARGET_01_06 : 408|1@0+ (1,0) [0|1] "" IFV_VFP
   SG_ CAN_DET_HOST_VEH_CLUTTER_01_06 : 409|1@0+ (1,0) [0|1] "" IFV_VFP
   SG_ CAN_DET_VALID_LEVEL_01_06 : 360|1@0+ (1,0) [0|1] "" IFV_VFP
   SG_ CAN_DET_AZIMUTH_01_06 : 407|14@0+ (0.0003834,-3.1416) [-3.1416|3.13964] "rad" IFV_VFP
   SG_ CAN_DET_RANGE_01_06 : 391|14@0+ (0.015625,0) [0|255.984] "m" IFV_VFP
   SG_ CAN_DET_RANGE_RATE_01_06 : 375|14@0+ (0.015625,-128) [-128|127.984] "m/s" IFV_VFP
   SG_ CAN_DET_AMPLITUDE_01_06 : 367|7@0+ (1,-64) [-64|63] "dBsm" IFV_VFP
   SG_ CAN_SCAN_INDEX_2LSB_01_06 : 377|2@0+ (1,0) [0|3] "" IFV_VFP

BA_DEF_ SG_ "UsedOnPgmDBC" ENUM "No","Yes","No","Yes","No","Yes";
BA_DEF_ BO_ "DiagResponse" ENUM "No","Yes","No","Yes","No","Yes","No","Yes","No","Yes","No","Yes";
BA_DEF_ BO_ "EventRateOfChange" INT 10 10000;
BA_DEF_ SG_ "GenSigVtName" STRING ;
BA_DEF_ SG_ "GenSigVtEn" STRING ;
BA_DEF_ SG_ "GenSigCmt" STRING ;
BA_DEF_ SG_ "GenSigSendType" ENUM "No","Yes","No","Yes","No","Yes","No","Yes","No","Yes","No","Yes","No","Yes","No","Yes","No","Yes","No","Yes","No","Yes","Cyclic","OnWrite","vector_leerstring","OnChange","vector_leerstring","IfActive","vector_leerstring","NoSigSendType";
BA_DEF_ SG_ "GenSigStartValue" INT 0 1e+09;
BA_DEF_ BO_ "GenMsgILSupport" ENUM "No","Yes","No","Yes","No","Yes","No","Yes","No","Yes","No","Yes","No","Yes","No","Yes","No","Yes","No","Yes","No","Yes","Cyclic","OnWrite","vector_leerstring","OnChange","vector_leerstring","IfActive","vector_leerstring","NoSigSendType","No","Yes","No","Yes";
BA_DEF_ BO_ "GenMsgSendType" ENUM "No","Yes","No","Yes","No","Yes","No","Yes","No","Yes","No","Yes","No","Yes","No","Yes","No","Yes","No","Yes","No","Yes","Cyclic","OnWrite","vector_leerstring","OnChange","vector_leerstring","IfActive","vector_leerstring","NoSigSendType","No","Yes","No","Yes","No","Yes","FixedPeriodic","Event","EnabledPeriodic","NotUsed","NotUsed","EventPeriodic","NotUsed","NotUsed","NoMsgSendType";
BA_DEF_ BO_ "GenMsgCycleTime" INT 0 100000;
BA_DEF_ BO_ "GenMsgDelayTime" INT 0 1000;
BA_DEF_ BO_ "GenMsgNrOfRepetition" INT 0 100;
BA_DEF_ BO_ "NetworkInitialization" ENUM "No","Yes","No","Yes","No","Yes","No","Yes","No","Yes","No","Yes","No","Yes","No","Yes","No","Yes","No","Yes","No","Yes","Cyclic","OnWrite","vector_leerstring","OnChange","vector_leerstring","IfActive","vector_leerstring","NoSigSendType","No","Yes","No","Yes","No","Yes","FixedPeriodic","Event","EnabledPeriodic","NotUsed","NotUsed","EventPeriodic","NotUsed","NotUsed","NoMsgSendType","No","Yes";
BA_DEF_ BO_ "GenMsgBackgroundColor" STRING ;
BA_DEF_ BO_ "GenMsgForegroundColor" STRING ;
BA_ "GenMsgSendType" BO_ 298 1;
BA_ "GenSigVtEn" SG_ 298 CAN_DET_CONFID_AZIMUTH_11_01 "CAN_DET_CONFID_AZIMUTH_11_01";
BA_ "GenSigVtName" SG_ 298 CAN_DET_CONFID_AZIMUTH_11_01 "CAN_DET_CONFID_AZIMUTH_11_01";
BA_ "GenSigSendType" SG_ 298 CAN_DET_CONFID_AZIMUTH_11_01 0;
BA_ "GenSigCmt" SG_ 298 CAN_DET_CONFID_AZIMUTH_11_01 "CAN_DET_CONFID_AZIMUTH_11_01";
BA_ "GenSigSendType" SG_ 298 CAN_DET_SUPER_RES_TARGET_11_01 0;
BA_ "GenSigCmt" SG_ 298 CAN_DET_SUPER_RES_TARGET_11_01 "CAN_DET_SUPER_RES_TARGET_11_01";
BA_ "GenSigSendType" SG_ 298 CAN_DET_ND_TARGET_11_01 0;
BA_ "GenSigCmt" SG_ 298 CAN_DET_ND_TARGET_11_01 "CAN_DET_ND_TARGET_11_01";
BA_ "GenSigSendType" SG_ 298 CAN_DET_HOST_VEH_CLUTTER_11_01 0;
BA_ "GenSigCmt" SG_ 298 CAN_DET_HOST_VEH_CLUTTER_11_01 "CAN_DET_HOST_VEH_CLUTTER_11_01";
BA_ "GenSigSendType" SG_ 298 CAN_DET_VALID_LEVEL_11_01 0;
BA_ "GenSigCmt" SG_ 298 CAN_DET_VALID_LEVEL_11_01 "CAN_DET_VALID_LEVEL_11_01";
BA_ "GenSigSendType" SG_ 298 CAN_DET_AZIMUTH_11_01 0;
BA_ "GenSigCmt" SG_ 298 CAN_DET_AZIMUTH_11_01 "CAN_DET_AZIMUTH_11_01";
BA_ "GenSigSendType" SG_ 298 CAN_DET_RANGE_11_01 0;
BA_ "GenSigCmt" SG_ 298 CAN_DET_RANGE_11_01 "CAN_DET_RANGE_11_01";
BA_ "GenSigSendType" SG_ 298 CAN_DET_RANGE_RATE_11_01 0;
BA_ "GenSigCmt" SG_ 298 CAN_DET_RANGE_RATE_11_01 "CAN_DET_RANGE_RATE_11_01";
BA_ "GenSigSendType" SG_ 298 CAN_DET_AMPLITUDE_11_01 0;
BA_ "GenSigCmt" SG_ 298 CAN_DET_AMPLITUDE_11_01 "CAN_DET_AMPLITUDE_11_01";
BA_ "GenSigSendType" SG_ 298 CAN_SCAN_INDEX_2LSB_11_01 0;
BA_ "GenSigCmt" SG_ 298 CAN_SCAN_INDEX_2LSB_11_01 "CAN_SCAN_INDEX_2LSB_11_01";
BA_ "GenSigVtEn" SG_ 298 CAN_DET_CONFID_AZIMUTH_11_02 "CAN_DET_CONFID_AZIMUTH_11_02";
BA_ "GenSigVtName" SG_ 298 CAN_DET_CONFID_AZIMUTH_11_02 "CAN_DET_CONFID_AZIMUTH_11_02";
BA_ "GenSigSendType" SG_ 298 CAN_DET_CONFID_AZIMUTH_11_02 0;
BA_ "GenSigCmt" SG_ 298 CAN_DET_CONFID_AZIMUTH_11_02 "CAN_DET_CONFID_AZIMUTH_11_02";
BA_ "GenSigSendType" SG_ 298 CAN_DET_SUPER_RES_TARGET_11_02 0;
BA_ "GenSigCmt" SG_ 298 CAN_DET_SUPER_RES_TARGET_11_02 "CAN_DET_SUPER_RES_TARGET_11_02";
BA_ "GenSigSendType" SG_ 298 CAN_DET_ND_TARGET_11_02 0;
BA_ "GenSigCmt" SG_ 298 CAN_DET_ND_TARGET_11_02 "CAN_DET_ND_TARGET_11_02";
BA_ "GenSigSendType" SG_ 298 CAN_DET_HOST_VEH_CLUTTER_11_02 0;
BA_ "GenSigCmt" SG_ 298 CAN_DET_HOST_VEH_CLUTTER_11_02 "CAN_DET_HOST_VEH_CLUTTER_11_02";
BA_ "GenSigSendType" SG_ 298 CAN_DET_VALID_LEVEL_11_02 0;
BA_ "GenSigCmt" SG_ 298 CAN_DET_VALID_LEVEL_11_02 "CAN_DET_VALID_LEVEL_11_02";
BA_ "GenSigSendType" SG_ 298 CAN_DET_AZIMUTH_11_02 0;
BA_ "GenSigCmt" SG_ 298 CAN_DET_AZIMUTH_11_02 "CAN_DET_AZIMUTH_11_02";
BA_ "GenSigSendType" SG_ 298 CAN_DET_RANGE_11_02 0;
BA_ "GenSigCmt" SG_ 298 CAN_DET_RANGE_11_02 "CAN_DET_RANGE_11_02";
BA_ "GenSigSendType" SG_ 298 CAN_DET_RANGE_RATE_11_02 0;
BA_ "GenSigCmt" SG_ 298 CAN_DET_RANGE_RATE_11_02 "CAN_DET_RANGE_RATE_11_02";
BA_ "GenSigSendType" SG_ 298 CAN_DET_AMPLITUDE_11_02 0;
BA_ "GenSigCmt" SG_ 298 CAN_DET_AMPLITUDE_11_02 "CAN_DET_AMPLITUDE_11_02";
BA_ "GenSigSendType" SG_ 298 CAN_SCAN_INDEX_2LSB_11_02 0;
BA_ "GenSigCmt" SG_ 298 CAN_SCAN_INDEX_2LSB_11_02 "CAN_SCAN_INDEX_2LSB_11_02";
BA_ "GenSigVtEn" SG_ 298 CAN_DET_CONFID_AZIMUTH_11_03 "CAN_DET_CONFID_AZIMUTH_11_03";
BA_ "GenSigVtName" SG_ 298 CAN_DET_CONFID_AZIMUTH_11_03 "CAN_DET_CONFID_AZIMUTH_11_03";
BA_ "GenSigSendType" SG_ 298 CAN_DET_CONFID_AZIMUTH_11_03 0;
BA_ "GenSigCmt" SG_ 298 CAN_DET_CONFID_AZIMUTH_11_03 "CAN_DET_CONFID_AZIMUTH_11_03";
BA_ "GenSigSendType" SG_ 298 CAN_DET_SUPER_RES_TARGET_11_03 0;
BA_ "GenSigCmt" SG_ 298 CAN_DET_SUPER_RES_TARGET_11_03 "CAN_DET_SUPER_RES_TARGET_11_03";
BA_ "GenSigSendType" SG_ 298 CAN_DET_ND_TARGET_11_03 0;
BA_ "GenSigCmt" SG_ 298 CAN_DET_ND_TARGET_11_03 "CAN_DET_ND_TARGET_11_03";
BA_ "GenSigSendType" SG_ 298 CAN_DET_HOST_VEH_CLUTTER_11_03 0;
BA_ "GenSigCmt" SG_ 298 CAN_DET_HOST_VEH_CLUTTER_11_03 "CAN_DET_HOST_VEH_CLUTTER_11_03";
BA_ "GenSigSendType" SG_ 298 CAN_DET_VALID_LEVEL_11_03 0;
BA_ "GenSigCmt" SG_ 298 CAN_DET_VALID_LEVEL_11_03 "CAN_DET_VALID_LEVEL_11_03";
BA_ "GenSigSendType" SG_ 298 CAN_DET_AZIMUTH_11_03 0;
BA_ "GenSigCmt" SG_ 298 CAN_DET_AZIMUTH_11_03 "CAN_DET_AZIMUTH_11_03";
BA_ "GenSigSendType" SG_ 298 CAN_DET_RANGE_11_03 0;
BA_ "GenSigCmt" SG_ 298 CAN_DET_RANGE_11_03 "CAN_DET_RANGE_11_03";
BA_ "GenSigSendType" SG_ 298 CAN_DET_RANGE_RATE_11_03 0;
BA_ "GenSigCmt" SG_ 298 CAN_DET_RANGE_RATE_11_03 "CAN_DET_RANGE_RATE_11_03";
BA_ "GenSigSendType" SG_ 298 CAN_DET_AMPLITUDE_11_03 0;
BA_ "GenSigCmt" SG_ 298 CAN_DET_AMPLITUDE_11_03 "CAN_DET_AMPLITUDE_11_03";
BA_ "GenSigSendType" SG_ 298 CAN_SCAN_INDEX_2LSB_11_03 0;
BA_ "GenSigCmt" SG_ 298 CAN_SCAN_INDEX_2LSB_11_03 "CAN_SCAN_INDEX_2LSB_11_03";
BA_ "GenSigVtEn" SG_ 298 CAN_DET_CONFID_AZIMUTH_11_04 "CAN_DET_CONFID_AZIMUTH_11_04";
BA_ "GenSigVtName" SG_ 298 CAN_DET_CONFID_AZIMUTH_11_04 "CAN_DET_CONFID_AZIMUTH_11_04";
BA_ "GenSigSendType" SG_ 298 CAN_DET_CONFID_AZIMUTH_11_04 0;
BA_ "GenSigCmt" SG_ 298 CAN_DET_CONFID_AZIMUTH_11_04 "CAN_DET_CONFID_AZIMUTH_11_04";
BA_ "GenSigSendType" SG_ 298 CAN_DET_SUPER_RES_TARGET_11_04 0;
BA_ "GenSigCmt" SG_ 298 CAN_DET_SUPER_RES_TARGET_11_04 "CAN_DET_SUPER_RES_TARGET_11_04";
BA_ "GenSigSendType" SG_ 298 CAN_DET_ND_TARGET_11_04 0;
BA_ "GenSigCmt" SG_ 298 CAN_DET_ND_TARGET_11_04 "CAN_DET_ND_TARGET_11_04";
BA_ "GenSigSendType" SG_ 298 CAN_DET_HOST_VEH_CLUTTER_11_04 0;
BA_ "GenSigCmt" SG_ 298 CAN_DET_HOST_VEH_CLUTTER_11_04 "CAN_DET_HOST_VEH_CLUTTER_11_04";
BA_ "GenSigSendType" SG_ 298 CAN_DET_VALID_LEVEL_11_04 0;
BA_ "GenSigCmt" SG_ 298 CAN_DET_VALID_LEVEL_11_04 "CAN_DET_VALID_LEVEL_11_04";
BA_ "GenSigSendType" SG_ 298 CAN_DET_AZIMUTH_11_04 0;
BA_ "GenSigCmt" SG_ 298 CAN_DET_AZIMUTH_11_04 "CAN_DET_AZIMUTH_11_04";
BA_ "GenSigSendType" SG_ 298 CAN_DET_RANGE_11_04 0;
BA_ "GenSigCmt" SG_ 298 CAN_DET_RANGE_11_04 "CAN_DET_RANGE_11_04";
BA_ "GenSigSendType" SG_ 298 CAN_DET_RANGE_RATE_11_04 0;
BA_ "GenSigCmt" SG_ 298 CAN_DET_RANGE_RATE_11_04 "CAN_DET_RANGE_RATE_11_04";
BA_ "GenSigSendType" SG_ 298 CAN_DET_AMPLITUDE_11_04 0;
BA_ "GenSigCmt" SG_ 298 CAN_DET_AMPLITUDE_11_04 "CAN_DET_AMPLITUDE_11_04";
BA_ "GenSigSendType" SG_ 298 CAN_SCAN_INDEX_2LSB_11_04 0;
BA_ "GenSigCmt" SG_ 298 CAN_SCAN_INDEX_2LSB_11_04 "CAN_SCAN_INDEX_2LSB_11_04";
BA_ "GenSigVtEn" SG_ 298 CAN_DET_CONFID_AZIMUTH_11_05 "CAN_DET_CONFID_AZIMUTH_11_05";
BA_ "GenSigVtName" SG_ 298 CAN_DET_CONFID_AZIMUTH_11_05 "CAN_DET_CONFID_AZIMUTH_11_05";
BA_ "GenSigSendType" SG_ 298 CAN_DET_CONFID_AZIMUTH_11_05 0;
BA_ "GenSigCmt" SG_ 298 CAN_DET_CONFID_AZIMUTH_11_05 "CAN_DET_CONFID_AZIMUTH_11_05";
BA_ "GenSigSendType" SG_ 298 CAN_DET_SUPER_RES_TARGET_11_05 0;
BA_ "GenSigCmt" SG_ 298 CAN_DET_SUPER_RES_TARGET_11_05 "CAN_DET_SUPER_RES_TARGET_11_05";
BA_ "GenSigSendType" SG_ 298 CAN_DET_ND_TARGET_11_05 0;
BA_ "GenSigCmt" SG_ 298 CAN_DET_ND_TARGET_11_05 "CAN_DET_ND_TARGET_11_05";
BA_ "GenSigSendType" SG_ 298 CAN_DET_HOST_VEH_CLUTTER_11_05 0;
BA_ "GenSigCmt" SG_ 298 CAN_DET_HOST_VEH_CLUTTER_11_05 "CAN_DET_HOST_VEH_CLUTTER_11_05";
BA_ "GenSigSendType" SG_ 298 CAN_DET_VALID_LEVEL_11_05 0;
BA_ "GenSigCmt" SG_ 298 CAN_DET_VALID_LEVEL_11_05 "CAN_DET_VALID_LEVEL_11_05";
BA_ "GenSigSendType" SG_ 298 CAN_DET_AZIMUTH_11_05 0;
BA_ "GenSigCmt" SG_ 298 CAN_DET_AZIMUTH_11_05 "CAN_DET_AZIMUTH_11_05";
BA_ "GenSigSendType" SG_ 298 CAN_DET_RANGE_11_05 0;
BA_ "GenSigCmt" SG_ 298 CAN_DET_RANGE_11_05 "CAN_DET_RANGE_11_05";
BA_ "GenSigSendType" SG_ 298 CAN_DET_RANGE_RATE_11_05 0;
BA_ "GenSigCmt" SG_ 298 CAN_DET_RANGE_RATE_11_05 "CAN_DET_RANGE_RATE_11_05";
BA_ "GenSigSendType" SG_ 298 CAN_DET_AMPLITUDE_11_05 0;
BA_ "GenSigCmt" SG_ 298 CAN_DET_AMPLITUDE_11_05 "CAN_DET_AMPLITUDE_11_05";
BA_ "GenSigSendType" SG_ 298 CAN_SCAN_INDEX_2LSB_11_05 0;
BA_ "GenSigCmt" SG_ 298 CAN_SCAN_INDEX_2LSB_11_05 "CAN_SCAN_INDEX_2LSB_11_05";
BA_ "GenSigVtEn" SG_ 298 CAN_DET_CONFID_AZIMUTH_11_06 "CAN_DET_CONFID_AZIMUTH_11_06";
BA_ "GenSigVtName" SG_ 298 CAN_DET_CONFID_AZIMUTH_11_06 "CAN_DET_CONFID_AZIMUTH_11_06";
BA_ "GenSigSendType" SG_ 298 CAN_DET_CONFID_AZIMUTH_11_06 0;
BA_ "GenSigCmt" SG_ 298 CAN_DET_CONFID_AZIMUTH_11_06 "CAN_DET_CONFID_AZIMUTH_11_06";
BA_ "GenSigSendType" SG_ 298 CAN_DET_SUPER_RES_TARGET_11_06 0;
BA_ "GenSigCmt" SG_ 298 CAN_DET_SUPER_RES_TARGET_11_06 "CAN_DET_SUPER_RES_TARGET_11_06";
BA_ "GenSigSendType" SG_ 298 CAN_DET_ND_TARGET_11_06 0;
BA_ "GenSigCmt" SG_ 298 CAN_DET_ND_TARGET_11_06 "CAN_DET_ND_TARGET_11_06";
BA_ "GenSigSendType" SG_ 298 CAN_DET_HOST_VEH_CLUTTER_11_06 0;
BA_ "GenSigCmt" SG_ 298 CAN_DET_HOST_VEH_CLUTTER_11_06 "CAN_DET_HOST_VEH_CLUTTER_11_06";
BA_ "GenSigSendType" SG_ 298 CAN_DET_VALID_LEVEL_11_06 0;
BA_ "GenSigCmt" SG_ 298 CAN_DET_VALID_LEVEL_11_06 "CAN_DET_VALID_LEVEL_11_06";
BA_ "GenSigSendType" SG_ 298 CAN_DET_AZIMUTH_11_06 0;
BA_ "GenSigCmt" SG_ 298 CAN_DET_AZIMUTH_11_06 "CAN_DET_AZIMUTH_11_06";
BA_ "GenSigSendType" SG_ 298 CAN_DET_RANGE_11_06 0;
BA_ "GenSigCmt" SG_ 298 CAN_DET_RANGE_11_06 "CAN_DET_RANGE_11_06";
BA_ "GenSigSendType" SG_ 298 CAN_DET_RANGE_RATE_11_06 0;
BA_ "GenSigCmt" SG_ 298 CAN_DET_RANGE_RATE_11_06 "CAN_DET_RANGE_RATE_11_06";
BA_ "GenSigSendType" SG_ 298 CAN_DET_AMPLITUDE_11_06 0;
BA_ "GenSigCmt" SG_ 298 CAN_DET_AMPLITUDE_11_06 "CAN_DET_AMPLITUDE_11_06";
BA_ "GenSigSendType" SG_ 298 CAN_SCAN_INDEX_2LSB_11_06 0;
BA_ "GenSigCmt" SG_ 298 CAN_SCAN_INDEX_2LSB_11_06 "CAN_SCAN_INDEX_2LSB_11_06";
BA_ "GenMsgSendType" BO_ 297 1;
BA_ "GenSigVtEn" SG_ 297 CAN_DET_CONFID_AZIMUTH_10_01 "CAN_DET_CONFID_AZIMUTH_10_01";
BA_ "GenSigVtName" SG_ 297 CAN_DET_CONFID_AZIMUTH_10_01 "CAN_DET_CONFID_AZIMUTH_10_01";
BA_ "GenSigSendType" SG_ 297 CAN_DET_CONFID_AZIMUTH_10_01 0;
BA_ "GenSigCmt" SG_ 297 CAN_DET_CONFID_AZIMUTH_10_01 "CAN_DET_CONFID_AZIMUTH_10_01";
BA_ "GenSigSendType" SG_ 297 CAN_DET_SUPER_RES_TARGET_10_01 0;
BA_ "GenSigCmt" SG_ 297 CAN_DET_SUPER_RES_TARGET_10_01 "CAN_DET_SUPER_RES_TARGET_10_01";
BA_ "GenSigSendType" SG_ 297 CAN_DET_ND_TARGET_10_01 0;
BA_ "GenSigCmt" SG_ 297 CAN_DET_ND_TARGET_10_01 "CAN_DET_ND_TARGET_10_01";
BA_ "GenSigSendType" SG_ 297 CAN_DET_HOST_VEH_CLUTTER_10_01 0;
BA_ "GenSigCmt" SG_ 297 CAN_DET_HOST_VEH_CLUTTER_10_01 "CAN_DET_HOST_VEH_CLUTTER_10_01";
BA_ "GenSigSendType" SG_ 297 CAN_DET_VALID_LEVEL_10_01 0;
BA_ "GenSigCmt" SG_ 297 CAN_DET_VALID_LEVEL_10_01 "CAN_DET_VALID_LEVEL_10_01";
BA_ "GenSigSendType" SG_ 297 CAN_DET_AZIMUTH_10_01 0;
BA_ "GenSigCmt" SG_ 297 CAN_DET_AZIMUTH_10_01 "CAN_DET_AZIMUTH_10_01";
BA_ "GenSigSendType" SG_ 297 CAN_DET_RANGE_10_01 0;
BA_ "GenSigCmt" SG_ 297 CAN_DET_RANGE_10_01 "CAN_DET_RANGE_10_01";
BA_ "GenSigSendType" SG_ 297 CAN_DET_RANGE_RATE_10_01 0;
BA_ "GenSigCmt" SG_ 297 CAN_DET_RANGE_RATE_10_01 "CAN_DET_RANGE_RATE_10_01";
BA_ "GenSigSendType" SG_ 297 CAN_DET_AMPLITUDE_10_01 0;
BA_ "GenSigCmt" SG_ 297 CAN_DET_AMPLITUDE_10_01 "CAN_DET_AMPLITUDE_10_01";
BA_ "GenSigSendType" SG_ 297 CAN_SCAN_INDEX_2LSB_10_01 0;
BA_ "GenSigCmt" SG_ 297 CAN_SCAN_INDEX_2LSB_10_01 "CAN_SCAN_INDEX_2LSB_10_01";
BA_ "GenSigVtEn" SG_ 297 CAN_DET_CONFID_AZIMUTH_10_02 "CAN_DET_CONFID_AZIMUTH_10_02";
BA_ "GenSigVtName" SG_ 297 CAN_DET_CONFID_AZIMUTH_10_02 "CAN_DET_CONFID_AZIMUTH_10_02";
BA_ "GenSigSendType" SG_ 297 CAN_DET_CONFID_AZIMUTH_10_02 0;
BA_ "GenSigCmt" SG_ 297 CAN_DET_CONFID_AZIMUTH_10_02 "CAN_DET_CONFID_AZIMUTH_10_02";
BA_ "GenSigSendType" SG_ 297 CAN_DET_SUPER_RES_TARGET_10_02 0;
BA_ "GenSigCmt" SG_ 297 CAN_DET_SUPER_RES_TARGET_10_02 "CAN_DET_SUPER_RES_TARGET_10_02";
BA_ "GenSigSendType" SG_ 297 CAN_DET_ND_TARGET_10_02 0;
BA_ "GenSigCmt" SG_ 297 CAN_DET_ND_TARGET_10_02 "CAN_DET_ND_TARGET_10_02";
BA_ "GenSigSendType" SG_ 297 CAN_DET_HOST_VEH_CLUTTER_10_02 0;
BA_ "GenSigCmt" SG_ 297 CAN_DET_HOST_VEH_CLUTTER_10_02 "CAN_DET_HOST_VEH_CLUTTER_10_02";
BA_ "GenSigSendType" SG_ 297 CAN_DET_VALID_LEVEL_10_02 0;
BA_ "GenSigCmt" SG_ 297 CAN_DET_VALID_LEVEL_10_02 "CAN_DET_VALID_LEVEL_10_02";
BA_ "GenSigSendType" SG_ 297 CAN_DET_AZIMUTH_10_02 0;
BA_ "GenSigCmt" SG_ 297 CAN_DET_AZIMUTH_10_02 "CAN_DET_AZIMUTH_10_02";
BA_ "GenSigSendType" SG_ 297 CAN_DET_RANGE_10_02 0;
BA_ "GenSigCmt" SG_ 297 CAN_DET_RANGE_10_02 "CAN_DET_RANGE_10_02";
BA_ "GenSigSendType" SG_ 297 CAN_DET_RANGE_RATE_10_02 0;
BA_ "GenSigCmt" SG_ 297 CAN_DET_RANGE_RATE_10_02 "CAN_DET_RANGE_RATE_10_02";
BA_ "GenSigSendType" SG_ 297 CAN_DET_AMPLITUDE_10_02 0;
BA_ "GenSigCmt" SG_ 297 CAN_DET_AMPLITUDE_10_02 "CAN_DET_AMPLITUDE_10_02";
BA_ "GenSigSendType" SG_ 297 CAN_SCAN_INDEX_2LSB_10_02 0;
BA_ "GenSigCmt" SG_ 297 CAN_SCAN_INDEX_2LSB_10_02 "CAN_SCAN_INDEX_2LSB_10_02";
BA_ "GenSigVtEn" SG_ 297 CAN_DET_CONFID_AZIMUTH_10_03 "CAN_DET_CONFID_AZIMUTH_10_03";
BA_ "GenSigVtName" SG_ 297 CAN_DET_CONFID_AZIMUTH_10_03 "CAN_DET_CONFID_AZIMUTH_10_03";
BA_ "GenSigSendType" SG_ 297 CAN_DET_CONFID_AZIMUTH_10_03 0;
BA_ "GenSigCmt" SG_ 297 CAN_DET_CONFID_AZIMUTH_10_03 "CAN_DET_CONFID_AZIMUTH_10_03";
BA_ "GenSigSendType" SG_ 297 CAN_DET_SUPER_RES_TARGET_10_03 0;
BA_ "GenSigCmt" SG_ 297 CAN_DET_SUPER_RES_TARGET_10_03 "CAN_DET_SUPER_RES_TARGET_10_03";
BA_ "GenSigSendType" SG_ 297 CAN_DET_ND_TARGET_10_03 0;
BA_ "GenSigCmt" SG_ 297 CAN_DET_ND_TARGET_10_03 "CAN_DET_ND_TARGET_10_03";
BA_ "GenSigSendType" SG_ 297 CAN_DET_HOST_VEH_CLUTTER_10_03 0;
BA_ "GenSigCmt" SG_ 297 CAN_DET_HOST_VEH_CLUTTER_10_03 "CAN_DET_HOST_VEH_CLUTTER_10_03";
BA_ "GenSigSendType" SG_ 297 CAN_DET_VALID_LEVEL_10_03 0;
BA_ "GenSigCmt" SG_ 297 CAN_DET_VALID_LEVEL_10_03 "CAN_DET_VALID_LEVEL_10_03";
BA_ "GenSigSendType" SG_ 297 CAN_DET_AZIMUTH_10_03 0;
BA_ "GenSigCmt" SG_ 297 CAN_DET_AZIMUTH_10_03 "CAN_DET_AZIMUTH_10_03";
BA_ "GenSigSendType" SG_ 297 CAN_DET_RANGE_10_03 0;
BA_ "GenSigCmt" SG_ 297 CAN_DET_RANGE_10_03 "CAN_DET_RANGE_10_03";
BA_ "GenSigSendType" SG_ 297 CAN_DET_RANGE_RATE_10_03 0;
BA_ "GenSigCmt" SG_ 297 CAN_DET_RANGE_RATE_10_03 "CAN_DET_RANGE_RATE_10_03";
BA_ "GenSigSendType" SG_ 297 CAN_DET_AMPLITUDE_10_03 0;
BA_ "GenSigCmt" SG_ 297 CAN_DET_AMPLITUDE_10_03 "CAN_DET_AMPLITUDE_10_03";
BA_ "GenSigSendType" SG_ 297 CAN_SCAN_INDEX_2LSB_10_03 0;
BA_ "GenSigCmt" SG_ 297 CAN_SCAN_INDEX_2LSB_10_03 "CAN_SCAN_INDEX_2LSB_10_03";
BA_ "GenSigVtEn" SG_ 297 CAN_DET_CONFID_AZIMUTH_10_04 "CAN_DET_CONFID_AZIMUTH_10_04";
BA_ "GenSigVtName" SG_ 297 CAN_DET_CONFID_AZIMUTH_10_04 "CAN_DET_CONFID_AZIMUTH_10_04";
BA_ "GenSigSendType" SG_ 297 CAN_DET_CONFID_AZIMUTH_10_04 0;
BA_ "GenSigCmt" SG_ 297 CAN_DET_CONFID_AZIMUTH_10_04 "CAN_DET_CONFID_AZIMUTH_10_04";
BA_ "GenSigSendType" SG_ 297 CAN_DET_SUPER_RES_TARGET_10_04 0;
BA_ "GenSigCmt" SG_ 297 CAN_DET_SUPER_RES_TARGET_10_04 "CAN_DET_SUPER_RES_TARGET_10_04";
BA_ "GenSigSendType" SG_ 297 CAN_DET_ND_TARGET_10_04 0;
BA_ "GenSigCmt" SG_ 297 CAN_DET_ND_TARGET_10_04 "CAN_DET_ND_TARGET_10_04";
BA_ "GenSigSendType" SG_ 297 CAN_DET_HOST_VEH_CLUTTER_10_04 0;
BA_ "GenSigCmt" SG_ 297 CAN_DET_HOST_VEH_CLUTTER_10_04 "CAN_DET_HOST_VEH_CLUTTER_10_04";
BA_ "GenSigSendType" SG_ 297 CAN_DET_VALID_LEVEL_10_04 0;
BA_ "GenSigCmt" SG_ 297 CAN_DET_VALID_LEVEL_10_04 "CAN_DET_VALID_LEVEL_10_04";
BA_ "GenSigSendType" SG_ 297 CAN_DET_AZIMUTH_10_04 0;
BA_ "GenSigCmt" SG_ 297 CAN_DET_AZIMUTH_10_04 "CAN_DET_AZIMUTH_10_04";
BA_ "GenSigSendType" SG_ 297 CAN_DET_RANGE_10_04 0;
BA_ "GenSigCmt" SG_ 297 CAN_DET_RANGE_10_04 "CAN_DET_RANGE_10_04";
BA_ "GenSigSendType" SG_ 297 CAN_DET_RANGE_RATE_10_04 0;
BA_ "GenSigCmt" SG_ 297 CAN_DET_RANGE_RATE_10_04 "CAN_DET_RANGE_RATE_10_04";
BA_ "GenSigSendType" SG_ 297 CAN_DET_AMPLITUDE_10_04 0;
BA_ "GenSigCmt" SG_ 297 CAN_DET_AMPLITUDE_10_04 "CAN_DET_AMPLITUDE_10_04";
BA_ "GenSigSendType" SG_ 297 CAN_SCAN_INDEX_2LSB_10_04 0;
BA_ "GenSigCmt" SG_ 297 CAN_SCAN_INDEX_2LSB_10_04 "CAN_SCAN_INDEX_2LSB_10_04";
BA_ "GenSigVtEn" SG_ 297 CAN_DET_CONFID_AZIMUTH_10_05 "CAN_DET_CONFID_AZIMUTH_10_05";
BA_ "GenSigVtName" SG_ 297 CAN_DET_CONFID_AZIMUTH_10_05 "CAN_DET_CONFID_AZIMUTH_10_05";
BA_ "GenSigSendType" SG_ 297 CAN_DET_CONFID_AZIMUTH_10_05 0;
BA_ "GenSigCmt" SG_ 297 CAN_DET_CONFID_AZIMUTH_10_05 "CAN_DET_CONFID_AZIMUTH_10_05";
BA_ "GenSigSendType" SG_ 297 CAN_DET_SUPER_RES_TARGET_10_05 0;
BA_ "GenSigCmt" SG_ 297 CAN_DET_SUPER_RES_TARGET_10_05 "CAN_DET_SUPER_RES_TARGET_10_05";
BA_ "GenSigSendType" SG_ 297 CAN_DET_ND_TARGET_10_05 0;
BA_ "GenSigCmt" SG_ 297 CAN_DET_ND_TARGET_10_05 "CAN_DET_ND_TARGET_10_05";
BA_ "GenSigSendType" SG_ 297 CAN_DET_HOST_VEH_CLUTTER_10_05 0;
BA_ "GenSigCmt" SG_ 297 CAN_DET_HOST_VEH_CLUTTER_10_05 "CAN_DET_HOST_VEH_CLUTTER_10_05";
BA_ "GenSigSendType" SG_ 297 CAN_DET_VALID_LEVEL_10_05 0;
BA_ "GenSigCmt" SG_ 297 CAN_DET_VALID_LEVEL_10_05 "CAN_DET_VALID_LEVEL_10_05";
BA_ "GenSigSendType" SG_ 297 CAN_DET_AZIMUTH_10_05 0;
BA_ "GenSigCmt" SG_ 297 CAN_DET_AZIMUTH_10_05 "CAN_DET_AZIMUTH_10_05";
BA_ "GenSigSendType" SG_ 297 CAN_DET_RANGE_10_05 0;
BA_ "GenSigCmt" SG_ 297 CAN_DET_RANGE_10_05 "CAN_DET_RANGE_10_05";
BA_ "GenSigSendType" SG_ 297 CAN_DET_RANGE_RATE_10_05 0;
BA_ "GenSigCmt" SG_ 297 CAN_DET_RANGE_RATE_10_05 "CAN_DET_RANGE_RATE_10_05";
BA_ "GenSigSendType" SG_ 297 CAN_DET_AMPLITUDE_10_05 0;
BA_ "GenSigCmt" SG_ 297 CAN_DET_AMPLITUDE_10_05 "CAN_DET_AMPLITUDE_10_05";
BA_ "GenSigSendType" SG_ 297 CAN_SCAN_INDEX_2LSB_10_05 0;
BA_ "GenSigCmt" SG_ 297 CAN_SCAN_INDEX_2LSB_10_05 "CAN_SCAN_INDEX_2LSB_10_05";
BA_ "GenSigVtEn" SG_ 297 CAN_DET_CONFID_AZIMUTH_10_06 "CAN_DET_CONFID_AZIMUTH_10_06";
BA_ "GenSigVtName" SG_ 297 CAN_DET_CONFID_AZIMUTH_10_06 "CAN_DET_CONFID_AZIMUTH_10_06";
BA_ "GenSigSendType" SG_ 297 CAN_DET_CONFID_AZIMUTH_10_06 0;
BA_ "GenSigCmt" SG_ 297 CAN_DET_CONFID_AZIMUTH_10_06 "CAN_DET_CONFID_AZIMUTH_10_06";
BA_ "GenSigSendType" SG_ 297 CAN_DET_SUPER_RES_TARGET_10_06 0;
BA_ "GenSigCmt" SG_ 297 CAN_DET_SUPER_RES_TARGET_10_06 "CAN_DET_SUPER_RES_TARGET_10_06";
BA_ "GenSigSendType" SG_ 297 CAN_DET_ND_TARGET_10_06 0;
BA_ "GenSigCmt" SG_ 297 CAN_DET_ND_TARGET_10_06 "CAN_DET_ND_TARGET_10_06";
BA_ "GenSigSendType" SG_ 297 CAN_DET_HOST_VEH_CLUTTER_10_06 0;
BA_ "GenSigCmt" SG_ 297 CAN_DET_HOST_VEH_CLUTTER_10_06 "CAN_DET_HOST_VEH_CLUTTER_10_06";
BA_ "GenSigSendType" SG_ 297 CAN_DET_VALID_LEVEL_10_06 0;
BA_ "GenSigCmt" SG_ 297 CAN_DET_VALID_LEVEL_10_06 "CAN_DET_VALID_LEVEL_10_06";
BA_ "GenSigSendType" SG_ 297 CAN_DET_AZIMUTH_10_06 0;
BA_ "GenSigCmt" SG_ 297 CAN_DET_AZIMUTH_10_06 "CAN_DET_AZIMUTH_10_06";
BA_ "GenSigSendType" SG_ 297 CAN_DET_RANGE_10_06 0;
BA_ "GenSigCmt" SG_ 297 CAN_DET_RANGE_10_06 "CAN_DET_RANGE_10_06";
BA_ "GenSigSendType" SG_ 297 CAN_DET_RANGE_RATE_10_06 0;
BA_ "GenSigCmt" SG_ 297 CAN_DET_RANGE_RATE_10_06 "CAN_DET_RANGE_RATE_10_06";
BA_ "GenSigSendType" SG_ 297 CAN_DET_AMPLITUDE_10_06 0;
BA_ "GenSigCmt" SG_ 297 CAN_DET_AMPLITUDE_10_06 "CAN_DET_AMPLITUDE_10_06";
BA_ "GenSigSendType" SG_ 297 CAN_SCAN_INDEX_2LSB_10_06 0;
BA_ "GenSigCmt" SG_ 297 CAN_SCAN_INDEX_2LSB_10_06 "CAN_SCAN_INDEX_2LSB_10_06";
BA_ "GenMsgSendType" BO_ 296 1;
BA_ "GenSigVtEn" SG_ 296 CAN_DET_CONFID_AZIMUTH_09_01 "CAN_DET_CONFID_AZIMUTH_09_01";
BA_ "GenSigVtName" SG_ 296 CAN_DET_CONFID_AZIMUTH_09_01 "CAN_DET_CONFID_AZIMUTH_09_01";
BA_ "GenSigSendType" SG_ 296 CAN_DET_CONFID_AZIMUTH_09_01 0;
BA_ "GenSigCmt" SG_ 296 CAN_DET_CONFID_AZIMUTH_09_01 "CAN_DET_CONFID_AZIMUTH_09_01";
BA_ "GenSigSendType" SG_ 296 CAN_DET_SUPER_RES_TARGET_09_01 0;
BA_ "GenSigCmt" SG_ 296 CAN_DET_SUPER_RES_TARGET_09_01 "CAN_DET_SUPER_RES_TARGET_09_01";
BA_ "GenSigSendType" SG_ 296 CAN_DET_ND_TARGET_09_01 0;
BA_ "GenSigCmt" SG_ 296 CAN_DET_ND_TARGET_09_01 "CAN_DET_ND_TARGET_09_01";
BA_ "GenSigSendType" SG_ 296 CAN_DET_HOST_VEH_CLUTTER_09_01 0;
BA_ "GenSigCmt" SG_ 296 CAN_DET_HOST_VEH_CLUTTER_09_01 "CAN_DET_HOST_VEH_CLUTTER_09_01";
BA_ "GenSigSendType" SG_ 296 CAN_DET_VALID_LEVEL_09_01 0;
BA_ "GenSigCmt" SG_ 296 CAN_DET_VALID_LEVEL_09_01 "CAN_DET_VALID_LEVEL_09_01";
BA_ "GenSigSendType" SG_ 296 CAN_DET_AZIMUTH_09_01 0;
BA_ "GenSigCmt" SG_ 296 CAN_DET_AZIMUTH_09_01 "CAN_DET_AZIMUTH_09_01";
BA_ "GenSigSendType" SG_ 296 CAN_DET_RANGE_09_01 0;
BA_ "GenSigCmt" SG_ 296 CAN_DET_RANGE_09_01 "CAN_DET_RANGE_09_01";
BA_ "GenSigSendType" SG_ 296 CAN_DET_RANGE_RATE_09_01 0;
BA_ "GenSigCmt" SG_ 296 CAN_DET_RANGE_RATE_09_01 "CAN_DET_RANGE_RATE_09_01";
BA_ "GenSigSendType" SG_ 296 CAN_DET_AMPLITUDE_09_01 0;
BA_ "GenSigCmt" SG_ 296 CAN_DET_AMPLITUDE_09_01 "CAN_DET_AMPLITUDE_09_01";
BA_ "GenSigSendType" SG_ 296 CAN_SCAN_INDEX_2LSB_09_01 0;
BA_ "GenSigCmt" SG_ 296 CAN_SCAN_INDEX_2LSB_09_01 "CAN_SCAN_INDEX_2LSB_09_01";
BA_ "GenSigVtEn" SG_ 296 CAN_DET_CONFID_AZIMUTH_09_02 "CAN_DET_CONFID_AZIMUTH_09_02";
BA_ "GenSigVtName" SG_ 296 CAN_DET_CONFID_AZIMUTH_09_02 "CAN_DET_CONFID_AZIMUTH_09_02";
BA_ "GenSigSendType" SG_ 296 CAN_DET_CONFID_AZIMUTH_09_02 0;
BA_ "GenSigCmt" SG_ 296 CAN_DET_CONFID_AZIMUTH_09_02 "CAN_DET_CONFID_AZIMUTH_09_02";
BA_ "GenSigSendType" SG_ 296 CAN_DET_SUPER_RES_TARGET_09_02 0;
BA_ "GenSigCmt" SG_ 296 CAN_DET_SUPER_RES_TARGET_09_02 "CAN_DET_SUPER_RES_TARGET_09_02";
BA_ "GenSigSendType" SG_ 296 CAN_DET_ND_TARGET_09_02 0;
BA_ "GenSigCmt" SG_ 296 CAN_DET_ND_TARGET_09_02 "CAN_DET_ND_TARGET_09_02";
BA_ "GenSigSendType" SG_ 296 CAN_DET_HOST_VEH_CLUTTER_09_02 0;
BA_ "GenSigCmt" SG_ 296 CAN_DET_HOST_VEH_CLUTTER_09_02 "CAN_DET_HOST_VEH_CLUTTER_09_02";
BA_ "GenSigSendType" SG_ 296 CAN_DET_VALID_LEVEL_09_02 0;
BA_ "GenSigCmt" SG_ 296 CAN_DET_VALID_LEVEL_09_02 "CAN_DET_VALID_LEVEL_09_02";
BA_ "GenSigSendType" SG_ 296 CAN_DET_AZIMUTH_09_02 0;
BA_ "GenSigCmt" SG_ 296 CAN_DET_AZIMUTH_09_02 "CAN_DET_AZIMUTH_09_02";
BA_ "GenSigSendType" SG_ 296 CAN_DET_RANGE_09_02 0;
BA_ "GenSigCmt" SG_ 296 CAN_DET_RANGE_09_02 "CAN_DET_RANGE_09_02";
BA_ "GenSigSendType" SG_ 296 CAN_DET_RANGE_RATE_09_02 0;
BA_ "GenSigCmt" SG_ 296 CAN_DET_RANGE_RATE_09_02 "CAN_DET_RANGE_RATE_09_02";
BA_ "GenSigSendType" SG_ 296 CAN_DET_AMPLITUDE_09_02 0;
BA_ "GenSigCmt" SG_ 296 CAN_DET_AMPLITUDE_09_02 "CAN_DET_AMPLITUDE_09_02";
BA_ "GenSigSendType" SG_ 296 CAN_SCAN_INDEX_2LSB_09_02 0;
BA_ "GenSigCmt" SG_ 296 CAN_SCAN_INDEX_2LSB_09_02 "CAN_SCAN_INDEX_2LSB_09_02";
BA_ "GenSigVtEn" SG_ 296 CAN_DET_CONFID_AZIMUTH_09_03 "CAN_DET_CONFID_AZIMUTH_09_03";
BA_ "GenSigVtName" SG_ 296 CAN_DET_CONFID_AZIMUTH_09_03 "CAN_DET_CONFID_AZIMUTH_09_03";
BA_ "GenSigSendType" SG_ 296 CAN_DET_CONFID_AZIMUTH_09_03 0;
BA_ "GenSigCmt" SG_ 296 CAN_DET_CONFID_AZIMUTH_09_03 "CAN_DET_CONFID_AZIMUTH_09_03";
BA_ "GenSigSendType" SG_ 296 CAN_DET_SUPER_RES_TARGET_09_03 0;
BA_ "GenSigCmt" SG_ 296 CAN_DET_SUPER_RES_TARGET_09_03 "CAN_DET_SUPER_RES_TARGET_09_03";
BA_ "GenSigSendType" SG_ 296 CAN_DET_ND_TARGET_09_03 0;
BA_ "GenSigCmt" SG_ 296 CAN_DET_ND_TARGET_09_03 "CAN_DET_ND_TARGET_09_03";
BA_ "GenSigSendType" SG_ 296 CAN_DET_HOST_VEH_CLUTTER_09_03 0;
BA_ "GenSigCmt" SG_ 296 CAN_DET_HOST_VEH_CLUTTER_09_03 "CAN_DET_HOST_VEH_CLUTTER_09_03";
BA_ "GenSigSendType" SG_ 296 CAN_DET_VALID_LEVEL_09_03 0;
BA_ "GenSigCmt" SG_ 296 CAN_DET_VALID_LEVEL_09_03 "CAN_DET_VALID_LEVEL_09_03";
BA_ "GenSigSendType" SG_ 296 CAN_DET_AZIMUTH_09_03 0;
BA_ "GenSigCmt" SG_ 296 CAN_DET_AZIMUTH_09_03 "CAN_DET_AZIMUTH_09_03";
BA_ "GenSigSendType" SG_ 296 CAN_DET_RANGE_09_03 0;
BA_ "GenSigCmt" SG_ 296 CAN_DET_RANGE_09_03 "CAN_DET_RANGE_09_03";
BA_ "GenSigSendType" SG_ 296 CAN_DET_RANGE_RATE_09_03 0;
BA_ "GenSigCmt" SG_ 296 CAN_DET_RANGE_RATE_09_03 "CAN_DET_RANGE_RATE_09_03";
BA_ "GenSigSendType" SG_ 296 CAN_DET_AMPLITUDE_09_03 0;
BA_ "GenSigCmt" SG_ 296 CAN_DET_AMPLITUDE_09_03 "CAN_DET_AMPLITUDE_09_03";
BA_ "GenSigSendType" SG_ 296 CAN_SCAN_INDEX_2LSB_09_03 0;
BA_ "GenSigCmt" SG_ 296 CAN_SCAN_INDEX_2LSB_09_03 "CAN_SCAN_INDEX_2LSB_09_03";
BA_ "GenSigVtEn" SG_ 296 CAN_DET_CONFID_AZIMUTH_09_04 "CAN_DET_CONFID_AZIMUTH_09_04";
BA_ "GenSigVtName" SG_ 296 CAN_DET_CONFID_AZIMUTH_09_04 "CAN_DET_CONFID_AZIMUTH_09_04";
BA_ "GenSigSendType" SG_ 296 CAN_DET_CONFID_AZIMUTH_09_04 0;
BA_ "GenSigCmt" SG_ 296 CAN_DET_CONFID_AZIMUTH_09_04 "CAN_DET_CONFID_AZIMUTH_09_04";
BA_ "GenSigSendType" SG_ 296 CAN_DET_SUPER_RES_TARGET_09_04 0;
BA_ "GenSigCmt" SG_ 296 CAN_DET_SUPER_RES_TARGET_09_04 "CAN_DET_SUPER_RES_TARGET_09_04";
BA_ "GenSigSendType" SG_ 296 CAN_DET_ND_TARGET_09_04 0;
BA_ "GenSigCmt" SG_ 296 CAN_DET_ND_TARGET_09_04 "CAN_DET_ND_TARGET_09_04";
BA_ "GenSigSendType" SG_ 296 CAN_DET_HOST_VEH_CLUTTER_09_04 0;
BA_ "GenSigCmt" SG_ 296 CAN_DET_HOST_VEH_CLUTTER_09_04 "CAN_DET_HOST_VEH_CLUTTER_09_04";
BA_ "GenSigSendType" SG_ 296 CAN_DET_VALID_LEVEL_09_04 0;
BA_ "GenSigCmt" SG_ 296 CAN_DET_VALID_LEVEL_09_04 "CAN_DET_VALID_LEVEL_09_04";
BA_ "GenSigSendType" SG_ 296 CAN_DET_AZIMUTH_09_04 0;
BA_ "GenSigCmt" SG_ 296 CAN_DET_AZIMUTH_09_04 "CAN_DET_AZIMUTH_09_04";
BA_ "GenSigSendType" SG_ 296 CAN_DET_RANGE_09_04 0;
BA_ "GenSigCmt" SG_ 296 CAN_DET_RANGE_09_04 "CAN_DET_RANGE_09_04";
BA_ "GenSigSendType" SG_ 296 CAN_DET_RANGE_RATE_09_04 0;
BA_ "GenSigCmt" SG_ 296 CAN_DET_RANGE_RATE_09_04 "CAN_DET_RANGE_RATE_09_04";
BA_ "GenSigSendType" SG_ 296 CAN_DET_AMPLITUDE_09_04 0;
BA_ "GenSigCmt" SG_ 296 CAN_DET_AMPLITUDE_09_04 "CAN_DET_AMPLITUDE_09_04";
BA_ "GenSigSendType" SG_ 296 CAN_SCAN_INDEX_2LSB_09_04 0;
BA_ "GenSigCmt" SG_ 296 CAN_SCAN_INDEX_2LSB_09_04 "CAN_SCAN_INDEX_2LSB_09_04";
BA_ "GenSigVtEn" SG_ 296 CAN_DET_CONFID_AZIMUTH_09_05 "CAN_DET_CONFID_AZIMUTH_09_05";
BA_ "GenSigVtName" SG_ 296 CAN_DET_CONFID_AZIMUTH_09_05 "CAN_DET_CONFID_AZIMUTH_09_05";
BA_ "GenSigSendType" SG_ 296 CAN_DET_CONFID_AZIMUTH_09_05 0;
BA_ "GenSigCmt" SG_ 296 CAN_DET_CONFID_AZIMUTH_09_05 "CAN_DET_CONFID_AZIMUTH_09_05";
BA_ "GenSigSendType" SG_ 296 CAN_DET_SUPER_RES_TARGET_09_05 0;
BA_ "GenSigCmt" SG_ 296 CAN_DET_SUPER_RES_TARGET_09_05 "CAN_DET_SUPER_RES_TARGET_09_05";
BA_ "GenSigSendType" SG_ 296 CAN_DET_ND_TARGET_09_05 0;
BA_ "GenSigCmt" SG_ 296 CAN_DET_ND_TARGET_09_05 "CAN_DET_ND_TARGET_09_05";
BA_ "GenSigSendType" SG_ 296 CAN_DET_HOST_VEH_CLUTTER_09_05 0;
BA_ "GenSigCmt" SG_ 296 CAN_DET_HOST_VEH_CLUTTER_09_05 "CAN_DET_HOST_VEH_CLUTTER_09_05";
BA_ "GenSigSendType" SG_ 296 CAN_DET_VALID_LEVEL_09_05 0;
BA_ "GenSigCmt" SG_ 296 CAN_DET_VALID_LEVEL_09_05 "CAN_DET_VALID_LEVEL_09_05";
BA_ "GenSigSendType" SG_ 296 CAN_DET_AZIMUTH_09_05 0;
BA_ "GenSigCmt" SG_ 296 CAN_DET_AZIMUTH_09_05 "CAN_DET_AZIMUTH_09_05";
BA_ "GenSigSendType" SG_ 296 CAN_DET_RANGE_09_05 0;
BA_ "GenSigCmt" SG_ 296 CAN_DET_RANGE_09_05 "CAN_DET_RANGE_09_05";
BA_ "GenSigSendType" SG_ 296 CAN_DET_RANGE_RATE_09_05 0;
BA_ "GenSigCmt" SG_ 296 CAN_DET_RANGE_RATE_09_05 "CAN_DET_RANGE_RATE_09_05";
BA_ "GenSigSendType" SG_ 296 CAN_DET_AMPLITUDE_09_05 0;
BA_ "GenSigCmt" SG_ 296 CAN_DET_AMPLITUDE_09_05 "CAN_DET_AMPLITUDE_09_05";
BA_ "GenSigSendType" SG_ 296 CAN_SCAN_INDEX_2LSB_09_05 0;
BA_ "GenSigCmt" SG_ 296 CAN_SCAN_INDEX_2LSB_09_05 "CAN_SCAN_INDEX_2LSB_09_05";
BA_ "GenSigVtEn" SG_ 296 CAN_DET_CONFID_AZIMUTH_09_06 "CAN_DET_CONFID_AZIMUTH_09_06";
BA_ "GenSigVtName" SG_ 296 CAN_DET_CONFID_AZIMUTH_09_06 "CAN_DET_CONFID_AZIMUTH_09_06";
BA_ "GenSigSendType" SG_ 296 CAN_DET_CONFID_AZIMUTH_09_06 0;
BA_ "GenSigCmt" SG_ 296 CAN_DET_CONFID_AZIMUTH_09_06 "CAN_DET_CONFID_AZIMUTH_09_06";
BA_ "GenSigSendType" SG_ 296 CAN_DET_SUPER_RES_TARGET_09_06 0;
BA_ "GenSigCmt" SG_ 296 CAN_DET_SUPER_RES_TARGET_09_06 "CAN_DET_SUPER_RES_TARGET_09_06";
BA_ "GenSigSendType" SG_ 296 CAN_DET_ND_TARGET_09_06 0;
BA_ "GenSigCmt" SG_ 296 CAN_DET_ND_TARGET_09_06 "CAN_DET_ND_TARGET_09_06";
BA_ "GenSigSendType" SG_ 296 CAN_DET_HOST_VEH_CLUTTER_09_06 0;
BA_ "GenSigCmt" SG_ 296 CAN_DET_HOST_VEH_CLUTTER_09_06 "CAN_DET_HOST_VEH_CLUTTER_09_06";
BA_ "GenSigSendType" SG_ 296 CAN_DET_VALID_LEVEL_09_06 0;
BA_ "GenSigCmt" SG_ 296 CAN_DET_VALID_LEVEL_09_06 "CAN_DET_VALID_LEVEL_09_06";
BA_ "GenSigSendType" SG_ 296 CAN_DET_AZIMUTH_09_06 0;
BA_ "GenSigCmt" SG_ 296 CAN_DET_AZIMUTH_09_06 "CAN_DET_AZIMUTH_09_06";
BA_ "GenSigSendType" SG_ 296 CAN_DET_RANGE_09_06 0;
BA_ "GenSigCmt" SG_ 296 CAN_DET_RANGE_09_06 "CAN_DET_RANGE_09_06";
BA_ "GenSigSendType" SG_ 296 CAN_DET_RANGE_RATE_09_06 0;
BA_ "GenSigCmt" SG_ 296 CAN_DET_RANGE_RATE_09_06 "CAN_DET_RANGE_RATE_09_06";
BA_ "GenSigSendType" SG_ 296 CAN_DET_AMPLITUDE_09_06 0;
BA_ "GenSigCmt" SG_ 296 CAN_DET_AMPLITUDE_09_06 "CAN_DET_AMPLITUDE_09_06";
BA_ "GenSigSendType" SG_ 296 CAN_SCAN_INDEX_2LSB_09_06 0;
BA_ "GenSigCmt" SG_ 296 CAN_SCAN_INDEX_2LSB_09_06 "CAN_SCAN_INDEX_2LSB_09_06";
BA_ "GenMsgSendType" BO_ 295 1;
BA_ "GenSigVtEn" SG_ 295 CAN_DET_CONFID_AZIMUTH_08_01 "CAN_DET_CONFID_AZIMUTH_08_01";
BA_ "GenSigVtName" SG_ 295 CAN_DET_CONFID_AZIMUTH_08_01 "CAN_DET_CONFID_AZIMUTH_08_01";
BA_ "GenSigSendType" SG_ 295 CAN_DET_CONFID_AZIMUTH_08_01 0;
BA_ "GenSigCmt" SG_ 295 CAN_DET_CONFID_AZIMUTH_08_01 "CAN_DET_CONFID_AZIMUTH_08_01";
BA_ "GenSigSendType" SG_ 295 CAN_DET_SUPER_RES_TARGET_08_01 0;
BA_ "GenSigCmt" SG_ 295 CAN_DET_SUPER_RES_TARGET_08_01 "CAN_DET_SUPER_RES_TARGET_08_01";
BA_ "GenSigSendType" SG_ 295 CAN_DET_ND_TARGET_08_01 0;
BA_ "GenSigCmt" SG_ 295 CAN_DET_ND_TARGET_08_01 "CAN_DET_ND_TARGET_08_01";
BA_ "GenSigSendType" SG_ 295 CAN_DET_HOST_VEH_CLUTTER_08_01 0;
BA_ "GenSigCmt" SG_ 295 CAN_DET_HOST_VEH_CLUTTER_08_01 "CAN_DET_HOST_VEH_CLUTTER_08_01";
BA_ "GenSigSendType" SG_ 295 CAN_DET_VALID_LEVEL_08_01 0;
BA_ "GenSigCmt" SG_ 295 CAN_DET_VALID_LEVEL_08_01 "CAN_DET_VALID_LEVEL_08_01";
BA_ "GenSigSendType" SG_ 295 CAN_DET_AZIMUTH_08_01 0;
BA_ "GenSigCmt" SG_ 295 CAN_DET_AZIMUTH_08_01 "CAN_DET_AZIMUTH_08_01";
BA_ "GenSigSendType" SG_ 295 CAN_DET_RANGE_08_01 0;
BA_ "GenSigCmt" SG_ 295 CAN_DET_RANGE_08_01 "CAN_DET_RANGE_08_01";
BA_ "GenSigSendType" SG_ 295 CAN_DET_RANGE_RATE_08_01 0;
BA_ "GenSigCmt" SG_ 295 CAN_DET_RANGE_RATE_08_01 "CAN_DET_RANGE_RATE_08_01";
BA_ "GenSigSendType" SG_ 295 CAN_DET_AMPLITUDE_08_01 0;
BA_ "GenSigCmt" SG_ 295 CAN_DET_AMPLITUDE_08_01 "CAN_DET_AMPLITUDE_08_01";
BA_ "GenSigSendType" SG_ 295 CAN_SCAN_INDEX_2LSB_08_01 0;
BA_ "GenSigCmt" SG_ 295 CAN_SCAN_INDEX_2LSB_08_01 "CAN_SCAN_INDEX_2LSB_08_01";
BA_ "GenSigVtEn" SG_ 295 CAN_DET_CONFID_AZIMUTH_08_02 "CAN_DET_CONFID_AZIMUTH_08_02";
BA_ "GenSigVtName" SG_ 295 CAN_DET_CONFID_AZIMUTH_08_02 "CAN_DET_CONFID_AZIMUTH_08_02";
BA_ "GenSigSendType" SG_ 295 CAN_DET_CONFID_AZIMUTH_08_02 0;
BA_ "GenSigCmt" SG_ 295 CAN_DET_CONFID_AZIMUTH_08_02 "CAN_DET_CONFID_AZIMUTH_08_02";
BA_ "GenSigSendType" SG_ 295 CAN_DET_SUPER_RES_TARGET_08_02 0;
BA_ "GenSigCmt" SG_ 295 CAN_DET_SUPER_RES_TARGET_08_02 "CAN_DET_SUPER_RES_TARGET_08_02";
BA_ "GenSigSendType" SG_ 295 CAN_DET_ND_TARGET_08_02 0;
BA_ "GenSigCmt" SG_ 295 CAN_DET_ND_TARGET_08_02 "CAN_DET_ND_TARGET_08_02";
BA_ "GenSigSendType" SG_ 295 CAN_DET_HOST_VEH_CLUTTER_08_02 0;
BA_ "GenSigCmt" SG_ 295 CAN_DET_HOST_VEH_CLUTTER_08_02 "CAN_DET_HOST_VEH_CLUTTER_08_02";
BA_ "GenSigSendType" SG_ 295 CAN_DET_VALID_LEVEL_08_02 0;
BA_ "GenSigCmt" SG_ 295 CAN_DET_VALID_LEVEL_08_02 "CAN_DET_VALID_LEVEL_08_02";
BA_ "GenSigSendType" SG_ 295 CAN_DET_AZIMUTH_08_02 0;
BA_ "GenSigCmt" SG_ 295 CAN_DET_AZIMUTH_08_02 "CAN_DET_AZIMUTH_08_02";
BA_ "GenSigSendType" SG_ 295 CAN_DET_RANGE_08_02 0;
BA_ "GenSigCmt" SG_ 295 CAN_DET_RANGE_08_02 "CAN_DET_RANGE_08_02";
BA_ "GenSigSendType" SG_ 295 CAN_DET_RANGE_RATE_08_02 0;
BA_ "GenSigCmt" SG_ 295 CAN_DET_RANGE_RATE_08_02 "CAN_DET_RANGE_RATE_08_02";
BA_ "GenSigSendType" SG_ 295 CAN_DET_AMPLITUDE_08_02 0;
BA_ "GenSigCmt" SG_ 295 CAN_DET_AMPLITUDE_08_02 "CAN_DET_AMPLITUDE_08_02";
BA_ "GenSigSendType" SG_ 295 CAN_SCAN_INDEX_2LSB_08_02 0;
BA_ "GenSigCmt" SG_ 295 CAN_SCAN_INDEX_2LSB_08_02 "CAN_SCAN_INDEX_2LSB_08_02";
BA_ "GenSigVtEn" SG_ 295 CAN_DET_CONFID_AZIMUTH_08_03 "CAN_DET_CONFID_AZIMUTH_08_03";
BA_ "GenSigVtName" SG_ 295 CAN_DET_CONFID_AZIMUTH_08_03 "CAN_DET_CONFID_AZIMUTH_08_03";
BA_ "GenSigSendType" SG_ 295 CAN_DET_CONFID_AZIMUTH_08_03 0;
BA_ "GenSigCmt" SG_ 295 CAN_DET_CONFID_AZIMUTH_08_03 "CAN_DET_CONFID_AZIMUTH_08_03";
BA_ "GenSigSendType" SG_ 295 CAN_DET_SUPER_RES_TARGET_08_03 0;
BA_ "GenSigCmt" SG_ 295 CAN_DET_SUPER_RES_TARGET_08_03 "CAN_DET_SUPER_RES_TARGET_08_03";
BA_ "GenSigSendType" SG_ 295 CAN_DET_ND_TARGET_08_03 0;
BA_ "GenSigCmt" SG_ 295 CAN_DET_ND_TARGET_08_03 "CAN_DET_ND_TARGET_08_03";
BA_ "GenSigSendType" SG_ 295 CAN_DET_HOST_VEH_CLUTTER_08_03 0;
BA_ "GenSigCmt" SG_ 295 CAN_DET_HOST_VEH_CLUTTER_08_03 "CAN_DET_HOST_VEH_CLUTTER_08_03";
BA_ "GenSigSendType" SG_ 295 CAN_DET_VALID_LEVEL_08_03 0;
BA_ "GenSigCmt" SG_ 295 CAN_DET_VALID_LEVEL_08_03 "CAN_DET_VALID_LEVEL_08_03";
BA_ "GenSigSendType" SG_ 295 CAN_DET_AZIMUTH_08_03 0;
BA_ "GenSigCmt" SG_ 295 CAN_DET_AZIMUTH_08_03 "CAN_DET_AZIMUTH_08_03";
BA_ "GenSigSendType" SG_ 295 CAN_DET_RANGE_08_03 0;
BA_ "GenSigCmt" SG_ 295 CAN_DET_RANGE_08_03 "CAN_DET_RANGE_08_03";
BA_ "GenSigSendType" SG_ 295 CAN_DET_RANGE_RATE_08_03 0;
BA_ "GenSigCmt" SG_ 295 CAN_DET_RANGE_RATE_08_03 "CAN_DET_RANGE_RATE_08_03";
BA_ "GenSigSendType" SG_ 295 CAN_DET_AMPLITUDE_08_03 0;
BA_ "GenSigCmt" SG_ 295 CAN_DET_AMPLITUDE_08_03 "CAN_DET_AMPLITUDE_08_03";
BA_ "GenSigSendType" SG_ 295 CAN_SCAN_INDEX_2LSB_08_03 0;
BA_ "GenSigCmt" SG_ 295 CAN_SCAN_INDEX_2LSB_08_03 "CAN_SCAN_INDEX_2LSB_08_03";
BA_ "GenSigVtEn" SG_ 295 CAN_DET_CONFID_AZIMUTH_08_04 "CAN_DET_CONFID_AZIMUTH_08_04";
BA_ "GenSigVtName" SG_ 295 CAN_DET_CONFID_AZIMUTH_08_04 "CAN_DET_CONFID_AZIMUTH_08_04";
BA_ "GenSigSendType" SG_ 295 CAN_DET_CONFID_AZIMUTH_08_04 0;
BA_ "GenSigCmt" SG_ 295 CAN_DET_CONFID_AZIMUTH_08_04 "CAN_DET_CONFID_AZIMUTH_08_04";
BA_ "GenSigSendType" SG_ 295 CAN_DET_SUPER_RES_TARGET_08_04 0;
BA_ "GenSigCmt" SG_ 295 CAN_DET_SUPER_RES_TARGET_08_04 "CAN_DET_SUPER_RES_TARGET_08_04";
BA_ "GenSigSendType" SG_ 295 CAN_DET_ND_TARGET_08_04 0;
BA_ "GenSigCmt" SG_ 295 CAN_DET_ND_TARGET_08_04 "CAN_DET_ND_TARGET_08_04";
BA_ "GenSigSendType" SG_ 295 CAN_DET_HOST_VEH_CLUTTER_08_04 0;
BA_ "GenSigCmt" SG_ 295 CAN_DET_HOST_VEH_CLUTTER_08_04 "CAN_DET_HOST_VEH_CLUTTER_08_04";
BA_ "GenSigSendType" SG_ 295 CAN_DET_VALID_LEVEL_08_04 0;
BA_ "GenSigCmt" SG_ 295 CAN_DET_VALID_LEVEL_08_04 "CAN_DET_VALID_LEVEL_08_04";
BA_ "GenSigSendType" SG_ 295 CAN_DET_AZIMUTH_08_04 0;
BA_ "GenSigCmt" SG_ 295 CAN_DET_AZIMUTH_08_04 "CAN_DET_AZIMUTH_08_04";
BA_ "GenSigSendType" SG_ 295 CAN_DET_RANGE_08_04 0;
BA_ "GenSigCmt" SG_ 295 CAN_DET_RANGE_08_04 "CAN_DET_RANGE_08_04";
BA_ "GenSigSendType" SG_ 295 CAN_DET_RANGE_RATE_08_04 0;
BA_ "GenSigCmt" SG_ 295 CAN_DET_RANGE_RATE_08_04 "CAN_DET_RANGE_RATE_08_04";
BA_ "GenSigSendType" SG_ 295 CAN_DET_AMPLITUDE_08_04 0;
BA_ "GenSigCmt" SG_ 295 CAN_DET_AMPLITUDE_08_04 "CAN_DET_AMPLITUDE_08_04";
BA_ "GenSigSendType" SG_ 295 CAN_SCAN_INDEX_2LSB_08_04 0;
BA_ "GenSigCmt" SG_ 295 CAN_SCAN_INDEX_2LSB_08_04 "CAN_SCAN_INDEX_2LSB_08_04";
BA_ "GenSigVtEn" SG_ 295 CAN_DET_CONFID_AZIMUTH_08_05 "CAN_DET_CONFID_AZIMUTH_08_05";
BA_ "GenSigVtName" SG_ 295 CAN_DET_CONFID_AZIMUTH_08_05 "CAN_DET_CONFID_AZIMUTH_08_05";
BA_ "GenSigSendType" SG_ 295 CAN_DET_CONFID_AZIMUTH_08_05 0;
BA_ "GenSigCmt" SG_ 295 CAN_DET_CONFID_AZIMUTH_08_05 "CAN_DET_CONFID_AZIMUTH_08_05";
BA_ "GenSigSendType" SG_ 295 CAN_DET_SUPER_RES_TARGET_08_05 0;
BA_ "GenSigCmt" SG_ 295 CAN_DET_SUPER_RES_TARGET_08_05 "CAN_DET_SUPER_RES_TARGET_08_05";
BA_ "GenSigSendType" SG_ 295 CAN_DET_ND_TARGET_08_05 0;
BA_ "GenSigCmt" SG_ 295 CAN_DET_ND_TARGET_08_05 "CAN_DET_ND_TARGET_08_05";
BA_ "GenSigSendType" SG_ 295 CAN_DET_HOST_VEH_CLUTTER_08_05 0;
BA_ "GenSigCmt" SG_ 295 CAN_DET_HOST_VEH_CLUTTER_08_05 "CAN_DET_HOST_VEH_CLUTTER_08_05";
BA_ "GenSigSendType" SG_ 295 CAN_DET_VALID_LEVEL_08_05 0;
BA_ "GenSigCmt" SG_ 295 CAN_DET_VALID_LEVEL_08_05 "CAN_DET_VALID_LEVEL_08_05";
BA_ "GenSigSendType" SG_ 295 CAN_DET_AZIMUTH_08_05 0;
BA_ "GenSigCmt" SG_ 295 CAN_DET_AZIMUTH_08_05 "CAN_DET_AZIMUTH_08_05";
BA_ "GenSigSendType" SG_ 295 CAN_DET_RANGE_08_05 0;
BA_ "GenSigCmt" SG_ 295 CAN_DET_RANGE_08_05 "CAN_DET_RANGE_08_05";
BA_ "GenSigSendType" SG_ 295 CAN_DET_RANGE_RATE_08_05 0;
BA_ "GenSigCmt" SG_ 295 CAN_DET_RANGE_RATE_08_05 "CAN_DET_RANGE_RATE_08_05";
BA_ "GenSigSendType" SG_ 295 CAN_DET_AMPLITUDE_08_05 0;
BA_ "GenSigCmt" SG_ 295 CAN_DET_AMPLITUDE_08_05 "CAN_DET_AMPLITUDE_08_05";
BA_ "GenSigSendType" SG_ 295 CAN_SCAN_INDEX_2LSB_08_05 0;
BA_ "GenSigCmt" SG_ 295 CAN_SCAN_INDEX_2LSB_08_05 "CAN_SCAN_INDEX_2LSB_08_05";
BA_ "GenSigVtEn" SG_ 295 CAN_DET_CONFID_AZIMUTH_08_06 "CAN_DET_CONFID_AZIMUTH_08_06";
BA_ "GenSigVtName" SG_ 295 CAN_DET_CONFID_AZIMUTH_08_06 "CAN_DET_CONFID_AZIMUTH_08_06";
BA_ "GenSigSendType" SG_ 295 CAN_DET_CONFID_AZIMUTH_08_06 0;
BA_ "GenSigCmt" SG_ 295 CAN_DET_CONFID_AZIMUTH_08_06 "CAN_DET_CONFID_AZIMUTH_08_06";
BA_ "GenSigSendType" SG_ 295 CAN_DET_SUPER_RES_TARGET_08_06 0;
BA_ "GenSigCmt" SG_ 295 CAN_DET_SUPER_RES_TARGET_08_06 "CAN_DET_SUPER_RES_TARGET_08_06";
BA_ "GenSigSendType" SG_ 295 CAN_DET_ND_TARGET_08_06 0;
BA_ "GenSigCmt" SG_ 295 CAN_DET_ND_TARGET_08_06 "CAN_DET_ND_TARGET_08_06";
BA_ "GenSigSendType" SG_ 295 CAN_DET_HOST_VEH_CLUTTER_08_06 0;
BA_ "GenSigCmt" SG_ 295 CAN_DET_HOST_VEH_CLUTTER_08_06 "CAN_DET_HOST_VEH_CLUTTER_08_06";
BA_ "GenSigSendType" SG_ 295 CAN_DET_VALID_LEVEL_08_06 0;
BA_ "GenSigCmt" SG_ 295 CAN_DET_VALID_LEVEL_08_06 "CAN_DET_VALID_LEVEL_08_06";
BA_ "GenSigSendType" SG_ 295 CAN_DET_AZIMUTH_08_06 0;
BA_ "GenSigCmt" SG_ 295 CAN_DET_AZIMUTH_08_06 "CAN_DET_AZIMUTH_08_06";
BA_ "GenSigSendType" SG_ 295 CAN_DET_RANGE_08_06 0;
BA_ "GenSigCmt" SG_ 295 CAN_DET_RANGE_08_06 "CAN_DET_RANGE_08_06";
BA_ "GenSigSendType" SG_ 295 CAN_DET_RANGE_RATE_08_06 0;
BA_ "GenSigCmt" SG_ 295 CAN_DET_RANGE_RATE_08_06 "CAN_DET_RANGE_RATE_08_06";
BA_ "GenSigSendType" SG_ 295 CAN_DET_AMPLITUDE_08_06 0;
BA_ "GenSigCmt" SG_ 295 CAN_DET_AMPLITUDE_08_06 "CAN_DET_AMPLITUDE_08_06";
BA_ "GenSigSendType" SG_ 295 CAN_SCAN_INDEX_2LSB_08_06 0;
BA_ "GenSigCmt" SG_ 295 CAN_SCAN_INDEX_2LSB_08_06 "CAN_SCAN_INDEX_2LSB_08_06";
BA_ "GenMsgSendType" BO_ 294 1;
BA_ "GenSigVtEn" SG_ 294 CAN_DET_CONFID_AZIMUTH_07_01 "CAN_DET_CONFID_AZIMUTH_07_01";
BA_ "GenSigVtName" SG_ 294 CAN_DET_CONFID_AZIMUTH_07_01 "CAN_DET_CONFID_AZIMUTH_07_01";
BA_ "GenSigSendType" SG_ 294 CAN_DET_CONFID_AZIMUTH_07_01 0;
BA_ "GenSigCmt" SG_ 294 CAN_DET_CONFID_AZIMUTH_07_01 "CAN_DET_CONFID_AZIMUTH_07_01";
BA_ "GenSigSendType" SG_ 294 CAN_DET_SUPER_RES_TARGET_07_01 0;
BA_ "GenSigCmt" SG_ 294 CAN_DET_SUPER_RES_TARGET_07_01 "CAN_DET_SUPER_RES_TARGET_07_01";
BA_ "GenSigSendType" SG_ 294 CAN_DET_ND_TARGET_07_01 0;
BA_ "GenSigCmt" SG_ 294 CAN_DET_ND_TARGET_07_01 "CAN_DET_ND_TARGET_07_01";
BA_ "GenSigSendType" SG_ 294 CAN_DET_HOST_VEH_CLUTTER_07_01 0;
BA_ "GenSigCmt" SG_ 294 CAN_DET_HOST_VEH_CLUTTER_07_01 "CAN_DET_HOST_VEH_CLUTTER_07_01";
BA_ "GenSigSendType" SG_ 294 CAN_DET_VALID_LEVEL_07_01 0;
BA_ "GenSigCmt" SG_ 294 CAN_DET_VALID_LEVEL_07_01 "CAN_DET_VALID_LEVEL_07_01";
BA_ "GenSigSendType" SG_ 294 CAN_DET_AZIMUTH_07_01 0;
BA_ "GenSigCmt" SG_ 294 CAN_DET_AZIMUTH_07_01 "CAN_DET_AZIMUTH_07_01";
BA_ "GenSigSendType" SG_ 294 CAN_DET_RANGE_07_01 0;
BA_ "GenSigCmt" SG_ 294 CAN_DET_RANGE_07_01 "CAN_DET_RANGE_07_01";
BA_ "GenSigSendType" SG_ 294 CAN_DET_RANGE_RATE_07_01 0;
BA_ "GenSigCmt" SG_ 294 CAN_DET_RANGE_RATE_07_01 "CAN_DET_RANGE_RATE_07_01";
BA_ "GenSigSendType" SG_ 294 CAN_DET_AMPLITUDE_07_01 0;
BA_ "GenSigCmt" SG_ 294 CAN_DET_AMPLITUDE_07_01 "CAN_DET_AMPLITUDE_07_01";
BA_ "GenSigSendType" SG_ 294 CAN_SCAN_INDEX_2LSB_07_01 0;
BA_ "GenSigCmt" SG_ 294 CAN_SCAN_INDEX_2LSB_07_01 "CAN_SCAN_INDEX_2LSB_07_01";
BA_ "GenSigVtEn" SG_ 294 CAN_DET_CONFID_AZIMUTH_07_02 "CAN_DET_CONFID_AZIMUTH_07_02";
BA_ "GenSigVtName" SG_ 294 CAN_DET_CONFID_AZIMUTH_07_02 "CAN_DET_CONFID_AZIMUTH_07_02";
BA_ "GenSigSendType" SG_ 294 CAN_DET_CONFID_AZIMUTH_07_02 0;
BA_ "GenSigCmt" SG_ 294 CAN_DET_CONFID_AZIMUTH_07_02 "CAN_DET_CONFID_AZIMUTH_07_02";
BA_ "GenSigSendType" SG_ 294 CAN_DET_SUPER_RES_TARGET_07_02 0;
BA_ "GenSigCmt" SG_ 294 CAN_DET_SUPER_RES_TARGET_07_02 "CAN_DET_SUPER_RES_TARGET_07_02";
BA_ "GenSigSendType" SG_ 294 CAN_DET_ND_TARGET_07_02 0;
BA_ "GenSigCmt" SG_ 294 CAN_DET_ND_TARGET_07_02 "CAN_DET_ND_TARGET_07_02";
BA_ "GenSigSendType" SG_ 294 CAN_DET_HOST_VEH_CLUTTER_07_02 0;
BA_ "GenSigCmt" SG_ 294 CAN_DET_HOST_VEH_CLUTTER_07_02 "CAN_DET_HOST_VEH_CLUTTER_07_02";
BA_ "GenSigSendType" SG_ 294 CAN_DET_VALID_LEVEL_07_02 0;
BA_ "GenSigCmt" SG_ 294 CAN_DET_VALID_LEVEL_07_02 "CAN_DET_VALID_LEVEL_07_02";
BA_ "GenSigSendType" SG_ 294 CAN_DET_AZIMUTH_07_02 0;
BA_ "GenSigCmt" SG_ 294 CAN_DET_AZIMUTH_07_02 "CAN_DET_AZIMUTH_07_02";
BA_ "GenSigSendType" SG_ 294 CAN_DET_RANGE_07_02 0;
BA_ "GenSigCmt" SG_ 294 CAN_DET_RANGE_07_02 "CAN_DET_RANGE_07_02";
BA_ "GenSigSendType" SG_ 294 CAN_DET_RANGE_RATE_07_02 0;
BA_ "GenSigCmt" SG_ 294 CAN_DET_RANGE_RATE_07_02 "CAN_DET_RANGE_RATE_07_02";
BA_ "GenSigSendType" SG_ 294 CAN_DET_AMPLITUDE_07_02 0;
BA_ "GenSigCmt" SG_ 294 CAN_DET_AMPLITUDE_07_02 "CAN_DET_AMPLITUDE_07_02";
BA_ "GenSigSendType" SG_ 294 CAN_SCAN_INDEX_2LSB_07_02 0;
BA_ "GenSigCmt" SG_ 294 CAN_SCAN_INDEX_2LSB_07_02 "CAN_SCAN_INDEX_2LSB_07_02";
BA_ "GenSigVtEn" SG_ 294 CAN_DET_CONFID_AZIMUTH_07_03 "CAN_DET_CONFID_AZIMUTH_07_03";
BA_ "GenSigVtName" SG_ 294 CAN_DET_CONFID_AZIMUTH_07_03 "CAN_DET_CONFID_AZIMUTH_07_03";
BA_ "GenSigSendType" SG_ 294 CAN_DET_CONFID_AZIMUTH_07_03 0;
BA_ "GenSigCmt" SG_ 294 CAN_DET_CONFID_AZIMUTH_07_03 "CAN_DET_CONFID_AZIMUTH_07_03";
BA_ "GenSigSendType" SG_ 294 CAN_DET_SUPER_RES_TARGET_07_03 0;
BA_ "GenSigCmt" SG_ 294 CAN_DET_SUPER_RES_TARGET_07_03 "CAN_DET_SUPER_RES_TARGET_07_03";
BA_ "GenSigSendType" SG_ 294 CAN_DET_ND_TARGET_07_03 0;
BA_ "GenSigCmt" SG_ 294 CAN_DET_ND_TARGET_07_03 "CAN_DET_ND_TARGET_07_03";
BA_ "GenSigSendType" SG_ 294 CAN_DET_HOST_VEH_CLUTTER_07_03 0;
BA_ "GenSigCmt" SG_ 294 CAN_DET_HOST_VEH_CLUTTER_07_03 "CAN_DET_HOST_VEH_CLUTTER_07_03";
BA_ "GenSigSendType" SG_ 294 CAN_DET_VALID_LEVEL_07_03 0;
BA_ "GenSigCmt" SG_ 294 CAN_DET_VALID_LEVEL_07_03 "CAN_DET_VALID_LEVEL_07_03";
BA_ "GenSigSendType" SG_ 294 CAN_DET_AZIMUTH_07_03 0;
BA_ "GenSigCmt" SG_ 294 CAN_DET_AZIMUTH_07_03 "CAN_DET_AZIMUTH_07_03";
BA_ "GenSigSendType" SG_ 294 CAN_DET_RANGE_07_03 0;
BA_ "GenSigCmt" SG_ 294 CAN_DET_RANGE_07_03 "CAN_DET_RANGE_07_03";
BA_ "GenSigSendType" SG_ 294 CAN_DET_RANGE_RATE_07_03 0;
BA_ "GenSigCmt" SG_ 294 CAN_DET_RANGE_RATE_07_03 "CAN_DET_RANGE_RATE_07_03";
BA_ "GenSigSendType" SG_ 294 CAN_DET_AMPLITUDE_07_03 0;
BA_ "GenSigCmt" SG_ 294 CAN_DET_AMPLITUDE_07_03 "CAN_DET_AMPLITUDE_07_03";
BA_ "GenSigSendType" SG_ 294 CAN_SCAN_INDEX_2LSB_07_03 0;
BA_ "GenSigCmt" SG_ 294 CAN_SCAN_INDEX_2LSB_07_03 "CAN_SCAN_INDEX_2LSB_07_03";
BA_ "GenSigVtEn" SG_ 294 CAN_DET_CONFID_AZIMUTH_07_04 "CAN_DET_CONFID_AZIMUTH_07_04";
BA_ "GenSigVtName" SG_ 294 CAN_DET_CONFID_AZIMUTH_07_04 "CAN_DET_CONFID_AZIMUTH_07_04";
BA_ "GenSigSendType" SG_ 294 CAN_DET_CONFID_AZIMUTH_07_04 0;
BA_ "GenSigCmt" SG_ 294 CAN_DET_CONFID_AZIMUTH_07_04 "CAN_DET_CONFID_AZIMUTH_07_04";
BA_ "GenSigSendType" SG_ 294 CAN_DET_SUPER_RES_TARGET_07_04 0;
BA_ "GenSigCmt" SG_ 294 CAN_DET_SUPER_RES_TARGET_07_04 "CAN_DET_SUPER_RES_TARGET_07_04";
BA_ "GenSigSendType" SG_ 294 CAN_DET_ND_TARGET_07_04 0;
BA_ "GenSigCmt" SG_ 294 CAN_DET_ND_TARGET_07_04 "CAN_DET_ND_TARGET_07_04";
BA_ "GenSigSendType" SG_ 294 CAN_DET_HOST_VEH_CLUTTER_07_04 0;
BA_ "GenSigCmt" SG_ 294 CAN_DET_HOST_VEH_CLUTTER_07_04 "CAN_DET_HOST_VEH_CLUTTER_07_04";
BA_ "GenSigSendType" SG_ 294 CAN_DET_VALID_LEVEL_07_04 0;
BA_ "GenSigCmt" SG_ 294 CAN_DET_VALID_LEVEL_07_04 "CAN_DET_VALID_LEVEL_07_04";
BA_ "GenSigSendType" SG_ 294 CAN_DET_AZIMUTH_07_04 0;
BA_ "GenSigCmt" SG_ 294 CAN_DET_AZIMUTH_07_04 "CAN_DET_AZIMUTH_07_04";
BA_ "GenSigSendType" SG_ 294 CAN_DET_RANGE_07_04 0;
BA_ "GenSigCmt" SG_ 294 CAN_DET_RANGE_07_04 "CAN_DET_RANGE_07_04";
BA_ "GenSigSendType" SG_ 294 CAN_DET_RANGE_RATE_07_04 0;
BA_ "GenSigCmt" SG_ 294 CAN_DET_RANGE_RATE_07_04 "CAN_DET_RANGE_RATE_07_04";
BA_ "GenSigSendType" SG_ 294 CAN_DET_AMPLITUDE_07_04 0;
BA_ "GenSigCmt" SG_ 294 CAN_DET_AMPLITUDE_07_04 "CAN_DET_AMPLITUDE_07_04";
BA_ "GenSigSendType" SG_ 294 CAN_SCAN_INDEX_2LSB_07_04 0;
BA_ "GenSigCmt" SG_ 294 CAN_SCAN_INDEX_2LSB_07_04 "CAN_SCAN_INDEX_2LSB_07_04";
BA_ "GenSigVtEn" SG_ 294 CAN_DET_CONFID_AZIMUTH_07_05 "CAN_DET_CONFID_AZIMUTH_07_05";
BA_ "GenSigVtName" SG_ 294 CAN_DET_CONFID_AZIMUTH_07_05 "CAN_DET_CONFID_AZIMUTH_07_05";
BA_ "GenSigSendType" SG_ 294 CAN_DET_CONFID_AZIMUTH_07_05 0;
BA_ "GenSigCmt" SG_ 294 CAN_DET_CONFID_AZIMUTH_07_05 "CAN_DET_CONFID_AZIMUTH_07_05";
BA_ "GenSigSendType" SG_ 294 CAN_DET_SUPER_RES_TARGET_07_05 0;
BA_ "GenSigCmt" SG_ 294 CAN_DET_SUPER_RES_TARGET_07_05 "CAN_DET_SUPER_RES_TARGET_07_05";
BA_ "GenSigSendType" SG_ 294 CAN_DET_ND_TARGET_07_05 0;
BA_ "GenSigCmt" SG_ 294 CAN_DET_ND_TARGET_07_05 "CAN_DET_ND_TARGET_07_05";
BA_ "GenSigSendType" SG_ 294 CAN_DET_HOST_VEH_CLUTTER_07_05 0;
BA_ "GenSigCmt" SG_ 294 CAN_DET_HOST_VEH_CLUTTER_07_05 "CAN_DET_HOST_VEH_CLUTTER_07_05";
BA_ "GenSigSendType" SG_ 294 CAN_DET_VALID_LEVEL_07_05 0;
BA_ "GenSigCmt" SG_ 294 CAN_DET_VALID_LEVEL_07_05 "CAN_DET_VALID_LEVEL_07_05";
BA_ "GenSigSendType" SG_ 294 CAN_DET_AZIMUTH_07_05 0;
BA_ "GenSigCmt" SG_ 294 CAN_DET_AZIMUTH_07_05 "CAN_DET_AZIMUTH_07_05";
BA_ "GenSigSendType" SG_ 294 CAN_DET_RANGE_07_05 0;
BA_ "GenSigCmt" SG_ 294 CAN_DET_RANGE_07_05 "CAN_DET_RANGE_07_05";
BA_ "GenSigSendType" SG_ 294 CAN_DET_RANGE_RATE_07_05 0;
BA_ "GenSigCmt" SG_ 294 CAN_DET_RANGE_RATE_07_05 "CAN_DET_RANGE_RATE_07_05";
BA_ "GenSigSendType" SG_ 294 CAN_DET_AMPLITUDE_07_05 0;
BA_ "GenSigCmt" SG_ 294 CAN_DET_AMPLITUDE_07_05 "CAN_DET_AMPLITUDE_07_05";
BA_ "GenSigSendType" SG_ 294 CAN_SCAN_INDEX_2LSB_07_05 0;
BA_ "GenSigCmt" SG_ 294 CAN_SCAN_INDEX_2LSB_07_05 "CAN_SCAN_INDEX_2LSB_07_05";
BA_ "GenSigVtEn" SG_ 294 CAN_DET_CONFID_AZIMUTH_07_06 "CAN_DET_CONFID_AZIMUTH_07_06";
BA_ "GenSigVtName" SG_ 294 CAN_DET_CONFID_AZIMUTH_07_06 "CAN_DET_CONFID_AZIMUTH_07_06";
BA_ "GenSigSendType" SG_ 294 CAN_DET_CONFID_AZIMUTH_07_06 0;
BA_ "GenSigCmt" SG_ 294 CAN_DET_CONFID_AZIMUTH_07_06 "CAN_DET_CONFID_AZIMUTH_07_06";
BA_ "GenSigSendType" SG_ 294 CAN_DET_SUPER_RES_TARGET_07_06 0;
BA_ "GenSigCmt" SG_ 294 CAN_DET_SUPER_RES_TARGET_07_06 "CAN_DET_SUPER_RES_TARGET_07_06";
BA_ "GenSigSendType" SG_ 294 CAN_DET_ND_TARGET_07_06 0;
BA_ "GenSigCmt" SG_ 294 CAN_DET_ND_TARGET_07_06 "CAN_DET_ND_TARGET_07_06";
BA_ "GenSigSendType" SG_ 294 CAN_DET_HOST_VEH_CLUTTER_07_06 0;
BA_ "GenSigCmt" SG_ 294 CAN_DET_HOST_VEH_CLUTTER_07_06 "CAN_DET_HOST_VEH_CLUTTER_07_06";
BA_ "GenSigSendType" SG_ 294 CAN_DET_VALID_LEVEL_07_06 0;
BA_ "GenSigCmt" SG_ 294 CAN_DET_VALID_LEVEL_07_06 "CAN_DET_VALID_LEVEL_07_06";
BA_ "GenSigSendType" SG_ 294 CAN_DET_AZIMUTH_07_06 0;
BA_ "GenSigCmt" SG_ 294 CAN_DET_AZIMUTH_07_06 "CAN_DET_AZIMUTH_07_06";
BA_ "GenSigSendType" SG_ 294 CAN_DET_RANGE_07_06 0;
BA_ "GenSigCmt" SG_ 294 CAN_DET_RANGE_07_06 "CAN_DET_RANGE_07_06";
BA_ "GenSigSendType" SG_ 294 CAN_DET_RANGE_RATE_07_06 0;
BA_ "GenSigCmt" SG_ 294 CAN_DET_RANGE_RATE_07_06 "CAN_DET_RANGE_RATE_07_06";
BA_ "GenSigSendType" SG_ 294 CAN_DET_AMPLITUDE_07_06 0;
BA_ "GenSigCmt" SG_ 294 CAN_DET_AMPLITUDE_07_06 "CAN_DET_AMPLITUDE_07_06";
BA_ "GenSigSendType" SG_ 294 CAN_SCAN_INDEX_2LSB_07_06 0;
BA_ "GenSigCmt" SG_ 294 CAN_SCAN_INDEX_2LSB_07_06 "CAN_SCAN_INDEX_2LSB_07_06";
BA_ "GenMsgSendType" BO_ 293 1;
BA_ "GenSigVtEn" SG_ 293 CAN_DET_CONFID_AZIMUTH_06_01 "CAN_DET_CONFID_AZIMUTH_06_01";
BA_ "GenSigVtName" SG_ 293 CAN_DET_CONFID_AZIMUTH_06_01 "CAN_DET_CONFID_AZIMUTH_06_01";
BA_ "GenSigSendType" SG_ 293 CAN_DET_CONFID_AZIMUTH_06_01 0;
BA_ "GenSigCmt" SG_ 293 CAN_DET_CONFID_AZIMUTH_06_01 "CAN_DET_CONFID_AZIMUTH_06_01";
BA_ "GenSigSendType" SG_ 293 CAN_DET_SUPER_RES_TARGET_06_01 0;
BA_ "GenSigCmt" SG_ 293 CAN_DET_SUPER_RES_TARGET_06_01 "CAN_DET_SUPER_RES_TARGET_06_01";
BA_ "GenSigSendType" SG_ 293 CAN_DET_ND_TARGET_06_01 0;
BA_ "GenSigCmt" SG_ 293 CAN_DET_ND_TARGET_06_01 "CAN_DET_ND_TARGET_06_01";
BA_ "GenSigSendType" SG_ 293 CAN_DET_HOST_VEH_CLUTTER_06_01 0;
BA_ "GenSigCmt" SG_ 293 CAN_DET_HOST_VEH_CLUTTER_06_01 "CAN_DET_HOST_VEH_CLUTTER_06_01";
BA_ "GenSigSendType" SG_ 293 CAN_DET_VALID_LEVEL_06_01 0;
BA_ "GenSigCmt" SG_ 293 CAN_DET_VALID_LEVEL_06_01 "CAN_DET_VALID_LEVEL_06_01";
BA_ "GenSigSendType" SG_ 293 CAN_DET_AZIMUTH_06_01 0;
BA_ "GenSigCmt" SG_ 293 CAN_DET_AZIMUTH_06_01 "CAN_DET_AZIMUTH_06_01";
BA_ "GenSigSendType" SG_ 293 CAN_DET_RANGE_06_01 0;
BA_ "GenSigCmt" SG_ 293 CAN_DET_RANGE_06_01 "CAN_DET_RANGE_06_01";
BA_ "GenSigSendType" SG_ 293 CAN_DET_RANGE_RATE_06_01 0;
BA_ "GenSigCmt" SG_ 293 CAN_DET_RANGE_RATE_06_01 "CAN_DET_RANGE_RATE_06_01";
BA_ "GenSigSendType" SG_ 293 CAN_DET_AMPLITUDE_06_01 0;
BA_ "GenSigCmt" SG_ 293 CAN_DET_AMPLITUDE_06_01 "CAN_DET_AMPLITUDE_06_01";
BA_ "GenSigSendType" SG_ 293 CAN_SCAN_INDEX_2LSB_06_01 0;
BA_ "GenSigCmt" SG_ 293 CAN_SCAN_INDEX_2LSB_06_01 "CAN_SCAN_INDEX_2LSB_06_01";
BA_ "GenSigVtEn" SG_ 293 CAN_DET_CONFID_AZIMUTH_06_02 "CAN_DET_CONFID_AZIMUTH_06_02";
BA_ "GenSigVtName" SG_ 293 CAN_DET_CONFID_AZIMUTH_06_02 "CAN_DET_CONFID_AZIMUTH_06_02";
BA_ "GenSigSendType" SG_ 293 CAN_DET_CONFID_AZIMUTH_06_02 0;
BA_ "GenSigCmt" SG_ 293 CAN_DET_CONFID_AZIMUTH_06_02 "CAN_DET_CONFID_AZIMUTH_06_02";
BA_ "GenSigSendType" SG_ 293 CAN_DET_SUPER_RES_TARGET_06_02 0;
BA_ "GenSigCmt" SG_ 293 CAN_DET_SUPER_RES_TARGET_06_02 "CAN_DET_SUPER_RES_TARGET_06_02";
BA_ "GenSigSendType" SG_ 293 CAN_DET_ND_TARGET_06_02 0;
BA_ "GenSigCmt" SG_ 293 CAN_DET_ND_TARGET_06_02 "CAN_DET_ND_TARGET_06_02";
BA_ "GenSigSendType" SG_ 293 CAN_DET_HOST_VEH_CLUTTER_06_02 0;
BA_ "GenSigCmt" SG_ 293 CAN_DET_HOST_VEH_CLUTTER_06_02 "CAN_DET_HOST_VEH_CLUTTER_06_02";
BA_ "GenSigSendType" SG_ 293 CAN_DET_VALID_LEVEL_06_02 0;
BA_ "GenSigCmt" SG_ 293 CAN_DET_VALID_LEVEL_06_02 "CAN_DET_VALID_LEVEL_06_02";
BA_ "GenSigSendType" SG_ 293 CAN_DET_AZIMUTH_06_02 0;
BA_ "GenSigCmt" SG_ 293 CAN_DET_AZIMUTH_06_02 "CAN_DET_AZIMUTH_06_02";
BA_ "GenSigSendType" SG_ 293 CAN_DET_RANGE_06_02 0;
BA_ "GenSigCmt" SG_ 293 CAN_DET_RANGE_06_02 "CAN_DET_RANGE_06_02";
BA_ "GenSigSendType" SG_ 293 CAN_DET_RANGE_RATE_06_02 0;
BA_ "GenSigCmt" SG_ 293 CAN_DET_RANGE_RATE_06_02 "CAN_DET_RANGE_RATE_06_02";
BA_ "GenSigSendType" SG_ 293 CAN_DET_AMPLITUDE_06_02 0;
BA_ "GenSigCmt" SG_ 293 CAN_DET_AMPLITUDE_06_02 "CAN_DET_AMPLITUDE_06_02";
BA_ "GenSigSendType" SG_ 293 CAN_SCAN_INDEX_2LSB_06_02 0;
BA_ "GenSigCmt" SG_ 293 CAN_SCAN_INDEX_2LSB_06_02 "CAN_SCAN_INDEX_2LSB_06_02";
BA_ "GenSigVtEn" SG_ 293 CAN_DET_CONFID_AZIMUTH_06_03 "CAN_DET_CONFID_AZIMUTH_06_03";
BA_ "GenSigVtName" SG_ 293 CAN_DET_CONFID_AZIMUTH_06_03 "CAN_DET_CONFID_AZIMUTH_06_03";
BA_ "GenSigSendType" SG_ 293 CAN_DET_CONFID_AZIMUTH_06_03 0;
BA_ "GenSigCmt" SG_ 293 CAN_DET_CONFID_AZIMUTH_06_03 "CAN_DET_CONFID_AZIMUTH_06_03";
BA_ "GenSigSendType" SG_ 293 CAN_DET_SUPER_RES_TARGET_06_03 0;
BA_ "GenSigCmt" SG_ 293 CAN_DET_SUPER_RES_TARGET_06_03 "CAN_DET_SUPER_RES_TARGET_06_03";
BA_ "GenSigSendType" SG_ 293 CAN_DET_ND_TARGET_06_03 0;
BA_ "GenSigCmt" SG_ 293 CAN_DET_ND_TARGET_06_03 "CAN_DET_ND_TARGET_06_03";
BA_ "GenSigSendType" SG_ 293 CAN_DET_HOST_VEH_CLUTTER_06_03 0;
BA_ "GenSigCmt" SG_ 293 CAN_DET_HOST_VEH_CLUTTER_06_03 "CAN_DET_HOST_VEH_CLUTTER_06_03";
BA_ "GenSigSendType" SG_ 293 CAN_DET_VALID_LEVEL_06_03 0;
BA_ "GenSigCmt" SG_ 293 CAN_DET_VALID_LEVEL_06_03 "CAN_DET_VALID_LEVEL_06_03";
BA_ "GenSigSendType" SG_ 293 CAN_DET_AZIMUTH_06_03 0;
BA_ "GenSigCmt" SG_ 293 CAN_DET_AZIMUTH_06_03 "CAN_DET_AZIMUTH_06_03";
BA_ "GenSigSendType" SG_ 293 CAN_DET_RANGE_06_03 0;
BA_ "GenSigCmt" SG_ 293 CAN_DET_RANGE_06_03 "CAN_DET_RANGE_06_03";
BA_ "GenSigSendType" SG_ 293 CAN_DET_RANGE_RATE_06_03 0;
BA_ "GenSigCmt" SG_ 293 CAN_DET_RANGE_RATE_06_03 "CAN_DET_RANGE_RATE_06_03";
BA_ "GenSigSendType" SG_ 293 CAN_DET_AMPLITUDE_06_03 0;
BA_ "GenSigCmt" SG_ 293 CAN_DET_AMPLITUDE_06_03 "CAN_DET_AMPLITUDE_06_03";
BA_ "GenSigSendType" SG_ 293 CAN_SCAN_INDEX_2LSB_06_03 0;
BA_ "GenSigCmt" SG_ 293 CAN_SCAN_INDEX_2LSB_06_03 "CAN_SCAN_INDEX_2LSB_06_03";
BA_ "GenSigVtEn" SG_ 293 CAN_DET_CONFID_AZIMUTH_06_04 "CAN_DET_CONFID_AZIMUTH_06_04";
BA_ "GenSigVtName" SG_ 293 CAN_DET_CONFID_AZIMUTH_06_04 "CAN_DET_CONFID_AZIMUTH_06_04";
BA_ "GenSigSendType" SG_ 293 CAN_DET_CONFID_AZIMUTH_06_04 0;
BA_ "GenSigCmt" SG_ 293 CAN_DET_CONFID_AZIMUTH_06_04 "CAN_DET_CONFID_AZIMUTH_06_04";
BA_ "GenSigSendType" SG_ 293 CAN_DET_SUPER_RES_TARGET_06_04 0;
BA_ "GenSigCmt" SG_ 293 CAN_DET_SUPER_RES_TARGET_06_04 "CAN_DET_SUPER_RES_TARGET_06_04";
BA_ "GenSigSendType" SG_ 293 CAN_DET_ND_TARGET_06_04 0;
BA_ "GenSigCmt" SG_ 293 CAN_DET_ND_TARGET_06_04 "CAN_DET_ND_TARGET_06_04";
BA_ "GenSigSendType" SG_ 293 CAN_DET_HOST_VEH_CLUTTER_06_04 0;
BA_ "GenSigCmt" SG_ 293 CAN_DET_HOST_VEH_CLUTTER_06_04 "CAN_DET_HOST_VEH_CLUTTER_06_04";
BA_ "GenSigSendType" SG_ 293 CAN_DET_VALID_LEVEL_06_04 0;
BA_ "GenSigCmt" SG_ 293 CAN_DET_VALID_LEVEL_06_04 "CAN_DET_VALID_LEVEL_06_04";
BA_ "GenSigSendType" SG_ 293 CAN_DET_AZIMUTH_06_04 0;
BA_ "GenSigCmt" SG_ 293 CAN_DET_AZIMUTH_06_04 "CAN_DET_AZIMUTH_06_04";
BA_ "GenSigSendType" SG_ 293 CAN_DET_RANGE_06_04 0;
BA_ "GenSigCmt" SG_ 293 CAN_DET_RANGE_06_04 "CAN_DET_RANGE_06_04";
BA_ "GenSigSendType" SG_ 293 CAN_DET_RANGE_RATE_06_04 0;
BA_ "GenSigCmt" SG_ 293 CAN_DET_RANGE_RATE_06_04 "CAN_DET_RANGE_RATE_06_04";
BA_ "GenSigSendType" SG_ 293 CAN_DET_AMPLITUDE_06_04 0;
BA_ "GenSigCmt" SG_ 293 CAN_DET_AMPLITUDE_06_04 "CAN_DET_AMPLITUDE_06_04";
BA_ "GenSigSendType" SG_ 293 CAN_SCAN_INDEX_2LSB_06_04 0;
BA_ "GenSigCmt" SG_ 293 CAN_SCAN_INDEX_2LSB_06_04 "CAN_SCAN_INDEX_2LSB_06_04";
BA_ "GenSigVtEn" SG_ 293 CAN_DET_CONFID_AZIMUTH_06_05 "CAN_DET_CONFID_AZIMUTH_06_05";
BA_ "GenSigVtName" SG_ 293 CAN_DET_CONFID_AZIMUTH_06_05 "CAN_DET_CONFID_AZIMUTH_06_05";
BA_ "GenSigSendType" SG_ 293 CAN_DET_CONFID_AZIMUTH_06_05 0;
BA_ "GenSigCmt" SG_ 293 CAN_DET_CONFID_AZIMUTH_06_05 "CAN_DET_CONFID_AZIMUTH_06_05";
BA_ "GenSigSendType" SG_ 293 CAN_DET_SUPER_RES_TARGET_06_05 0;
BA_ "GenSigCmt" SG_ 293 CAN_DET_SUPER_RES_TARGET_06_05 "CAN_DET_SUPER_RES_TARGET_06_05";
BA_ "GenSigSendType" SG_ 293 CAN_DET_ND_TARGET_06_05 0;
BA_ "GenSigCmt" SG_ 293 CAN_DET_ND_TARGET_06_05 "CAN_DET_ND_TARGET_06_05";
BA_ "GenSigSendType" SG_ 293 CAN_DET_HOST_VEH_CLUTTER_06_05 0;
BA_ "GenSigCmt" SG_ 293 CAN_DET_HOST_VEH_CLUTTER_06_05 "CAN_DET_HOST_VEH_CLUTTER_06_05";
BA_ "GenSigSendType" SG_ 293 CAN_DET_VALID_LEVEL_06_05 0;
BA_ "GenSigCmt" SG_ 293 CAN_DET_VALID_LEVEL_06_05 "CAN_DET_VALID_LEVEL_06_05";
BA_ "GenSigSendType" SG_ 293 CAN_DET_AZIMUTH_06_05 0;
BA_ "GenSigCmt" SG_ 293 CAN_DET_AZIMUTH_06_05 "CAN_DET_AZIMUTH_06_05";
BA_ "GenSigSendType" SG_ 293 CAN_DET_RANGE_06_05 0;
BA_ "GenSigCmt" SG_ 293 CAN_DET_RANGE_06_05 "CAN_DET_RANGE_06_05";
BA_ "GenSigSendType" SG_ 293 CAN_DET_RANGE_RATE_06_05 0;
BA_ "GenSigCmt" SG_ 293 CAN_DET_RANGE_RATE_06_05 "CAN_DET_RANGE_RATE_06_05";
BA_ "GenSigSendType" SG_ 293 CAN_DET_AMPLITUDE_06_05 0;
BA_ "GenSigCmt" SG_ 293 CAN_DET_AMPLITUDE_06_05 "CAN_DET_AMPLITUDE_06_05";
BA_ "GenSigSendType" SG_ 293 CAN_SCAN_INDEX_2LSB_06_05 0;
BA_ "GenSigCmt" SG_ 293 CAN_SCAN_INDEX_2LSB_06_05 "CAN_SCAN_INDEX_2LSB_06_05";
BA_ "GenSigVtEn" SG_ 293 CAN_DET_CONFID_AZIMUTH_06_06 "CAN_DET_CONFID_AZIMUTH_06_06";
BA_ "GenSigVtName" SG_ 293 CAN_DET_CONFID_AZIMUTH_06_06 "CAN_DET_CONFID_AZIMUTH_06_06";
BA_ "GenSigSendType" SG_ 293 CAN_DET_CONFID_AZIMUTH_06_06 0;
BA_ "GenSigCmt" SG_ 293 CAN_DET_CONFID_AZIMUTH_06_06 "CAN_DET_CONFID_AZIMUTH_06_06";
BA_ "GenSigSendType" SG_ 293 CAN_DET_SUPER_RES_TARGET_06_06 0;
BA_ "GenSigCmt" SG_ 293 CAN_DET_SUPER_RES_TARGET_06_06 "CAN_DET_SUPER_RES_TARGET_06_06";
BA_ "GenSigSendType" SG_ 293 CAN_DET_ND_TARGET_06_06 0;
BA_ "GenSigCmt" SG_ 293 CAN_DET_ND_TARGET_06_06 "CAN_DET_ND_TARGET_06_06";
BA_ "GenSigSendType" SG_ 293 CAN_DET_HOST_VEH_CLUTTER_06_06 0;
BA_ "GenSigCmt" SG_ 293 CAN_DET_HOST_VEH_CLUTTER_06_06 "CAN_DET_HOST_VEH_CLUTTER_06_06";
BA_ "GenSigSendType" SG_ 293 CAN_DET_VALID_LEVEL_06_06 0;
BA_ "GenSigCmt" SG_ 293 CAN_DET_VALID_LEVEL_06_06 "CAN_DET_VALID_LEVEL_06_06";
BA_ "GenSigSendType" SG_ 293 CAN_DET_AZIMUTH_06_06 0;
BA_ "GenSigCmt" SG_ 293 CAN_DET_AZIMUTH_06_06 "CAN_DET_AZIMUTH_06_06";
BA_ "GenSigSendType" SG_ 293 CAN_DET_RANGE_06_06 0;
BA_ "GenSigCmt" SG_ 293 CAN_DET_RANGE_06_06 "CAN_DET_RANGE_06_06";
BA_ "GenSigSendType" SG_ 293 CAN_DET_RANGE_RATE_06_06 0;
BA_ "GenSigCmt" SG_ 293 CAN_DET_RANGE_RATE_06_06 "CAN_DET_RANGE_RATE_06_06";
BA_ "GenSigSendType" SG_ 293 CAN_DET_AMPLITUDE_06_06 0;
BA_ "GenSigCmt" SG_ 293 CAN_DET_AMPLITUDE_06_06 "CAN_DET_AMPLITUDE_06_06";
BA_ "GenSigSendType" SG_ 293 CAN_SCAN_INDEX_2LSB_06_06 0;
BA_ "GenSigCmt" SG_ 293 CAN_SCAN_INDEX_2LSB_06_06 "CAN_SCAN_INDEX_2LSB_06_06";
BA_ "GenMsgSendType" BO_ 292 1;
BA_ "GenSigVtEn" SG_ 292 CAN_DET_CONFID_AZIMUTH_05_01 "CAN_DET_CONFID_AZIMUTH_05_01";
BA_ "GenSigVtName" SG_ 292 CAN_DET_CONFID_AZIMUTH_05_01 "CAN_DET_CONFID_AZIMUTH_05_01";
BA_ "GenSigSendType" SG_ 292 CAN_DET_CONFID_AZIMUTH_05_01 0;
BA_ "GenSigCmt" SG_ 292 CAN_DET_CONFID_AZIMUTH_05_01 "CAN_DET_CONFID_AZIMUTH_05_01";
BA_ "GenSigSendType" SG_ 292 CAN_DET_SUPER_RES_TARGET_05_01 0;
BA_ "GenSigCmt" SG_ 292 CAN_DET_SUPER_RES_TARGET_05_01 "CAN_DET_SUPER_RES_TARGET_05_01";
BA_ "GenSigSendType" SG_ 292 CAN_DET_ND_TARGET_05_01 0;
BA_ "GenSigCmt" SG_ 292 CAN_DET_ND_TARGET_05_01 "CAN_DET_ND_TARGET_05_01";
BA_ "GenSigSendType" SG_ 292 CAN_DET_HOST_VEH_CLUTTER_05_01 0;
BA_ "GenSigCmt" SG_ 292 CAN_DET_HOST_VEH_CLUTTER_05_01 "CAN_DET_HOST_VEH_CLUTTER_05_01";
BA_ "GenSigSendType" SG_ 292 CAN_DET_VALID_LEVEL_05_01 0;
BA_ "GenSigCmt" SG_ 292 CAN_DET_VALID_LEVEL_05_01 "CAN_DET_VALID_LEVEL_05_01";
BA_ "GenSigSendType" SG_ 292 CAN_DET_AZIMUTH_05_01 0;
BA_ "GenSigCmt" SG_ 292 CAN_DET_AZIMUTH_05_01 "CAN_DET_AZIMUTH_05_01";
BA_ "GenSigSendType" SG_ 292 CAN_DET_RANGE_05_01 0;
BA_ "GenSigCmt" SG_ 292 CAN_DET_RANGE_05_01 "CAN_DET_RANGE_05_01";
BA_ "GenSigSendType" SG_ 292 CAN_DET_RANGE_RATE_05_01 0;
BA_ "GenSigCmt" SG_ 292 CAN_DET_RANGE_RATE_05_01 "CAN_DET_RANGE_RATE_05_01";
BA_ "GenSigSendType" SG_ 292 CAN_DET_AMPLITUDE_05_01 0;
BA_ "GenSigCmt" SG_ 292 CAN_DET_AMPLITUDE_05_01 "CAN_DET_AMPLITUDE_05_01";
BA_ "GenSigSendType" SG_ 292 CAN_SCAN_INDEX_2LSB_05_01 0;
BA_ "GenSigCmt" SG_ 292 CAN_SCAN_INDEX_2LSB_05_01 "CAN_SCAN_INDEX_2LSB_05_01";
BA_ "GenSigVtEn" SG_ 292 CAN_DET_CONFID_AZIMUTH_05_02 "CAN_DET_CONFID_AZIMUTH_05_02";
BA_ "GenSigVtName" SG_ 292 CAN_DET_CONFID_AZIMUTH_05_02 "CAN_DET_CONFID_AZIMUTH_05_02";
BA_ "GenSigSendType" SG_ 292 CAN_DET_CONFID_AZIMUTH_05_02 0;
BA_ "GenSigCmt" SG_ 292 CAN_DET_CONFID_AZIMUTH_05_02 "CAN_DET_CONFID_AZIMUTH_05_02";
BA_ "GenSigSendType" SG_ 292 CAN_DET_SUPER_RES_TARGET_05_02 0;
BA_ "GenSigCmt" SG_ 292 CAN_DET_SUPER_RES_TARGET_05_02 "CAN_DET_SUPER_RES_TARGET_05_02";
BA_ "GenSigSendType" SG_ 292 CAN_DET_ND_TARGET_05_02 0;
BA_ "GenSigCmt" SG_ 292 CAN_DET_ND_TARGET_05_02 "CAN_DET_ND_TARGET_05_02";
BA_ "GenSigSendType" SG_ 292 CAN_DET_HOST_VEH_CLUTTER_05_02 0;
BA_ "GenSigCmt" SG_ 292 CAN_DET_HOST_VEH_CLUTTER_05_02 "CAN_DET_HOST_VEH_CLUTTER_05_02";
BA_ "GenSigSendType" SG_ 292 CAN_DET_VALID_LEVEL_05_02 0;
BA_ "GenSigCmt" SG_ 292 CAN_DET_VALID_LEVEL_05_02 "CAN_DET_VALID_LEVEL_05_02";
BA_ "GenSigSendType" SG_ 292 CAN_DET_AZIMUTH_05_02 0;
BA_ "GenSigCmt" SG_ 292 CAN_DET_AZIMUTH_05_02 "CAN_DET_AZIMUTH_05_02";
BA_ "GenSigSendType" SG_ 292 CAN_DET_RANGE_05_02 0;
BA_ "GenSigCmt" SG_ 292 CAN_DET_RANGE_05_02 "CAN_DET_RANGE_05_02";
BA_ "GenSigSendType" SG_ 292 CAN_DET_RANGE_RATE_05_02 0;
BA_ "GenSigCmt" SG_ 292 CAN_DET_RANGE_RATE_05_02 "CAN_DET_RANGE_RATE_05_02";
BA_ "GenSigSendType" SG_ 292 CAN_DET_AMPLITUDE_05_02 0;
BA_ "GenSigCmt" SG_ 292 CAN_DET_AMPLITUDE_05_02 "CAN_DET_AMPLITUDE_05_02";
BA_ "GenSigSendType" SG_ 292 CAN_SCAN_INDEX_2LSB_05_02 0;
BA_ "GenSigCmt" SG_ 292 CAN_SCAN_INDEX_2LSB_05_02 "CAN_SCAN_INDEX_2LSB_05_02";
BA_ "GenSigVtEn" SG_ 292 CAN_DET_CONFID_AZIMUTH_05_03 "CAN_DET_CONFID_AZIMUTH_05_03";
BA_ "GenSigVtName" SG_ 292 CAN_DET_CONFID_AZIMUTH_05_03 "CAN_DET_CONFID_AZIMUTH_05_03";
BA_ "GenSigSendType" SG_ 292 CAN_DET_CONFID_AZIMUTH_05_03 0;
BA_ "GenSigCmt" SG_ 292 CAN_DET_CONFID_AZIMUTH_05_03 "CAN_DET_CONFID_AZIMUTH_05_03";
BA_ "GenSigSendType" SG_ 292 CAN_DET_SUPER_RES_TARGET_05_03 0;
BA_ "GenSigCmt" SG_ 292 CAN_DET_SUPER_RES_TARGET_05_03 "CAN_DET_SUPER_RES_TARGET_05_03";
BA_ "GenSigSendType" SG_ 292 CAN_DET_ND_TARGET_05_03 0;
BA_ "GenSigCmt" SG_ 292 CAN_DET_ND_TARGET_05_03 "CAN_DET_ND_TARGET_05_03";
BA_ "GenSigSendType" SG_ 292 CAN_DET_HOST_VEH_CLUTTER_05_03 0;
BA_ "GenSigCmt" SG_ 292 CAN_DET_HOST_VEH_CLUTTER_05_03 "CAN_DET_HOST_VEH_CLUTTER_05_03";
BA_ "GenSigSendType" SG_ 292 CAN_DET_VALID_LEVEL_05_03 0;
BA_ "GenSigCmt" SG_ 292 CAN_DET_VALID_LEVEL_05_03 "CAN_DET_VALID_LEVEL_05_03";
BA_ "GenSigSendType" SG_ 292 CAN_DET_AZIMUTH_05_03 0;
BA_ "GenSigCmt" SG_ 292 CAN_DET_AZIMUTH_05_03 "CAN_DET_AZIMUTH_05_03";
BA_ "GenSigSendType" SG_ 292 CAN_DET_RANGE_05_03 0;
BA_ "GenSigCmt" SG_ 292 CAN_DET_RANGE_05_03 "CAN_DET_RANGE_05_03";
BA_ "GenSigSendType" SG_ 292 CAN_DET_RANGE_RATE_05_03 0;
BA_ "GenSigCmt" SG_ 292 CAN_DET_RANGE_RATE_05_03 "CAN_DET_RANGE_RATE_05_03";
BA_ "GenSigSendType" SG_ 292 CAN_DET_AMPLITUDE_05_03 0;
BA_ "GenSigCmt" SG_ 292 CAN_DET_AMPLITUDE_05_03 "CAN_DET_AMPLITUDE_05_03";
BA_ "GenSigSendType" SG_ 292 CAN_SCAN_INDEX_2LSB_05_03 0;
BA_ "GenSigCmt" SG_ 292 CAN_SCAN_INDEX_2LSB_05_03 "CAN_SCAN_INDEX_2LSB_05_03";
BA_ "GenSigVtEn" SG_ 292 CAN_DET_CONFID_AZIMUTH_05_04 "CAN_DET_CONFID_AZIMUTH_05_04";
BA_ "GenSigVtName" SG_ 292 CAN_DET_CONFID_AZIMUTH_05_04 "CAN_DET_CONFID_AZIMUTH_05_04";
BA_ "GenSigSendType" SG_ 292 CAN_DET_CONFID_AZIMUTH_05_04 0;
BA_ "GenSigCmt" SG_ 292 CAN_DET_CONFID_AZIMUTH_05_04 "CAN_DET_CONFID_AZIMUTH_05_04";
BA_ "GenSigSendType" SG_ 292 CAN_DET_SUPER_RES_TARGET_05_04 0;
BA_ "GenSigCmt" SG_ 292 CAN_DET_SUPER_RES_TARGET_05_04 "CAN_DET_SUPER_RES_TARGET_05_04";
BA_ "GenSigSendType" SG_ 292 CAN_DET_ND_TARGET_05_04 0;
BA_ "GenSigCmt" SG_ 292 CAN_DET_ND_TARGET_05_04 "CAN_DET_ND_TARGET_05_04";
BA_ "GenSigSendType" SG_ 292 CAN_DET_HOST_VEH_CLUTTER_05_04 0;
BA_ "GenSigCmt" SG_ 292 CAN_DET_HOST_VEH_CLUTTER_05_04 "CAN_DET_HOST_VEH_CLUTTER_05_04";
BA_ "GenSigSendType" SG_ 292 CAN_DET_VALID_LEVEL_05_04 0;
BA_ "GenSigCmt" SG_ 292 CAN_DET_VALID_LEVEL_05_04 "CAN_DET_VALID_LEVEL_05_04";
BA_ "GenSigSendType" SG_ 292 CAN_DET_AZIMUTH_05_04 0;
BA_ "GenSigCmt" SG_ 292 CAN_DET_AZIMUTH_05_04 "CAN_DET_AZIMUTH_05_04";
BA_ "GenSigSendType" SG_ 292 CAN_DET_RANGE_05_04 0;
BA_ "GenSigCmt" SG_ 292 CAN_DET_RANGE_05_04 "CAN_DET_RANGE_05_04";
BA_ "GenSigSendType" SG_ 292 CAN_DET_RANGE_RATE_05_04 0;
BA_ "GenSigCmt" SG_ 292 CAN_DET_RANGE_RATE_05_04 "CAN_DET_RANGE_RATE_05_04";
BA_ "GenSigSendType" SG_ 292 CAN_DET_AMPLITUDE_05_04 0;
BA_ "GenSigCmt" SG_ 292 CAN_DET_AMPLITUDE_05_04 "CAN_DET_AMPLITUDE_05_04";
BA_ "GenSigSendType" SG_ 292 CAN_SCAN_INDEX_2LSB_05_04 0;
BA_ "GenSigCmt" SG_ 292 CAN_SCAN_INDEX_2LSB_05_04 "CAN_SCAN_INDEX_2LSB_05_04";
BA_ "GenSigVtEn" SG_ 292 CAN_DET_CONFID_AZIMUTH_05_05 "CAN_DET_CONFID_AZIMUTH_05_05";
BA_ "GenSigVtName" SG_ 292 CAN_DET_CONFID_AZIMUTH_05_05 "CAN_DET_CONFID_AZIMUTH_05_05";
BA_ "GenSigSendType" SG_ 292 CAN_DET_CONFID_AZIMUTH_05_05 0;
BA_ "GenSigCmt" SG_ 292 CAN_DET_CONFID_AZIMUTH_05_05 "CAN_DET_CONFID_AZIMUTH_05_05";
BA_ "GenSigSendType" SG_ 292 CAN_DET_SUPER_RES_TARGET_05_05 0;
BA_ "GenSigCmt" SG_ 292 CAN_DET_SUPER_RES_TARGET_05_05 "CAN_DET_SUPER_RES_TARGET_05_05";
BA_ "GenSigSendType" SG_ 292 CAN_DET_ND_TARGET_05_05 0;
BA_ "GenSigCmt" SG_ 292 CAN_DET_ND_TARGET_05_05 "CAN_DET_ND_TARGET_05_05";
BA_ "GenSigSendType" SG_ 292 CAN_DET_HOST_VEH_CLUTTER_05_05 0;
BA_ "GenSigCmt" SG_ 292 CAN_DET_HOST_VEH_CLUTTER_05_05 "CAN_DET_HOST_VEH_CLUTTER_05_05";
BA_ "GenSigSendType" SG_ 292 CAN_DET_VALID_LEVEL_05_05 0;
BA_ "GenSigCmt" SG_ 292 CAN_DET_VALID_LEVEL_05_05 "CAN_DET_VALID_LEVEL_05_05";
BA_ "GenSigSendType" SG_ 292 CAN_DET_AZIMUTH_05_05 0;
BA_ "GenSigCmt" SG_ 292 CAN_DET_AZIMUTH_05_05 "CAN_DET_AZIMUTH_05_05";
BA_ "GenSigSendType" SG_ 292 CAN_DET_RANGE_05_05 0;
BA_ "GenSigCmt" SG_ 292 CAN_DET_RANGE_05_05 "CAN_DET_RANGE_05_05";
BA_ "GenSigSendType" SG_ 292 CAN_DET_RANGE_RATE_05_05 0;
BA_ "GenSigCmt" SG_ 292 CAN_DET_RANGE_RATE_05_05 "CAN_DET_RANGE_RATE_05_05";
BA_ "GenSigSendType" SG_ 292 CAN_DET_AMPLITUDE_05_05 0;
BA_ "GenSigCmt" SG_ 292 CAN_DET_AMPLITUDE_05_05 "CAN_DET_AMPLITUDE_05_05";
BA_ "GenSigSendType" SG_ 292 CAN_SCAN_INDEX_2LSB_05_05 0;
BA_ "GenSigCmt" SG_ 292 CAN_SCAN_INDEX_2LSB_05_05 "CAN_SCAN_INDEX_2LSB_05_05";
BA_ "GenSigVtEn" SG_ 292 CAN_DET_CONFID_AZIMUTH_05_06 "CAN_DET_CONFID_AZIMUTH_05_06";
BA_ "GenSigVtName" SG_ 292 CAN_DET_CONFID_AZIMUTH_05_06 "CAN_DET_CONFID_AZIMUTH_05_06";
BA_ "GenSigSendType" SG_ 292 CAN_DET_CONFID_AZIMUTH_05_06 0;
BA_ "GenSigCmt" SG_ 292 CAN_DET_CONFID_AZIMUTH_05_06 "CAN_DET_CONFID_AZIMUTH_05_06";
BA_ "GenSigSendType" SG_ 292 CAN_DET_SUPER_RES_TARGET_05_06 0;
BA_ "GenSigCmt" SG_ 292 CAN_DET_SUPER_RES_TARGET_05_06 "CAN_DET_SUPER_RES_TARGET_05_06";
BA_ "GenSigSendType" SG_ 292 CAN_DET_ND_TARGET_05_06 0;
BA_ "GenSigCmt" SG_ 292 CAN_DET_ND_TARGET_05_06 "CAN_DET_ND_TARGET_05_06";
BA_ "GenSigSendType" SG_ 292 CAN_DET_HOST_VEH_CLUTTER_05_06 0;
BA_ "GenSigCmt" SG_ 292 CAN_DET_HOST_VEH_CLUTTER_05_06 "CAN_DET_HOST_VEH_CLUTTER_05_06";
BA_ "GenSigSendType" SG_ 292 CAN_DET_VALID_LEVEL_05_06 0;
BA_ "GenSigCmt" SG_ 292 CAN_DET_VALID_LEVEL_05_06 "CAN_DET_VALID_LEVEL_05_06";
BA_ "GenSigSendType" SG_ 292 CAN_DET_AZIMUTH_05_06 0;
BA_ "GenSigCmt" SG_ 292 CAN_DET_AZIMUTH_05_06 "CAN_DET_AZIMUTH_05_06";
BA_ "GenSigSendType" SG_ 292 CAN_DET_RANGE_05_06 0;
BA_ "GenSigCmt" SG_ 292 CAN_DET_RANGE_05_06 "CAN_DET_RANGE_05_06";
BA_ "GenSigSendType" SG_ 292 CAN_DET_RANGE_RATE_05_06 0;
BA_ "GenSigCmt" SG_ 292 CAN_DET_RANGE_RATE_05_06 "CAN_DET_RANGE_RATE_05_06";
BA_ "GenSigSendType" SG_ 292 CAN_DET_AMPLITUDE_05_06 0;
BA_ "GenSigCmt" SG_ 292 CAN_DET_AMPLITUDE_05_06 "CAN_DET_AMPLITUDE_05_06";
BA_ "GenSigSendType" SG_ 292 CAN_SCAN_INDEX_2LSB_05_06 0;
BA_ "GenSigCmt" SG_ 292 CAN_SCAN_INDEX_2LSB_05_06 "CAN_SCAN_INDEX_2LSB_05_06";
BA_ "GenMsgSendType" BO_ 290 1;
BA_ "GenSigVtEn" SG_ 290 CAN_DET_CONFID_AZIMUTH_03_01 "CAN_DET_CONFID_AZIMUTH_03_01";
BA_ "GenSigVtName" SG_ 290 CAN_DET_CONFID_AZIMUTH_03_01 "CAN_DET_CONFID_AZIMUTH_03_01";
BA_ "GenSigSendType" SG_ 290 CAN_DET_CONFID_AZIMUTH_03_01 0;
BA_ "GenSigCmt" SG_ 290 CAN_DET_CONFID_AZIMUTH_03_01 "CAN_DET_CONFID_AZIMUTH_03_01";
BA_ "GenSigSendType" SG_ 290 CAN_DET_SUPER_RES_TARGET_03_01 0;
BA_ "GenSigCmt" SG_ 290 CAN_DET_SUPER_RES_TARGET_03_01 "CAN_DET_SUPER_RES_TARGET_03_01";
BA_ "GenSigSendType" SG_ 290 CAN_DET_ND_TARGET_03_01 0;
BA_ "GenSigCmt" SG_ 290 CAN_DET_ND_TARGET_03_01 "CAN_DET_ND_TARGET_03_01";
BA_ "GenSigSendType" SG_ 290 CAN_DET_HOST_VEH_CLUTTER_03_01 0;
BA_ "GenSigCmt" SG_ 290 CAN_DET_HOST_VEH_CLUTTER_03_01 "CAN_DET_HOST_VEH_CLUTTER_03_01";
BA_ "GenSigSendType" SG_ 290 CAN_DET_VALID_LEVEL_03_01 0;
BA_ "GenSigCmt" SG_ 290 CAN_DET_VALID_LEVEL_03_01 "CAN_DET_VALID_LEVEL_03_01";
BA_ "GenSigSendType" SG_ 290 CAN_DET_AZIMUTH_03_01 0;
BA_ "GenSigCmt" SG_ 290 CAN_DET_AZIMUTH_03_01 "CAN_DET_AZIMUTH_03_01";
BA_ "GenSigSendType" SG_ 290 CAN_DET_RANGE_03_01 0;
BA_ "GenSigCmt" SG_ 290 CAN_DET_RANGE_03_01 "CAN_DET_RANGE_03_01";
BA_ "GenSigSendType" SG_ 290 CAN_DET_RANGE_RATE_03_01 0;
BA_ "GenSigCmt" SG_ 290 CAN_DET_RANGE_RATE_03_01 "CAN_DET_RANGE_RATE_03_01";
BA_ "GenSigSendType" SG_ 290 CAN_DET_AMPLITUDE_03_01 0;
BA_ "GenSigCmt" SG_ 290 CAN_DET_AMPLITUDE_03_01 "CAN_DET_AMPLITUDE_03_01";
BA_ "GenSigSendType" SG_ 290 CAN_SCAN_INDEX_2LSB_03_01 0;
BA_ "GenSigCmt" SG_ 290 CAN_SCAN_INDEX_2LSB_03_01 "CAN_SCAN_INDEX_2LSB_03_01";
BA_ "GenSigVtEn" SG_ 290 CAN_DET_CONFID_AZIMUTH_03_02 "CAN_DET_CONFID_AZIMUTH_03_02";
BA_ "GenSigVtName" SG_ 290 CAN_DET_CONFID_AZIMUTH_03_02 "CAN_DET_CONFID_AZIMUTH_03_02";
BA_ "GenSigSendType" SG_ 290 CAN_DET_CONFID_AZIMUTH_03_02 0;
BA_ "GenSigCmt" SG_ 290 CAN_DET_CONFID_AZIMUTH_03_02 "CAN_DET_CONFID_AZIMUTH_03_02";
BA_ "GenSigSendType" SG_ 290 CAN_DET_SUPER_RES_TARGET_03_02 0;
BA_ "GenSigCmt" SG_ 290 CAN_DET_SUPER_RES_TARGET_03_02 "CAN_DET_SUPER_RES_TARGET_03_02";
BA_ "GenSigSendType" SG_ 290 CAN_DET_ND_TARGET_03_02 0;
BA_ "GenSigCmt" SG_ 290 CAN_DET_ND_TARGET_03_02 "CAN_DET_ND_TARGET_03_02";
BA_ "GenSigSendType" SG_ 290 CAN_DET_HOST_VEH_CLUTTER_03_02 0;
BA_ "GenSigCmt" SG_ 290 CAN_DET_HOST_VEH_CLUTTER_03_02 "CAN_DET_HOST_VEH_CLUTTER_03_02";
BA_ "GenSigSendType" SG_ 290 CAN_DET_VALID_LEVEL_03_02 0;
BA_ "GenSigCmt" SG_ 290 CAN_DET_VALID_LEVEL_03_02 "CAN_DET_VALID_LEVEL_03_02";
BA_ "GenSigSendType" SG_ 290 CAN_DET_AZIMUTH_03_02 0;
BA_ "GenSigCmt" SG_ 290 CAN_DET_AZIMUTH_03_02 "CAN_DET_AZIMUTH_03_02";
BA_ "GenSigSendType" SG_ 290 CAN_DET_RANGE_03_02 0;
BA_ "GenSigCmt" SG_ 290 CAN_DET_RANGE_03_02 "CAN_DET_RANGE_03_02";
BA_ "GenSigSendType" SG_ 290 CAN_DET_RANGE_RATE_03_02 0;
BA_ "GenSigCmt" SG_ 290 CAN_DET_RANGE_RATE_03_02 "CAN_DET_RANGE_RATE_03_02";
BA_ "GenSigSendType" SG_ 290 CAN_DET_AMPLITUDE_03_02 0;
BA_ "GenSigCmt" SG_ 290 CAN_DET_AMPLITUDE_03_02 "CAN_DET_AMPLITUDE_03_02";
BA_ "GenSigSendType" SG_ 290 CAN_SCAN_INDEX_2LSB_03_02 0;
BA_ "GenSigCmt" SG_ 290 CAN_SCAN_INDEX_2LSB_03_02 "CAN_SCAN_INDEX_2LSB_03_02";
BA_ "GenSigVtEn" SG_ 290 CAN_DET_CONFID_AZIMUTH_03_03 "CAN_DET_CONFID_AZIMUTH_03_03";
BA_ "GenSigVtName" SG_ 290 CAN_DET_CONFID_AZIMUTH_03_03 "CAN_DET_CONFID_AZIMUTH_03_03";
BA_ "GenSigSendType" SG_ 290 CAN_DET_CONFID_AZIMUTH_03_03 0;
BA_ "GenSigCmt" SG_ 290 CAN_DET_CONFID_AZIMUTH_03_03 "CAN_DET_CONFID_AZIMUTH_03_03";
BA_ "GenSigSendType" SG_ 290 CAN_DET_SUPER_RES_TARGET_03_03 0;
BA_ "GenSigCmt" SG_ 290 CAN_DET_SUPER_RES_TARGET_03_03 "CAN_DET_SUPER_RES_TARGET_03_03";
BA_ "GenSigSendType" SG_ 290 CAN_DET_ND_TARGET_03_03 0;
BA_ "GenSigCmt" SG_ 290 CAN_DET_ND_TARGET_03_03 "CAN_DET_ND_TARGET_03_03";
BA_ "GenSigSendType" SG_ 290 CAN_DET_HOST_VEH_CLUTTER_03_03 0;
BA_ "GenSigCmt" SG_ 290 CAN_DET_HOST_VEH_CLUTTER_03_03 "CAN_DET_HOST_VEH_CLUTTER_03_03";
BA_ "GenSigSendType" SG_ 290 CAN_DET_VALID_LEVEL_03_03 0;
BA_ "GenSigCmt" SG_ 290 CAN_DET_VALID_LEVEL_03_03 "CAN_DET_VALID_LEVEL_03_03";
BA_ "GenSigSendType" SG_ 290 CAN_DET_AZIMUTH_03_03 0;
BA_ "GenSigCmt" SG_ 290 CAN_DET_AZIMUTH_03_03 "CAN_DET_AZIMUTH_03_03";
BA_ "GenSigSendType" SG_ 290 CAN_DET_RANGE_03_03 0;
BA_ "GenSigCmt" SG_ 290 CAN_DET_RANGE_03_03 "CAN_DET_RANGE_03_03";
BA_ "GenSigSendType" SG_ 290 CAN_DET_RANGE_RATE_03_03 0;
BA_ "GenSigCmt" SG_ 290 CAN_DET_RANGE_RATE_03_03 "CAN_DET_RANGE_RATE_03_03";
BA_ "GenSigSendType" SG_ 290 CAN_DET_AMPLITUDE_03_03 0;
BA_ "GenSigCmt" SG_ 290 CAN_DET_AMPLITUDE_03_03 "CAN_DET_AMPLITUDE_03_03";
BA_ "GenSigSendType" SG_ 290 CAN_SCAN_INDEX_2LSB_03_03 0;
BA_ "GenSigCmt" SG_ 290 CAN_SCAN_INDEX_2LSB_03_03 "CAN_SCAN_INDEX_2LSB_03_03";
BA_ "GenSigVtEn" SG_ 290 CAN_DET_CONFID_AZIMUTH_03_04 "CAN_DET_CONFID_AZIMUTH_03_04";
BA_ "GenSigVtName" SG_ 290 CAN_DET_CONFID_AZIMUTH_03_04 "CAN_DET_CONFID_AZIMUTH_03_04";
BA_ "GenSigSendType" SG_ 290 CAN_DET_CONFID_AZIMUTH_03_04 0;
BA_ "GenSigCmt" SG_ 290 CAN_DET_CONFID_AZIMUTH_03_04 "CAN_DET_CONFID_AZIMUTH_03_04";
BA_ "GenSigSendType" SG_ 290 CAN_DET_SUPER_RES_TARGET_03_04 0;
BA_ "GenSigCmt" SG_ 290 CAN_DET_SUPER_RES_TARGET_03_04 "CAN_DET_SUPER_RES_TARGET_03_04";
BA_ "GenSigSendType" SG_ 290 CAN_DET_ND_TARGET_03_04 0;
BA_ "GenSigCmt" SG_ 290 CAN_DET_ND_TARGET_03_04 "CAN_DET_ND_TARGET_03_04";
BA_ "GenSigSendType" SG_ 290 CAN_DET_HOST_VEH_CLUTTER_03_04 0;
BA_ "GenSigCmt" SG_ 290 CAN_DET_HOST_VEH_CLUTTER_03_04 "CAN_DET_HOST_VEH_CLUTTER_03_04";
BA_ "GenSigSendType" SG_ 290 CAN_DET_VALID_LEVEL_03_04 0;
BA_ "GenSigCmt" SG_ 290 CAN_DET_VALID_LEVEL_03_04 "CAN_DET_VALID_LEVEL_03_04";
BA_ "GenSigSendType" SG_ 290 CAN_DET_AZIMUTH_03_04 0;
BA_ "GenSigCmt" SG_ 290 CAN_DET_AZIMUTH_03_04 "CAN_DET_AZIMUTH_03_04";
BA_ "GenSigSendType" SG_ 290 CAN_DET_RANGE_03_04 0;
BA_ "GenSigCmt" SG_ 290 CAN_DET_RANGE_03_04 "CAN_DET_RANGE_03_04";
BA_ "GenSigSendType" SG_ 290 CAN_DET_RANGE_RATE_03_04 0;
BA_ "GenSigCmt" SG_ 290 CAN_DET_RANGE_RATE_03_04 "CAN_DET_RANGE_RATE_03_04";
BA_ "GenSigSendType" SG_ 290 CAN_DET_AMPLITUDE_03_04 0;
BA_ "GenSigCmt" SG_ 290 CAN_DET_AMPLITUDE_03_04 "CAN_DET_AMPLITUDE_03_04";
BA_ "GenSigSendType" SG_ 290 CAN_SCAN_INDEX_2LSB_03_04 0;
BA_ "GenSigCmt" SG_ 290 CAN_SCAN_INDEX_2LSB_03_04 "CAN_SCAN_INDEX_2LSB_03_04";
BA_ "GenSigVtEn" SG_ 290 CAN_DET_CONFID_AZIMUTH_03_05 "CAN_DET_CONFID_AZIMUTH_03_05";
BA_ "GenSigVtName" SG_ 290 CAN_DET_CONFID_AZIMUTH_03_05 "CAN_DET_CONFID_AZIMUTH_03_05";
BA_ "GenSigSendType" SG_ 290 CAN_DET_CONFID_AZIMUTH_03_05 0;
BA_ "GenSigCmt" SG_ 290 CAN_DET_CONFID_AZIMUTH_03_05 "CAN_DET_CONFID_AZIMUTH_03_05";
BA_ "GenSigSendType" SG_ 290 CAN_DET_SUPER_RES_TARGET_03_05 0;
BA_ "GenSigCmt" SG_ 290 CAN_DET_SUPER_RES_TARGET_03_05 "CAN_DET_SUPER_RES_TARGET_03_05";
BA_ "GenSigSendType" SG_ 290 CAN_DET_ND_TARGET_03_05 0;
BA_ "GenSigCmt" SG_ 290 CAN_DET_ND_TARGET_03_05 "CAN_DET_ND_TARGET_03_05";
BA_ "GenSigSendType" SG_ 290 CAN_DET_HOST_VEH_CLUTTER_03_05 0;
BA_ "GenSigCmt" SG_ 290 CAN_DET_HOST_VEH_CLUTTER_03_05 "CAN_DET_HOST_VEH_CLUTTER_03_05";
BA_ "GenSigSendType" SG_ 290 CAN_DET_VALID_LEVEL_03_05 0;
BA_ "GenSigCmt" SG_ 290 CAN_DET_VALID_LEVEL_03_05 "CAN_DET_VALID_LEVEL_03_05";
BA_ "GenSigSendType" SG_ 290 CAN_DET_AZIMUTH_03_05 0;
BA_ "GenSigCmt" SG_ 290 CAN_DET_AZIMUTH_03_05 "CAN_DET_AZIMUTH_03_05";
BA_ "GenSigSendType" SG_ 290 CAN_DET_RANGE_03_05 0;
BA_ "GenSigCmt" SG_ 290 CAN_DET_RANGE_03_05 "CAN_DET_RANGE_03_05";
BA_ "GenSigSendType" SG_ 290 CAN_DET_RANGE_RATE_03_05 0;
BA_ "GenSigCmt" SG_ 290 CAN_DET_RANGE_RATE_03_05 "CAN_DET_RANGE_RATE_03_05";
BA_ "GenSigSendType" SG_ 290 CAN_DET_AMPLITUDE_03_05 0;
BA_ "GenSigCmt" SG_ 290 CAN_DET_AMPLITUDE_03_05 "CAN_DET_AMPLITUDE_03_05";
BA_ "GenSigSendType" SG_ 290 CAN_SCAN_INDEX_2LSB_03_05 0;
BA_ "GenSigCmt" SG_ 290 CAN_SCAN_INDEX_2LSB_03_05 "CAN_SCAN_INDEX_2LSB_03_05";
BA_ "GenSigVtEn" SG_ 290 CAN_DET_CONFID_AZIMUTH_03_06 "CAN_DET_CONFID_AZIMUTH_03_06";
BA_ "GenSigVtName" SG_ 290 CAN_DET_CONFID_AZIMUTH_03_06 "CAN_DET_CONFID_AZIMUTH_03_06";
BA_ "GenSigSendType" SG_ 290 CAN_DET_CONFID_AZIMUTH_03_06 0;
BA_ "GenSigCmt" SG_ 290 CAN_DET_CONFID_AZIMUTH_03_06 "CAN_DET_CONFID_AZIMUTH_03_06";
BA_ "GenSigSendType" SG_ 290 CAN_DET_SUPER_RES_TARGET_03_06 0;
BA_ "GenSigCmt" SG_ 290 CAN_DET_SUPER_RES_TARGET_03_06 "CAN_DET_SUPER_RES_TARGET_03_06";
BA_ "GenSigSendType" SG_ 290 CAN_DET_ND_TARGET_03_06 0;
BA_ "GenSigCmt" SG_ 290 CAN_DET_ND_TARGET_03_06 "CAN_DET_ND_TARGET_03_06";
BA_ "GenSigSendType" SG_ 290 CAN_DET_HOST_VEH_CLUTTER_03_06 0;
BA_ "GenSigCmt" SG_ 290 CAN_DET_HOST_VEH_CLUTTER_03_06 "CAN_DET_HOST_VEH_CLUTTER_03_06";
BA_ "GenSigSendType" SG_ 290 CAN_DET_VALID_LEVEL_03_06 0;
BA_ "GenSigCmt" SG_ 290 CAN_DET_VALID_LEVEL_03_06 "CAN_DET_VALID_LEVEL_03_06";
BA_ "GenSigSendType" SG_ 290 CAN_DET_AZIMUTH_03_06 0;
BA_ "GenSigCmt" SG_ 290 CAN_DET_AZIMUTH_03_06 "CAN_DET_AZIMUTH_03_06";
BA_ "GenSigSendType" SG_ 290 CAN_DET_RANGE_03_06 0;
BA_ "GenSigCmt" SG_ 290 CAN_DET_RANGE_03_06 "CAN_DET_RANGE_03_06";
BA_ "GenSigSendType" SG_ 290 CAN_DET_RANGE_RATE_03_06 0;
BA_ "GenSigCmt" SG_ 290 CAN_DET_RANGE_RATE_03_06 "CAN_DET_RANGE_RATE_03_06";
BA_ "GenSigSendType" SG_ 290 CAN_DET_AMPLITUDE_03_06 0;
BA_ "GenSigCmt" SG_ 290 CAN_DET_AMPLITUDE_03_06 "CAN_DET_AMPLITUDE_03_06";
BA_ "GenSigSendType" SG_ 290 CAN_SCAN_INDEX_2LSB_03_06 0;
BA_ "GenSigCmt" SG_ 290 CAN_SCAN_INDEX_2LSB_03_06 "CAN_SCAN_INDEX_2LSB_03_06";
BA_ "GenMsgSendType" BO_ 289 1;
BA_ "GenSigVtEn" SG_ 289 CAN_DET_CONFID_AZIMUTH_02_01 "CAN_DET_CONFID_AZIMUTH_02_01";
BA_ "GenSigVtName" SG_ 289 CAN_DET_CONFID_AZIMUTH_02_01 "CAN_DET_CONFID_AZIMUTH_02_01";
BA_ "GenSigSendType" SG_ 289 CAN_DET_CONFID_AZIMUTH_02_01 0;
BA_ "GenSigCmt" SG_ 289 CAN_DET_CONFID_AZIMUTH_02_01 "CAN_DET_CONFID_AZIMUTH_02_01";
BA_ "GenSigSendType" SG_ 289 CAN_DET_SUPER_RES_TARGET_02_01 0;
BA_ "GenSigCmt" SG_ 289 CAN_DET_SUPER_RES_TARGET_02_01 "CAN_DET_SUPER_RES_TARGET_02_01";
BA_ "GenSigSendType" SG_ 289 CAN_DET_ND_TARGET_02_01 0;
BA_ "GenSigCmt" SG_ 289 CAN_DET_ND_TARGET_02_01 "CAN_DET_ND_TARGET_02_01";
BA_ "GenSigSendType" SG_ 289 CAN_DET_HOST_VEH_CLUTTER_02_01 0;
BA_ "GenSigCmt" SG_ 289 CAN_DET_HOST_VEH_CLUTTER_02_01 "CAN_DET_HOST_VEH_CLUTTER_02_01";
BA_ "GenSigSendType" SG_ 289 CAN_DET_VALID_LEVEL_02_01 0;
BA_ "GenSigCmt" SG_ 289 CAN_DET_VALID_LEVEL_02_01 "CAN_DET_VALID_LEVEL_02_01";
BA_ "GenSigSendType" SG_ 289 CAN_DET_AZIMUTH_02_01 0;
BA_ "GenSigCmt" SG_ 289 CAN_DET_AZIMUTH_02_01 "CAN_DET_AZIMUTH_02_01";
BA_ "GenSigSendType" SG_ 289 CAN_DET_RANGE_02_01 0;
BA_ "GenSigCmt" SG_ 289 CAN_DET_RANGE_02_01 "CAN_DET_RANGE_02_01";
BA_ "GenSigSendType" SG_ 289 CAN_DET_RANGE_RATE_02_01 0;
BA_ "GenSigCmt" SG_ 289 CAN_DET_RANGE_RATE_02_01 "CAN_DET_RANGE_RATE_02_01";
BA_ "GenSigSendType" SG_ 289 CAN_DET_AMPLITUDE_02_01 0;
BA_ "GenSigCmt" SG_ 289 CAN_DET_AMPLITUDE_02_01 "CAN_DET_AMPLITUDE_02_01";
BA_ "GenSigSendType" SG_ 289 CAN_SCAN_INDEX_2LSB_02_01 0;
BA_ "GenSigCmt" SG_ 289 CAN_SCAN_INDEX_2LSB_02_01 "CAN_SCAN_INDEX_2LSB_02_01";
BA_ "GenSigVtEn" SG_ 289 CAN_DET_CONFID_AZIMUTH_02_02 "CAN_DET_CONFID_AZIMUTH_02_02";
BA_ "GenSigVtName" SG_ 289 CAN_DET_CONFID_AZIMUTH_02_02 "CAN_DET_CONFID_AZIMUTH_02_02";
BA_ "GenSigSendType" SG_ 289 CAN_DET_CONFID_AZIMUTH_02_02 0;
BA_ "GenSigCmt" SG_ 289 CAN_DET_CONFID_AZIMUTH_02_02 "CAN_DET_CONFID_AZIMUTH_02_02";
BA_ "GenSigSendType" SG_ 289 CAN_DET_SUPER_RES_TARGET_02_02 0;
BA_ "GenSigCmt" SG_ 289 CAN_DET_SUPER_RES_TARGET_02_02 "CAN_DET_SUPER_RES_TARGET_02_02";
BA_ "GenSigSendType" SG_ 289 CAN_DET_ND_TARGET_02_02 0;
BA_ "GenSigCmt" SG_ 289 CAN_DET_ND_TARGET_02_02 "CAN_DET_ND_TARGET_02_02";
BA_ "GenSigSendType" SG_ 289 CAN_DET_HOST_VEH_CLUTTER_02_02 0;
BA_ "GenSigCmt" SG_ 289 CAN_DET_HOST_VEH_CLUTTER_02_02 "CAN_DET_HOST_VEH_CLUTTER_02_02";
BA_ "GenSigSendType" SG_ 289 CAN_DET_VALID_LEVEL_02_02 0;
BA_ "GenSigCmt" SG_ 289 CAN_DET_VALID_LEVEL_02_02 "CAN_DET_VALID_LEVEL_02_02";
BA_ "GenSigSendType" SG_ 289 CAN_DET_AZIMUTH_02_02 0;
BA_ "GenSigCmt" SG_ 289 CAN_DET_AZIMUTH_02_02 "CAN_DET_AZIMUTH_02_02";
BA_ "GenSigSendType" SG_ 289 CAN_DET_RANGE_02_02 0;
BA_ "GenSigCmt" SG_ 289 CAN_DET_RANGE_02_02 "CAN_DET_RANGE_02_02";
BA_ "GenSigSendType" SG_ 289 CAN_DET_RANGE_RATE_02_02 0;
BA_ "GenSigCmt" SG_ 289 CAN_DET_RANGE_RATE_02_02 "CAN_DET_RANGE_RATE_02_02";
BA_ "GenSigSendType" SG_ 289 CAN_DET_AMPLITUDE_02_02 0;
BA_ "GenSigCmt" SG_ 289 CAN_DET_AMPLITUDE_02_02 "CAN_DET_AMPLITUDE_02_02";
BA_ "GenSigSendType" SG_ 289 CAN_SCAN_INDEX_2LSB_02_02 0;
BA_ "GenSigCmt" SG_ 289 CAN_SCAN_INDEX_2LSB_02_02 "CAN_SCAN_INDEX_2LSB_02_02";
BA_ "GenSigVtEn" SG_ 289 CAN_DET_CONFID_AZIMUTH_02_03 "CAN_DET_CONFID_AZIMUTH_02_03";
BA_ "GenSigVtName" SG_ 289 CAN_DET_CONFID_AZIMUTH_02_03 "CAN_DET_CONFID_AZIMUTH_02_03";
BA_ "GenSigSendType" SG_ 289 CAN_DET_CONFID_AZIMUTH_02_03 0;
BA_ "GenSigCmt" SG_ 289 CAN_DET_CONFID_AZIMUTH_02_03 "CAN_DET_CONFID_AZIMUTH_02_03";
BA_ "GenSigSendType" SG_ 289 CAN_DET_SUPER_RES_TARGET_02_03 0;
BA_ "GenSigCmt" SG_ 289 CAN_DET_SUPER_RES_TARGET_02_03 "CAN_DET_SUPER_RES_TARGET_02_03";
BA_ "GenSigSendType" SG_ 289 CAN_DET_ND_TARGET_02_03 0;
BA_ "GenSigCmt" SG_ 289 CAN_DET_ND_TARGET_02_03 "CAN_DET_ND_TARGET_02_03";
BA_ "GenSigSendType" SG_ 289 CAN_DET_HOST_VEH_CLUTTER_02_03 0;
BA_ "GenSigCmt" SG_ 289 CAN_DET_HOST_VEH_CLUTTER_02_03 "CAN_DET_HOST_VEH_CLUTTER_02_03";
BA_ "GenSigSendType" SG_ 289 CAN_DET_VALID_LEVEL_02_03 0;
BA_ "GenSigCmt" SG_ 289 CAN_DET_VALID_LEVEL_02_03 "CAN_DET_VALID_LEVEL_02_03";
BA_ "GenSigSendType" SG_ 289 CAN_DET_AZIMUTH_02_03 0;
BA_ "GenSigCmt" SG_ 289 CAN_DET_AZIMUTH_02_03 "CAN_DET_AZIMUTH_02_03";
BA_ "GenSigSendType" SG_ 289 CAN_DET_RANGE_02_03 0;
BA_ "GenSigCmt" SG_ 289 CAN_DET_RANGE_02_03 "CAN_DET_RANGE_02_03";
BA_ "GenSigSendType" SG_ 289 CAN_DET_RANGE_RATE_02_03 0;
BA_ "GenSigCmt" SG_ 289 CAN_DET_RANGE_RATE_02_03 "CAN_DET_RANGE_RATE_02_03";
BA_ "GenSigSendType" SG_ 289 CAN_DET_AMPLITUDE_02_03 0;
BA_ "GenSigCmt" SG_ 289 CAN_DET_AMPLITUDE_02_03 "CAN_DET_AMPLITUDE_02_03";
BA_ "GenSigSendType" SG_ 289 CAN_SCAN_INDEX_2LSB_02_03 0;
BA_ "GenSigCmt" SG_ 289 CAN_SCAN_INDEX_2LSB_02_03 "CAN_SCAN_INDEX_2LSB_02_03";
BA_ "GenSigVtEn" SG_ 289 CAN_DET_CONFID_AZIMUTH_02_04 "CAN_DET_CONFID_AZIMUTH_02_04";
BA_ "GenSigVtName" SG_ 289 CAN_DET_CONFID_AZIMUTH_02_04 "CAN_DET_CONFID_AZIMUTH_02_04";
BA_ "GenSigSendType" SG_ 289 CAN_DET_CONFID_AZIMUTH_02_04 0;
BA_ "GenSigCmt" SG_ 289 CAN_DET_CONFID_AZIMUTH_02_04 "CAN_DET_CONFID_AZIMUTH_02_04";
BA_ "GenSigSendType" SG_ 289 CAN_DET_SUPER_RES_TARGET_02_04 0;
BA_ "GenSigCmt" SG_ 289 CAN_DET_SUPER_RES_TARGET_02_04 "CAN_DET_SUPER_RES_TARGET_02_04";
BA_ "GenSigSendType" SG_ 289 CAN_DET_ND_TARGET_02_04 0;
BA_ "GenSigCmt" SG_ 289 CAN_DET_ND_TARGET_02_04 "CAN_DET_ND_TARGET_02_04";
BA_ "GenSigSendType" SG_ 289 CAN_DET_HOST_VEH_CLUTTER_02_04 0;
BA_ "GenSigCmt" SG_ 289 CAN_DET_HOST_VEH_CLUTTER_02_04 "CAN_DET_HOST_VEH_CLUTTER_02_04";
BA_ "GenSigSendType" SG_ 289 CAN_DET_VALID_LEVEL_02_04 0;
BA_ "GenSigCmt" SG_ 289 CAN_DET_VALID_LEVEL_02_04 "CAN_DET_VALID_LEVEL_02_04";
BA_ "GenSigSendType" SG_ 289 CAN_DET_AZIMUTH_02_04 0;
BA_ "GenSigCmt" SG_ 289 CAN_DET_AZIMUTH_02_04 "CAN_DET_AZIMUTH_02_04";
BA_ "GenSigSendType" SG_ 289 CAN_DET_RANGE_02_04 0;
BA_ "GenSigCmt" SG_ 289 CAN_DET_RANGE_02_04 "CAN_DET_RANGE_02_04";
BA_ "GenSigSendType" SG_ 289 CAN_DET_RANGE_RATE_02_04 0;
BA_ "GenSigCmt" SG_ 289 CAN_DET_RANGE_RATE_02_04 "CAN_DET_RANGE_RATE_02_04";
BA_ "GenSigSendType" SG_ 289 CAN_DET_AMPLITUDE_02_04 0;
BA_ "GenSigCmt" SG_ 289 CAN_DET_AMPLITUDE_02_04 "CAN_DET_AMPLITUDE_02_04";
BA_ "GenSigSendType" SG_ 289 CAN_SCAN_INDEX_2LSB_02_04 0;
BA_ "GenSigCmt" SG_ 289 CAN_SCAN_INDEX_2LSB_02_04 "CAN_SCAN_INDEX_2LSB_02_04";
BA_ "GenSigVtEn" SG_ 289 CAN_DET_CONFID_AZIMUTH_02_05 "CAN_DET_CONFID_AZIMUTH_02_05";
BA_ "GenSigVtName" SG_ 289 CAN_DET_CONFID_AZIMUTH_02_05 "CAN_DET_CONFID_AZIMUTH_02_05";
BA_ "GenSigSendType" SG_ 289 CAN_DET_CONFID_AZIMUTH_02_05 0;
BA_ "GenSigCmt" SG_ 289 CAN_DET_CONFID_AZIMUTH_02_05 "CAN_DET_CONFID_AZIMUTH_02_05";
BA_ "GenSigSendType" SG_ 289 CAN_DET_SUPER_RES_TARGET_02_05 0;
BA_ "GenSigCmt" SG_ 289 CAN_DET_SUPER_RES_TARGET_02_05 "CAN_DET_SUPER_RES_TARGET_02_05";
BA_ "GenSigSendType" SG_ 289 CAN_DET_ND_TARGET_02_05 0;
BA_ "GenSigCmt" SG_ 289 CAN_DET_ND_TARGET_02_05 "CAN_DET_ND_TARGET_02_05";
BA_ "GenSigSendType" SG_ 289 CAN_DET_HOST_VEH_CLUTTER_02_05 0;
BA_ "GenSigCmt" SG_ 289 CAN_DET_HOST_VEH_CLUTTER_02_05 "CAN_DET_HOST_VEH_CLUTTER_02_05";
BA_ "GenSigSendType" SG_ 289 CAN_DET_VALID_LEVEL_02_05 0;
BA_ "GenSigCmt" SG_ 289 CAN_DET_VALID_LEVEL_02_05 "CAN_DET_VALID_LEVEL_02_05";
BA_ "GenSigSendType" SG_ 289 CAN_DET_AZIMUTH_02_05 0;
BA_ "GenSigCmt" SG_ 289 CAN_DET_AZIMUTH_02_05 "CAN_DET_AZIMUTH_02_05";
BA_ "GenSigSendType" SG_ 289 CAN_DET_RANGE_02_05 0;
BA_ "GenSigCmt" SG_ 289 CAN_DET_RANGE_02_05 "CAN_DET_RANGE_02_05";
BA_ "GenSigSendType" SG_ 289 CAN_DET_RANGE_RATE_02_05 0;
BA_ "GenSigCmt" SG_ 289 CAN_DET_RANGE_RATE_02_05 "CAN_DET_RANGE_RATE_02_05";
BA_ "GenSigSendType" SG_ 289 CAN_DET_AMPLITUDE_02_05 0;
BA_ "GenSigCmt" SG_ 289 CAN_DET_AMPLITUDE_02_05 "CAN_DET_AMPLITUDE_02_05";
BA_ "GenSigSendType" SG_ 289 CAN_SCAN_INDEX_2LSB_02_05 0;
BA_ "GenSigCmt" SG_ 289 CAN_SCAN_INDEX_2LSB_02_05 "CAN_SCAN_INDEX_2LSB_02_05";
BA_ "GenSigVtEn" SG_ 289 CAN_DET_CONFID_AZIMUTH_02_06 "CAN_DET_CONFID_AZIMUTH_02_06";
BA_ "GenSigVtName" SG_ 289 CAN_DET_CONFID_AZIMUTH_02_06 "CAN_DET_CONFID_AZIMUTH_02_06";
BA_ "GenSigSendType" SG_ 289 CAN_DET_CONFID_AZIMUTH_02_06 0;
BA_ "GenSigCmt" SG_ 289 CAN_DET_CONFID_AZIMUTH_02_06 "CAN_DET_CONFID_AZIMUTH_02_06";
BA_ "GenSigSendType" SG_ 289 CAN_DET_SUPER_RES_TARGET_02_06 0;
BA_ "GenSigCmt" SG_ 289 CAN_DET_SUPER_RES_TARGET_02_06 "CAN_DET_SUPER_RES_TARGET_02_06";
BA_ "GenSigSendType" SG_ 289 CAN_DET_ND_TARGET_02_06 0;
BA_ "GenSigCmt" SG_ 289 CAN_DET_ND_TARGET_02_06 "CAN_DET_ND_TARGET_02_06";
BA_ "GenSigSendType" SG_ 289 CAN_DET_HOST_VEH_CLUTTER_02_06 0;
BA_ "GenSigCmt" SG_ 289 CAN_DET_HOST_VEH_CLUTTER_02_06 "CAN_DET_HOST_VEH_CLUTTER_02_06";
BA_ "GenSigSendType" SG_ 289 CAN_DET_VALID_LEVEL_02_06 0;
BA_ "GenSigCmt" SG_ 289 CAN_DET_VALID_LEVEL_02_06 "CAN_DET_VALID_LEVEL_02_06";
BA_ "GenSigSendType" SG_ 289 CAN_DET_AZIMUTH_02_06 0;
BA_ "GenSigCmt" SG_ 289 CAN_DET_AZIMUTH_02_06 "CAN_DET_AZIMUTH_02_06";
BA_ "GenSigSendType" SG_ 289 CAN_DET_RANGE_02_06 0;
BA_ "GenSigCmt" SG_ 289 CAN_DET_RANGE_02_06 "CAN_DET_RANGE_02_06";
BA_ "GenSigSendType" SG_ 289 CAN_DET_RANGE_RATE_02_06 0;
BA_ "GenSigCmt" SG_ 289 CAN_DET_RANGE_RATE_02_06 "CAN_DET_RANGE_RATE_02_06";
BA_ "GenSigSendType" SG_ 289 CAN_DET_AMPLITUDE_02_06 0;
BA_ "GenSigCmt" SG_ 289 CAN_DET_AMPLITUDE_02_06 "CAN_DET_AMPLITUDE_02_06";
BA_ "GenSigSendType" SG_ 289 CAN_SCAN_INDEX_2LSB_02_06 0;
BA_ "GenSigCmt" SG_ 289 CAN_SCAN_INDEX_2LSB_02_06 "CAN_SCAN_INDEX_2LSB_02_06";
BA_ "GenMsgSendType" BO_ 256 1;
BA_ "GenSigCmt" SG_ 256 CAN_PCAN_MINOR_MRR "CAN_PCAN_MINOR_MRR";
BA_ "GenSigSendType" SG_ 256 CAN_PCAN_MINOR_MRR 0;
BA_ "GenSigCmt" SG_ 256 CAN_PCAN_MAJOR_MRR "CAN_PCAN_MAJOR_MRR";
BA_ "GenSigSendType" SG_ 256 CAN_PCAN_MAJOR_MRR 0;
BA_ "GenMsgCycleTime" BO_ 257 30;
BA_ "GenMsgSendType" BO_ 257 0;
BA_ "GenSigCmt" SG_ 257 CAN_INTERFERENCE_TYPE "CAN_INTERFERENCE_TYPE";
BA_ "GenSigVtEn" SG_ 257 CAN_INTERFERENCE_TYPE "CAN_INTERFERENCE_TYPE";
BA_ "GenSigVtName" SG_ 257 CAN_INTERFERENCE_TYPE "CAN_INTERFERENCE_TYPE";
BA_ "GenSigVtName" SG_ 257 CAN_RECOMMEND_UNCONVERGE "CAN_RECOMMEND_UNCONVERGE";
BA_ "GenSigVtEn" SG_ 257 CAN_RECOMMEND_UNCONVERGE "CAN_RECOMMEND_UNCONVERGE";
BA_ "GenSigCmt" SG_ 257 CAN_RECOMMEND_UNCONVERGE "CAN_RECOMMEND_UNCONVERGE";
BA_ "GenSigSendType" SG_ 257 CAN_BLOCKAGE_SIDELOBE_FILTER_VAL 0;
BA_ "GenSigCmt" SG_ 257 CAN_BLOCKAGE_SIDELOBE_FILTER_VAL "CAN_BLOCKAGE_SIDELOBE_FILTER_VAL";
BA_ "GenSigVtEn" SG_ 257 CAN_BLOCKAGE_SIDELOBE_FILTER_VAL "CAN_BLOCKAGE_SIDELOBE_FILTER_VAL";
BA_ "GenSigVtName" SG_ 257 CAN_BLOCKAGE_SIDELOBE_FILTER_VAL "CAN_BLOCKAGE_SIDELOBE_FILTER_VAL";
BA_ "GenSigCmt" SG_ 257 CAN_RADAR_ALIGN_INCOMPLETE "CAN_RADAR_ALIGN_INCOMPLETE";
BA_ "GenSigVtEn" SG_ 257 CAN_RADAR_ALIGN_INCOMPLETE "CAN_RADAR_ALIGN_INCOMPLETE";
BA_ "GenSigVtName" SG_ 257 CAN_RADAR_ALIGN_INCOMPLETE "CAN_RADAR_ALIGN_INCOMPLETE";
BA_ "GenSigCmt" SG_ 257 CAN_BLOCKAGE_SIDELOBE "CAN_BLOCKAGE_SIDELOBE";
BA_ "GenSigVtEn" SG_ 257 CAN_BLOCKAGE_SIDELOBE "CAN_BLOCKAGE_SIDELOBE";
BA_ "GenSigVtName" SG_ 257 CAN_BLOCKAGE_SIDELOBE "CAN_BLOCKAGE_SIDELOBE";
BA_ "GenSigSendType" SG_ 257 CAN_BLOCKAGE_SIDELOBE 0;
BA_ "GenSigCmt" SG_ 257 CAN_BLOCKAGE_MNR "CAN_BLOCKAGE_MNR";
BA_ "GenSigVtEn" SG_ 257 CAN_BLOCKAGE_MNR "CAN_BLOCKAGE_MNR";
BA_ "GenSigVtName" SG_ 257 CAN_BLOCKAGE_MNR "CAN_BLOCKAGE_MNR";
BA_ "GenSigSendType" SG_ 257 CAN_BLOCKAGE_MNR 0;
BA_ "GenSigCmt" SG_ 257 CAN_RADAR_EXT_COND_NOK "CAN_RADAR_EXT_COND_NOK";
BA_ "GenSigVtEn" SG_ 257 CAN_RADAR_EXT_COND_NOK "CAN_RADAR_EXT_COND_NOK";
BA_ "GenSigVtName" SG_ 257 CAN_RADAR_EXT_COND_NOK "CAN_RADAR_EXT_COND_NOK";
BA_ "GenSigSendType" SG_ 257 CAN_RADAR_EXT_COND_NOK 0;
BA_ "GenSigCmt" SG_ 257 CAN_RADAR_ALIGN_OUT_RANGE "CAN_RADAR_ALIGN_OUT_RANGE";
BA_ "GenSigVtEn" SG_ 257 CAN_RADAR_ALIGN_OUT_RANGE "CAN_RADAR_ALIGN_OUT_RANGE";
BA_ "GenSigVtName" SG_ 257 CAN_RADAR_ALIGN_OUT_RANGE "CAN_RADAR_ALIGN_OUT_RANGE";
BA_ "GenSigSendType" SG_ 257 CAN_RADAR_ALIGN_OUT_RANGE 0;
BA_ "GenSigCmt" SG_ 257 CAN_RADAR_ALIGN_NOT_START "CAN_RADAR_ALIGN_NOT_START";
BA_ "GenSigVtEn" SG_ 257 CAN_RADAR_ALIGN_NOT_START "CAN_RADAR_ALIGN_NOT_START";
BA_ "GenSigVtName" SG_ 257 CAN_RADAR_ALIGN_NOT_START "CAN_RADAR_ALIGN_NOT_START";
BA_ "GenSigSendType" SG_ 257 CAN_RADAR_ALIGN_NOT_START 0;
BA_ "GenSigCmt" SG_ 257 CAN_RADAR_OVERHEAT_ERROR "CAN_RADAR_OVERHEAT_ERROR";
BA_ "GenSigVtEn" SG_ 257 CAN_RADAR_OVERHEAT_ERROR "CAN_RADAR_OVERHEAT_ERROR";
BA_ "GenSigVtName" SG_ 257 CAN_RADAR_OVERHEAT_ERROR "CAN_RADAR_OVERHEAT_ERROR";
BA_ "GenSigSendType" SG_ 257 CAN_RADAR_OVERHEAT_ERROR 0;
BA_ "GenSigCmt" SG_ 257 CAN_RADAR_NOT_OP "CAN_RADAR_NOT_OP";
BA_ "GenSigVtEn" SG_ 257 CAN_RADAR_NOT_OP "CAN_RADAR_NOT_OP";
BA_ "GenSigVtName" SG_ 257 CAN_RADAR_NOT_OP "CAN_RADAR_NOT_OP";
BA_ "GenSigSendType" SG_ 257 CAN_RADAR_NOT_OP 0;
BA_ "GenSigCmt" SG_ 257 CAN_XCVR_OPERATIONAL "CAN_XCVR_OPERATIONAL";
BA_ "GenSigVtEn" SG_ 257 CAN_XCVR_OPERATIONAL "CAN_XCVR_OPERATIONAL";
BA_ "GenSigVtName" SG_ 257 CAN_XCVR_OPERATIONAL "CAN_XCVR_OPERATIONAL";
BA_ "GenSigSendType" SG_ 257 CAN_XCVR_OPERATIONAL 0;
BA_ "GenMsgSendType" BO_ 288 1;
BA_ "GenSigVtEn" SG_ 288 CAN_DET_CONFID_AZIMUTH_01_01 "CAN_DET_CONFID_AZIMUTH_01_01";
BA_ "GenSigVtName" SG_ 288 CAN_DET_CONFID_AZIMUTH_01_01 "CAN_DET_CONFID_AZIMUTH_01_01";
BA_ "GenSigSendType" SG_ 288 CAN_DET_CONFID_AZIMUTH_01_01 0;
BA_ "GenSigCmt" SG_ 288 CAN_DET_CONFID_AZIMUTH_01_01 "CAN_DET_CONFID_AZIMUTH_01_01";
BA_ "GenSigSendType" SG_ 288 CAN_DET_SUPER_RES_TARGET_01_01 0;
BA_ "GenSigCmt" SG_ 288 CAN_DET_SUPER_RES_TARGET_01_01 "CAN_DET_SUPER_RES_TARGET_01_01";
BA_ "GenSigSendType" SG_ 288 CAN_DET_ND_TARGET_01_01 0;
BA_ "GenSigCmt" SG_ 288 CAN_DET_ND_TARGET_01_01 "CAN_DET_ND_TARGET_01_01";
BA_ "GenSigSendType" SG_ 288 CAN_DET_HOST_VEH_CLUTTER_01_01 0;
BA_ "GenSigCmt" SG_ 288 CAN_DET_HOST_VEH_CLUTTER_01_01 "CAN_DET_HOST_VEH_CLUTTER_01_01";
BA_ "GenSigSendType" SG_ 288 CAN_DET_VALID_LEVEL_01_01 0;
BA_ "GenSigCmt" SG_ 288 CAN_DET_VALID_LEVEL_01_01 "CAN_DET_VALID_LEVEL_01_01";
BA_ "GenSigSendType" SG_ 288 CAN_DET_AZIMUTH_01_01 0;
BA_ "GenSigCmt" SG_ 288 CAN_DET_AZIMUTH_01_01 "CAN_DET_AZIMUTH_01_01";
BA_ "GenSigSendType" SG_ 288 CAN_DET_RANGE_01_01 0;
BA_ "GenSigCmt" SG_ 288 CAN_DET_RANGE_01_01 "CAN_DET_RANGE_01_01";
BA_ "GenSigSendType" SG_ 288 CAN_DET_RANGE_RATE_01_01 0;
BA_ "GenSigCmt" SG_ 288 CAN_DET_RANGE_RATE_01_01 "CAN_DET_RANGE_RATE_01_01";
BA_ "GenSigSendType" SG_ 288 CAN_DET_AMPLITUDE_01_01 0;
BA_ "GenSigCmt" SG_ 288 CAN_DET_AMPLITUDE_01_01 "CAN_DET_AMPLITUDE_01_01";
BA_ "GenSigSendType" SG_ 288 CAN_SCAN_INDEX_2LSB_01_01 0;
BA_ "GenSigCmt" SG_ 288 CAN_SCAN_INDEX_2LSB_01_01 "CAN_SCAN_INDEX_2LSB_01_01";
BA_ "GenSigVtEn" SG_ 288 CAN_DET_CONFID_AZIMUTH_01_02 "CAN_DET_CONFID_AZIMUTH_01_02";
BA_ "GenSigVtName" SG_ 288 CAN_DET_CONFID_AZIMUTH_01_02 "CAN_DET_CONFID_AZIMUTH_01_02";
BA_ "GenSigSendType" SG_ 288 CAN_DET_CONFID_AZIMUTH_01_02 0;
BA_ "GenSigCmt" SG_ 288 CAN_DET_CONFID_AZIMUTH_01_02 "CAN_DET_CONFID_AZIMUTH_01_02";
BA_ "GenSigSendType" SG_ 288 CAN_DET_SUPER_RES_TARGET_01_02 0;
BA_ "GenSigCmt" SG_ 288 CAN_DET_SUPER_RES_TARGET_01_02 "CAN_DET_SUPER_RES_TARGET_01_02";
BA_ "GenSigSendType" SG_ 288 CAN_DET_ND_TARGET_01_02 0;
BA_ "GenSigCmt" SG_ 288 CAN_DET_ND_TARGET_01_02 "CAN_DET_ND_TARGET_01_02";
BA_ "GenSigSendType" SG_ 288 CAN_DET_HOST_VEH_CLUTTER_01_02 0;
BA_ "GenSigCmt" SG_ 288 CAN_DET_HOST_VEH_CLUTTER_01_02 "CAN_DET_HOST_VEH_CLUTTER_01_02";
BA_ "GenSigSendType" SG_ 288 CAN_DET_VALID_LEVEL_01_02 0;
BA_ "GenSigCmt" SG_ 288 CAN_DET_VALID_LEVEL_01_02 "CAN_DET_VALID_LEVEL_01_02";
BA_ "GenSigSendType" SG_ 288 CAN_DET_AZIMUTH_01_02 0;
BA_ "GenSigCmt" SG_ 288 CAN_DET_AZIMUTH_01_02 "CAN_DET_AZIMUTH_01_02";
BA_ "GenSigSendType" SG_ 288 CAN_DET_RANGE_01_02 0;
BA_ "GenSigCmt" SG_ 288 CAN_DET_RANGE_01_02 "CAN_DET_RANGE_01_02";
BA_ "GenSigSendType" SG_ 288 CAN_DET_RANGE_RATE_01_02 0;
BA_ "GenSigCmt" SG_ 288 CAN_DET_RANGE_RATE_01_02 "CAN_DET_RANGE_RATE_01_02";
BA_ "GenSigSendType" SG_ 288 CAN_DET_AMPLITUDE_01_02 0;
BA_ "GenSigCmt" SG_ 288 CAN_DET_AMPLITUDE_01_02 "CAN_DET_AMPLITUDE_01_02";
BA_ "GenSigSendType" SG_ 288 CAN_SCAN_INDEX_2LSB_01_02 0;
BA_ "GenSigCmt" SG_ 288 CAN_SCAN_INDEX_2LSB_01_02 "CAN_SCAN_INDEX_2LSB_01_02";
BA_ "GenSigVtEn" SG_ 288 CAN_DET_CONFID_AZIMUTH_01_03 "CAN_DET_CONFID_AZIMUTH_01_03";
BA_ "GenSigVtName" SG_ 288 CAN_DET_CONFID_AZIMUTH_01_03 "CAN_DET_CONFID_AZIMUTH_01_03";
BA_ "GenSigSendType" SG_ 288 CAN_DET_CONFID_AZIMUTH_01_03 0;
BA_ "GenSigCmt" SG_ 288 CAN_DET_CONFID_AZIMUTH_01_03 "CAN_DET_CONFID_AZIMUTH_01_03";
BA_ "GenSigSendType" SG_ 288 CAN_DET_SUPER_RES_TARGET_01_03 0;
BA_ "GenSigCmt" SG_ 288 CAN_DET_SUPER_RES_TARGET_01_03 "CAN_DET_SUPER_RES_TARGET_01_03";
BA_ "GenSigSendType" SG_ 288 CAN_DET_ND_TARGET_01_03 0;
BA_ "GenSigCmt" SG_ 288 CAN_DET_ND_TARGET_01_03 "CAN_DET_ND_TARGET_01_03";
BA_ "GenSigSendType" SG_ 288 CAN_DET_HOST_VEH_CLUTTER_01_03 0;
BA_ "GenSigCmt" SG_ 288 CAN_DET_HOST_VEH_CLUTTER_01_03 "CAN_DET_HOST_VEH_CLUTTER_01_03";
BA_ "GenSigSendType" SG_ 288 CAN_DET_VALID_LEVEL_01_03 0;
BA_ "GenSigCmt" SG_ 288 CAN_DET_VALID_LEVEL_01_03 "CAN_DET_VALID_LEVEL_01_03";
BA_ "GenSigSendType" SG_ 288 CAN_DET_AZIMUTH_01_03 0;
BA_ "GenSigCmt" SG_ 288 CAN_DET_AZIMUTH_01_03 "CAN_DET_AZIMUTH_01_03";
BA_ "GenSigSendType" SG_ 288 CAN_DET_RANGE_01_03 0;
BA_ "GenSigCmt" SG_ 288 CAN_DET_RANGE_01_03 "CAN_DET_RANGE_01_03";
BA_ "GenSigSendType" SG_ 288 CAN_DET_RANGE_RATE_01_03 0;
BA_ "GenSigCmt" SG_ 288 CAN_DET_RANGE_RATE_01_03 "CAN_DET_RANGE_RATE_01_03";
BA_ "GenSigSendType" SG_ 288 CAN_DET_AMPLITUDE_01_03 0;
BA_ "GenSigCmt" SG_ 288 CAN_DET_AMPLITUDE_01_03 "CAN_DET_AMPLITUDE_01_03";
BA_ "GenSigSendType" SG_ 288 CAN_SCAN_INDEX_2LSB_01_03 0;
BA_ "GenSigCmt" SG_ 288 CAN_SCAN_INDEX_2LSB_01_03 "CAN_SCAN_INDEX_2LSB_01_03";
BA_ "GenSigVtEn" SG_ 288 CAN_DET_CONFID_AZIMUTH_01_04 "CAN_DET_CONFID_AZIMUTH_01_04";
BA_ "GenSigVtName" SG_ 288 CAN_DET_CONFID_AZIMUTH_01_04 "CAN_DET_CONFID_AZIMUTH_01_04";
BA_ "GenSigSendType" SG_ 288 CAN_DET_CONFID_AZIMUTH_01_04 0;
BA_ "GenSigCmt" SG_ 288 CAN_DET_CONFID_AZIMUTH_01_04 "CAN_DET_CONFID_AZIMUTH_01_04";
BA_ "GenSigSendType" SG_ 288 CAN_DET_SUPER_RES_TARGET_01_04 0;
BA_ "GenSigCmt" SG_ 288 CAN_DET_SUPER_RES_TARGET_01_04 "CAN_DET_SUPER_RES_TARGET_01_04";
BA_ "GenSigSendType" SG_ 288 CAN_DET_ND_TARGET_01_04 0;
BA_ "GenSigCmt" SG_ 288 CAN_DET_ND_TARGET_01_04 "CAN_DET_ND_TARGET_01_04";
BA_ "GenSigSendType" SG_ 288 CAN_DET_HOST_VEH_CLUTTER_01_04 0;
BA_ "GenSigCmt" SG_ 288 CAN_DET_HOST_VEH_CLUTTER_01_04 "CAN_DET_HOST_VEH_CLUTTER_01_04";
BA_ "GenSigSendType" SG_ 288 CAN_DET_VALID_LEVEL_01_04 0;
BA_ "GenSigCmt" SG_ 288 CAN_DET_VALID_LEVEL_01_04 "CAN_DET_VALID_LEVEL_01_04";
BA_ "GenSigSendType" SG_ 288 CAN_DET_AZIMUTH_01_04 0;
BA_ "GenSigCmt" SG_ 288 CAN_DET_AZIMUTH_01_04 "CAN_DET_AZIMUTH_01_04";
BA_ "GenSigSendType" SG_ 288 CAN_DET_RANGE_01_04 0;
BA_ "GenSigCmt" SG_ 288 CAN_DET_RANGE_01_04 "CAN_DET_RANGE_01_04";
BA_ "GenSigSendType" SG_ 288 CAN_DET_RANGE_RATE_01_04 0;
BA_ "GenSigCmt" SG_ 288 CAN_DET_RANGE_RATE_01_04 "CAN_DET_RANGE_RATE_01_04";
BA_ "GenSigSendType" SG_ 288 CAN_DET_AMPLITUDE_01_04 0;
BA_ "GenSigCmt" SG_ 288 CAN_DET_AMPLITUDE_01_04 "CAN_DET_AMPLITUDE_01_04";
BA_ "GenSigSendType" SG_ 288 CAN_SCAN_INDEX_2LSB_01_04 0;
BA_ "GenSigCmt" SG_ 288 CAN_SCAN_INDEX_2LSB_01_04 "CAN_SCAN_INDEX_2LSB_01_04";
BA_ "GenSigVtEn" SG_ 288 CAN_DET_CONFID_AZIMUTH_01_05 "CAN_DET_CONFID_AZIMUTH_01_05";
BA_ "GenSigVtName" SG_ 288 CAN_DET_CONFID_AZIMUTH_01_05 "CAN_DET_CONFID_AZIMUTH_01_05";
BA_ "GenSigSendType" SG_ 288 CAN_DET_CONFID_AZIMUTH_01_05 0;
BA_ "GenSigCmt" SG_ 288 CAN_DET_CONFID_AZIMUTH_01_05 "CAN_DET_CONFID_AZIMUTH_01_05";
BA_ "GenSigSendType" SG_ 288 CAN_DET_SUPER_RES_TARGET_01_05 0;
BA_ "GenSigCmt" SG_ 288 CAN_DET_SUPER_RES_TARGET_01_05 "CAN_DET_SUPER_RES_TARGET_01_05";
BA_ "GenSigSendType" SG_ 288 CAN_DET_ND_TARGET_01_05 0;
BA_ "GenSigCmt" SG_ 288 CAN_DET_ND_TARGET_01_05 "CAN_DET_ND_TARGET_01_05";
BA_ "GenSigSendType" SG_ 288 CAN_DET_HOST_VEH_CLUTTER_01_05 0;
BA_ "GenSigCmt" SG_ 288 CAN_DET_HOST_VEH_CLUTTER_01_05 "CAN_DET_HOST_VEH_CLUTTER_01_05";
BA_ "GenSigSendType" SG_ 288 CAN_DET_VALID_LEVEL_01_05 0;
BA_ "GenSigCmt" SG_ 288 CAN_DET_VALID_LEVEL_01_05 "CAN_DET_VALID_LEVEL_01_05";
BA_ "GenSigSendType" SG_ 288 CAN_DET_AZIMUTH_01_05 0;
BA_ "GenSigCmt" SG_ 288 CAN_DET_AZIMUTH_01_05 "CAN_DET_AZIMUTH_01_05";
BA_ "GenSigSendType" SG_ 288 CAN_DET_RANGE_01_05 0;
BA_ "GenSigCmt" SG_ 288 CAN_DET_RANGE_01_05 "CAN_DET_RANGE_01_05";
BA_ "GenSigSendType" SG_ 288 CAN_DET_RANGE_RATE_01_05 0;
BA_ "GenSigCmt" SG_ 288 CAN_DET_RANGE_RATE_01_05 "CAN_DET_RANGE_RATE_01_05";
BA_ "GenSigSendType" SG_ 288 CAN_DET_AMPLITUDE_01_05 0;
BA_ "GenSigCmt" SG_ 288 CAN_DET_AMPLITUDE_01_05 "CAN_DET_AMPLITUDE_01_05";
BA_ "GenSigSendType" SG_ 288 CAN_SCAN_INDEX_2LSB_01_05 0;
BA_ "GenSigCmt" SG_ 288 CAN_SCAN_INDEX_2LSB_01_05 "CAN_SCAN_INDEX_2LSB_01_05";
BA_ "GenSigVtEn" SG_ 288 CAN_DET_CONFID_AZIMUTH_01_06 "CAN_DET_CONFID_AZIMUTH_01_06";
BA_ "GenSigVtName" SG_ 288 CAN_DET_CONFID_AZIMUTH_01_06 "CAN_DET_CONFID_AZIMUTH_01_06";
BA_ "GenSigSendType" SG_ 288 CAN_DET_CONFID_AZIMUTH_01_06 0;
BA_ "GenSigCmt" SG_ 288 CAN_DET_CONFID_AZIMUTH_01_06 "CAN_DET_CONFID_AZIMUTH_01_06";
BA_ "GenSigSendType" SG_ 288 CAN_DET_SUPER_RES_TARGET_01_06 0;
BA_ "GenSigCmt" SG_ 288 CAN_DET_SUPER_RES_TARGET_01_06 "CAN_DET_SUPER_RES_TARGET_01_06";
BA_ "GenSigSendType" SG_ 288 CAN_DET_ND_TARGET_01_06 0;
BA_ "GenSigCmt" SG_ 288 CAN_DET_ND_TARGET_01_06 "CAN_DET_ND_TARGET_01_06";
BA_ "GenSigSendType" SG_ 288 CAN_DET_HOST_VEH_CLUTTER_01_06 0;
BA_ "GenSigCmt" SG_ 288 CAN_DET_HOST_VEH_CLUTTER_01_06 "CAN_DET_HOST_VEH_CLUTTER_01_06";
BA_ "GenSigSendType" SG_ 288 CAN_DET_VALID_LEVEL_01_06 0;
BA_ "GenSigCmt" SG_ 288 CAN_DET_VALID_LEVEL_01_06 "CAN_DET_VALID_LEVEL_01_06";
BA_ "GenSigSendType" SG_ 288 CAN_DET_AZIMUTH_01_06 0;
BA_ "GenSigCmt" SG_ 288 CAN_DET_AZIMUTH_01_06 "CAN_DET_AZIMUTH_01_06";
BA_ "GenSigSendType" SG_ 288 CAN_DET_RANGE_01_06 0;
BA_ "GenSigCmt" SG_ 288 CAN_DET_RANGE_01_06 "CAN_DET_RANGE_01_06";
BA_ "GenSigSendType" SG_ 288 CAN_DET_RANGE_RATE_01_06 0;
BA_ "GenSigCmt" SG_ 288 CAN_DET_RANGE_RATE_01_06 "CAN_DET_RANGE_RATE_01_06";
BA_ "GenSigSendType" SG_ 288 CAN_DET_AMPLITUDE_01_06 0;
BA_ "GenSigCmt" SG_ 288 CAN_DET_AMPLITUDE_01_06 "CAN_DET_AMPLITUDE_01_06";
BA_ "GenSigSendType" SG_ 288 CAN_SCAN_INDEX_2LSB_01_06 0;
BA_ "GenSigCmt" SG_ 288 CAN_SCAN_INDEX_2LSB_01_06 "CAN_SCAN_INDEX_2LSB_01_06";
BA_DEF_DEF_ "UsedOnPgmDBC" "Yes";
BA_DEF_DEF_ "DiagResponse" "No";
BA_DEF_DEF_ "EventRateOfChange" 10000;
BA_DEF_DEF_ "GenSigVtName" "";
BA_DEF_DEF_ "GenSigVtEn" "";
BA_DEF_DEF_ "GenSigCmt" "";
BA_DEF_DEF_ "GenSigSendType" "NoSigSendType";
BA_DEF_DEF_ "GenSigStartValue" 0;
BA_DEF_DEF_ "GenMsgILSupport" "Yes";
BA_DEF_DEF_ "GenMsgSendType" "NoMsgSendType";
BA_DEF_DEF_ "GenMsgCycleTime" 0;
BA_DEF_DEF_ "GenMsgDelayTime" 0;
BA_DEF_DEF_ "GenMsgNrOfRepetition" 0;
BA_DEF_DEF_ "NetworkInitialization" "No";
BA_DEF_DEF_ "GenMsgBackgroundColor" "#ffffff";
BA_DEF_DEF_ "GenMsgForegroundColor" "#000000";
VAL_ 298 CAN_DET_CONFID_AZIMUTH_11_01 3 "Low" 2 "Medium_Low" 1 "Medium_High" 0 "High";
VAL_ 298 CAN_DET_CONFID_AZIMUTH_11_02 3 "Low" 2 "Medium_Low" 1 "Medium_High" 0 "High";
VAL_ 298 CAN_DET_CONFID_AZIMUTH_11_03 3 "Low" 2 "Medium_Low" 1 "Medium_High" 0 "High";
VAL_ 298 CAN_DET_CONFID_AZIMUTH_11_04 3 "Low" 2 "Medium_Low" 1 "Medium_High" 0 "High";
VAL_ 298 CAN_DET_CONFID_AZIMUTH_11_05 3 "Low" 2 "Medium_Low" 1 "Medium_High" 0 "High";
VAL_ 298 CAN_DET_CONFID_AZIMUTH_11_06 3 "Low" 2 "Medium_Low" 1 "Medium_High" 0 "High";
VAL_ 297 CAN_DET_CONFID_AZIMUTH_10_01 3 "Low" 2 "Medium_Low" 1 "Medium_High" 0 "High";
VAL_ 297 CAN_DET_CONFID_AZIMUTH_10_02 3 "Low" 2 "Medium_Low" 1 "Medium_High" 0 "High";
VAL_ 297 CAN_DET_CONFID_AZIMUTH_10_03 3 "Low" 2 "Medium_Low" 1 "Medium_High" 0 "High";
VAL_ 297 CAN_DET_CONFID_AZIMUTH_10_04 3 "Low" 2 "Medium_Low" 1 "Medium_High" 0 "High";
VAL_ 297 CAN_DET_CONFID_AZIMUTH_10_05 3 "Low" 2 "Medium_Low" 1 "Medium_High" 0 "High";
VAL_ 297 CAN_DET_CONFID_AZIMUTH_10_06 3 "Low" 2 "Medium_Low" 1 "Medium_High" 0 "High";
VAL_ 296 CAN_DET_CONFID_AZIMUTH_09_01 3 "Low" 2 "Medium_Low" 1 "Medium_High" 0 "High";
VAL_ 296 CAN_DET_CONFID_AZIMUTH_09_02 3 "Low" 2 "Medium_Low" 1 "Medium_High" 0 "High";
VAL_ 296 CAN_DET_CONFID_AZIMUTH_09_03 3 "Low" 2 "Medium_Low" 1 "Medium_High" 0 "High";
VAL_ 296 CAN_DET_CONFID_AZIMUTH_09_04 3 "Low" 2 "Medium_Low" 1 "Medium_High" 0 "High";
VAL_ 296 CAN_DET_CONFID_AZIMUTH_09_05 3 "Low" 2 "Medium_Low" 1 "Medium_High" 0 "High";
VAL_ 296 CAN_DET_CONFID_AZIMUTH_09_06 3 "Low" 2 "Medium_Low" 1 "Medium_High" 0 "High";
VAL_ 295 CAN_DET_CONFID_AZIMUTH_08_01 3 "Low" 2 "Medium_Low" 1 "Medium_High" 0 "High";
VAL_ 295 CAN_DET_CONFID_AZIMUTH_08_02 3 "Low" 2 "Medium_Low" 1 "Medium_High" 0 "High";
VAL_ 295 CAN_DET_CONFID_AZIMUTH_08_03 3 "Low" 2 "Medium_Low" 1 "Medium_High" 0 "High";
VAL_ 295 CAN_DET_CONFID_AZIMUTH_08_04 3 "Low" 2 "Medium_Low" 1 "Medium_High" 0 "High";
VAL_ 295 CAN_DET_CONFID_AZIMUTH_08_05 3 "Low" 2 "Medium_Low" 1 "Medium_High" 0 "High";
VAL_ 295 CAN_DET_CONFID_AZIMUTH_08_06 3 "Low" 2 "Medium_Low" 1 "Medium_High" 0 "High";
VAL_ 294 CAN_DET_CONFID_AZIMUTH_07_01 3 "Low" 2 "Medium_Low" 1 "Medium_High" 0 "High";
VAL_ 294 CAN_DET_CONFID_AZIMUTH_07_02 3 "Low" 2 "Medium_Low" 1 "Medium_High" 0 "High";
VAL_ 294 CAN_DET_CONFID_AZIMUTH_07_03 3 "Low" 2 "Medium_Low" 1 "Medium_High" 0 "High";
VAL_ 294 CAN_DET_CONFID_AZIMUTH_07_04 3 "Low" 2 "Medium_Low" 1 "Medium_High" 0 "High";
VAL_ 294 CAN_DET_CONFID_AZIMUTH_07_05 3 "Low" 2 "Medium_Low" 1 "Medium_High" 0 "High";
VAL_ 294 CAN_DET_CONFID_AZIMUTH_07_06 3 "Low" 2 "Medium_Low" 1 "Medium_High" 0 "High";
VAL_ 293 CAN_DET_CONFID_AZIMUTH_06_01 3 "Low" 2 "Medium_Low" 1 "Medium_High" 0 "High";
VAL_ 293 CAN_DET_CONFID_AZIMUTH_06_02 3 "Low" 2 "Medium_Low" 1 "Medium_High" 0 "High";
VAL_ 293 CAN_DET_CONFID_AZIMUTH_06_03 3 "Low" 2 "Medium_Low" 1 "Medium_High" 0 "High";
VAL_ 293 CAN_DET_CONFID_AZIMUTH_06_04 3 "Low" 2 "Medium_Low" 1 "Medium_High" 0 "High";
VAL_ 293 CAN_DET_CONFID_AZIMUTH_06_05 3 "Low" 2 "Medium_Low" 1 "Medium_High" 0 "High";
VAL_ 293 CAN_DET_CONFID_AZIMUTH_06_06 3 "Low" 2 "Medium_Low" 1 "Medium_High" 0 "High";
VAL_ 292 CAN_DET_CONFID_AZIMUTH_05_01 3 "Low" 2 "Medium_Low" 1 "Medium_High" 0 "High";
VAL_ 292 CAN_DET_CONFID_AZIMUTH_05_02 3 "Low" 2 "Medium_Low" 1 "Medium_High" 0 "High";
VAL_ 292 CAN_DET_CONFID_AZIMUTH_05_03 3 "Low" 2 "Medium_Low" 1 "Medium_High" 0 "High";
VAL_ 292 CAN_DET_CONFID_AZIMUTH_05_04 3 "Low" 2 "Medium_Low" 1 "Medium_High" 0 "High";
VAL_ 292 CAN_DET_CONFID_AZIMUTH_05_05 3 "Low" 2 "Medium_Low" 1 "Medium_High" 0 "High";
VAL_ 292 CAN_DET_CONFID_AZIMUTH_05_06 3 "Low" 2 "Medium_Low" 1 "Medium_High" 0 "High";
VAL_ 290 CAN_DET_CONFID_AZIMUTH_03_01 3 "Low" 2 "Medium_Low" 1 "Medium_High" 0 "High";
VAL_ 290 CAN_DET_CONFID_AZIMUTH_03_02 3 "Low" 2 "Medium_Low" 1 "Medium_High" 0 "High";
VAL_ 290 CAN_DET_CONFID_AZIMUTH_03_03 3 "Low" 2 "Medium_Low" 1 "Medium_High" 0 "High";
VAL_ 290 CAN_DET_CONFID_AZIMUTH_03_04 3 "Low" 2 "Medium_Low" 1 "Medium_High" 0 "High";
VAL_ 290 CAN_DET_CONFID_AZIMUTH_03_05 3 "Low" 2 "Medium_Low" 1 "Medium_High" 0 "High";
VAL_ 290 CAN_DET_CONFID_AZIMUTH_03_06 3 "Low" 2 "Medium_Low" 1 "Medium_High" 0 "High";
VAL_ 289 CAN_DET_CONFID_AZIMUTH_02_01 3 "Low" 2 "Medium_Low" 1 "Medium_High" 0 "High";
VAL_ 289 CAN_DET_CONFID_AZIMUTH_02_02 3 "Low" 2 "Medium_Low" 1 "Medium_High" 0 "High";
VAL_ 289 CAN_DET_CONFID_AZIMUTH_02_03 3 "Low" 2 "Medium_Low" 1 "Medium_High" 0 "High";
VAL_ 289 CAN_DET_CONFID_AZIMUTH_02_04 3 "Low" 2 "Medium_Low" 1 "Medium_High" 0 "High";
VAL_ 289 CAN_DET_CONFID_AZIMUTH_02_05 3 "Low" 2 "Medium_Low" 1 "Medium_High" 0 "High";
VAL_ 289 CAN_DET_CONFID_AZIMUTH_02_06 3 "Low" 2 "Medium_Low" 1 "Medium_High" 0 "High";
VAL_ 257 CAN_INTERFERENCE_TYPE 2 "Star PD-Like" 1 "Slow FMCW" 0 "No Interference";
VAL_ 257 CAN_RECOMMEND_UNCONVERGE 1 "Recommended" 0 "Not Recommended";
VAL_ 257 CAN_RADAR_ALIGN_INCOMPLETE 1 "Alignment Incomplete" 0 "Alignment Completed";
VAL_ 257 CAN_BLOCKAGE_SIDELOBE 1 "Radar Blockage" 0 "No Radar Blockage";
VAL_ 257 CAN_BLOCKAGE_MNR 1 "Radar Blockage" 0 "No Radar Blockage";
VAL_ 257 CAN_RADAR_EXT_COND_NOK 1 "Too high temp or insufficient pw" 0 "External conditions OK";
VAL_ 257 CAN_RADAR_ALIGN_OUT_RANGE 1 "Radar out of range" 0 "Radar within range";
VAL_ 257 CAN_RADAR_ALIGN_NOT_START 1 "Radar align not started" 0 "Radar align started";
VAL_ 257 CAN_RADAR_OVERHEAT_ERROR 1 "Radar overheat condition" 0 "No Overheat";
VAL_ 257 CAN_RADAR_NOT_OP 1 "Radar not operational" 0 "Radar operational";
VAL_ 257 CAN_XCVR_OPERATIONAL 1 "On" 0 "Off ";
VAL_ 288 CAN_DET_CONFID_AZIMUTH_01_01 3 "Low" 2 "Medium_Low" 1 "Medium_High" 0 "High";
VAL_ 288 CAN_DET_CONFID_AZIMUTH_01_02 3 "Low" 2 "Medium_Low" 1 "Medium_High" 0 "High";
VAL_ 288 CAN_DET_CONFID_AZIMUTH_01_03 3 "Low" 2 "Medium_Low" 1 "Medium_High" 0 "High";
VAL_ 288 CAN_DET_CONFID_AZIMUTH_01_04 3 "Low" 2 "Medium_Low" 1 "Medium_High" 0 "High";
VAL_ 288 CAN_DET_CONFID_AZIMUTH_01_05 3 "Low" 2 "Medium_Low" 1 "Medium_High" 0 "High";
VAL_ 288 CAN_DET_CONFID_AZIMUTH_01_06 3 "Low" 2 "Medium_Low" 1 "Medium_High" 0 "High";
